VERSION "HNNBNNNYNNNNNNNNNNNNNNNNNNNNNNNNNNNNNNNNNN/4/%%%/4/'%**4NNN///"

NS_ :

BS_:

BU_: AEM BAP_Tester E_Sound FLA Gateway Gateway_PAG ISE MRR_HL MRR_HR NightVision RDK SAK SAK2 SCR STH_MLBevo TopView

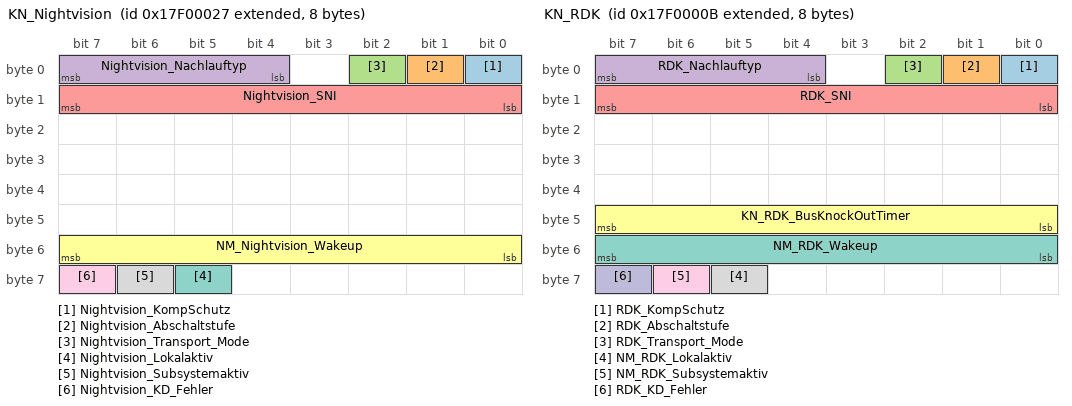
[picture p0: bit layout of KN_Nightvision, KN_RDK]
BO_ 2549088295 KN_Nightvision: 8 NightVision
 SG_ Nightvision_KompSchutz : 0|1@1+ (1.0,0.0) [0.0|1] ""  Vector__XXX
 SG_ Nightvision_Abschaltstufe : 1|1@1+ (1.0,0.0) [0.0|1] ""  Vector__XXX
 SG_ Nightvision_Transport_Mode : 2|1@1+ (1.0,0.0) [0.0|1] ""  Vector__XXX
 SG_ Nightvision_Nachlauftyp : 4|4@1+ (1.0,0.0) [0.0|15] ""  Gateway,Gateway_PAG
 SG_ Nightvision_SNI : 8|8@1+ (1.0,0.0) [0.0|255] ""  Gateway,Gateway_PAG
 SG_ NM_Nightvision_Wakeup : 48|8@1+ (1.0,0.0) [0.0|255] ""  Vector__XXX
 SG_ Nightvision_Lokalaktiv : 61|1@1+ (1.0,0.0) [0.0|1] ""  Vector__XXX
 SG_ Nightvision_Subsystemaktiv : 62|1@1+ (1.0,0.0) [0.0|1] ""  Vector__XXX
 SG_ Nightvision_KD_Fehler : 63|1@1+ (1.0,0.0) [0.0|1] ""  Gateway,Gateway_PAG

BO_ 2549088267 KN_RDK: 8 RDK
 SG_ RDK_KompSchutz : 0|1@1+ (1.0,0.0) [0.0|1] ""  Vector__XXX
 SG_ RDK_Abschaltstufe : 1|1@1+ (1.0,0.0) [0.0|1] ""  Vector__XXX
 SG_ RDK_Transport_Mode : 2|1@1+ (1.0,0.0) [0.0|1] ""  Vector__XXX
 SG_ RDK_Nachlauftyp : 4|4@1+ (1.0,0.0) [0.0|15] ""  Gateway,Gateway_PAG
 SG_ RDK_SNI : 8|8@1+ (1.0,0.0) [0.0|255] ""  Gateway,Gateway_PAG
 SG_ KN_RDK_BusKnockOutTimer : 40|8@1+ (1,0) [0|254] ""  Gateway,Gateway_PAG
 SG_ NM_RDK_Wakeup : 48|8@1+ (1.0,0.0) [0.0|255] ""  Vector__XXX
 SG_ NM_RDK_Lokalaktiv : 61|1@1+ (1.0,0.0) [0.0|1] ""  Gateway,Gateway_PAG
 SG_ NM_RDK_Subsystemaktiv : 62|1@1+ (1.0,0.0) [0.0|1] ""  Vector__XXX
 SG_ RDK_KD_Fehler : 63|1@1+ (1.0,0.0) [0.0|1] ""  Gateway,Gateway_PAG

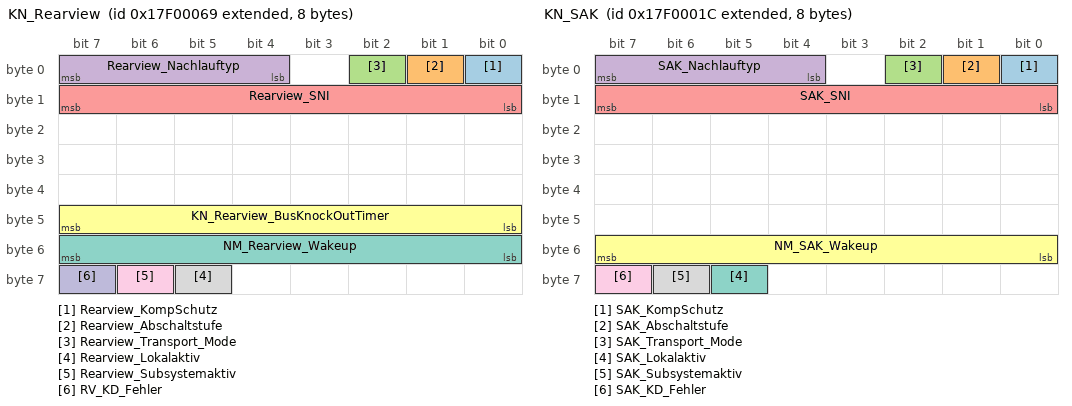
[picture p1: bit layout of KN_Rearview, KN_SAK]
BO_ 2549088361 KN_Rearview: 8 TopView
 SG_ Rearview_KompSchutz : 0|1@1+ (1.0,0.0) [0.0|1] ""  Vector__XXX
 SG_ Rearview_Abschaltstufe : 1|1@1+ (1.0,0.0) [0.0|1] ""  Vector__XXX
 SG_ Rearview_Transport_Mode : 2|1@1+ (1.0,0.0) [0.0|1] ""  Vector__XXX
 SG_ Rearview_Nachlauftyp : 4|4@1+ (1.0,0.0) [0.0|15] ""  Gateway,Gateway_PAG
 SG_ Rearview_SNI : 8|8@1+ (1.0,0.0) [0.0|255] ""  Gateway,Gateway_PAG
 SG_ KN_Rearview_BusKnockOutTimer : 40|8@1+ (1,0) [0|254] ""  Gateway,Gateway_PAG
 SG_ NM_Rearview_Wakeup : 48|8@1+ (1.0,0.0) [0.0|255] ""  Vector__XXX
 SG_ Rearview_Lokalaktiv : 61|1@1+ (1.0,0.0) [0.0|1] ""  Gateway,Gateway_PAG
 SG_ Rearview_Subsystemaktiv : 62|1@1+ (1.0,0.0) [0.0|1] ""  Vector__XXX
 SG_ RV_KD_Fehler : 63|1@1+ (1.0,0.0) [0.0|1] ""  Gateway,Gateway_PAG

BO_ 2549088284 KN_SAK: 8 ISE
 SG_ SAK_KompSchutz : 0|1@1+ (1.0,0.0) [0.0|1] ""  Vector__XXX
 SG_ SAK_Abschaltstufe : 1|1@1+ (1.0,0.0) [0.0|1] ""  Vector__XXX
 SG_ SAK_Transport_Mode : 2|1@1+ (1.0,0.0) [0.0|1] ""  Vector__XXX
 SG_ SAK_Nachlauftyp : 4|4@1+ (1.0,0.0) [0.0|15] ""  Gateway,Gateway_PAG
 SG_ SAK_SNI : 8|8@1+ (1.0,0.0) [0.0|255] ""  Gateway,Gateway_PAG
 SG_ NM_SAK_Wakeup : 48|8@1+ (1.0,0.0) [0.0|255] ""  Vector__XXX
 SG_ SAK_Lokalaktiv : 61|1@1+ (1.0,0.0) [0.0|1] ""  Vector__XXX
 SG_ SAK_Subsystemaktiv : 62|1@1+ (1.0,0.0) [0.0|1] ""  Vector__XXX
 SG_ SAK_KD_Fehler : 63|1@1+ (1.0,0.0) [0.0|1] ""  Gateway,Gateway_PAG

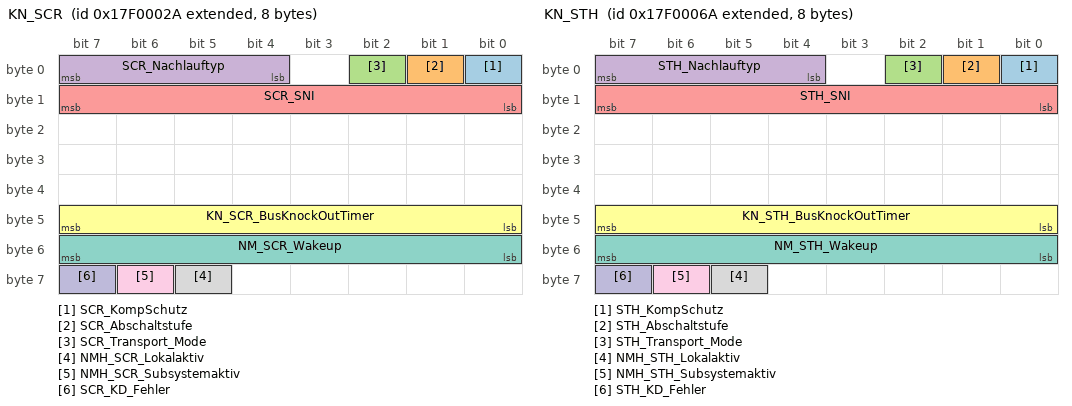
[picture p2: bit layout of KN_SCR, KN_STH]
BO_ 2549088298 KN_SCR: 8 SCR
 SG_ SCR_KompSchutz : 0|1@1+ (1.0,0.0) [0.0|1] ""  Vector__XXX
 SG_ SCR_Abschaltstufe : 1|1@1+ (1.0,0.0) [0.0|1] ""  Vector__XXX
 SG_ SCR_Transport_Mode : 2|1@1+ (1.0,0.0) [0.0|1] ""  Vector__XXX
 SG_ SCR_Nachlauftyp : 4|4@1+ (1.0,0.0) [0.0|15] ""  Gateway,Gateway_PAG
 SG_ SCR_SNI : 8|8@1+ (1.0,0.0) [0.0|255] ""  Gateway,Gateway_PAG
 SG_ KN_SCR_BusKnockOutTimer : 40|8@1+ (1,0) [0|254] ""  Gateway,Gateway_PAG
 SG_ NM_SCR_Wakeup : 48|8@1+ (1.0,0.0) [0.0|255] ""  Vector__XXX
 SG_ NMH_SCR_Lokalaktiv : 61|1@1+ (1.0,0.0) [0.0|1] ""  Gateway,Gateway_PAG
 SG_ NMH_SCR_Subsystemaktiv : 62|1@1+ (1.0,0.0) [0.0|1] ""  Vector__XXX
 SG_ SCR_KD_Fehler : 63|1@1+ (1.0,0.0) [0.0|1] ""  Gateway,Gateway_PAG

BO_ 2549088362 KN_STH: 8 STH_MLBevo
 SG_ STH_KompSchutz : 0|1@1+ (1.0,0.0) [0.0|1] ""  Vector__XXX
 SG_ STH_Abschaltstufe : 1|1@1+ (1.0,0.0) [0.0|1] ""  Vector__XXX
 SG_ STH_Transport_Mode : 2|1@1+ (1.0,0.0) [0.0|1] ""  Vector__XXX
 SG_ STH_Nachlauftyp : 4|4@1+ (1.0,0.0) [0.0|15] ""  Gateway,Gateway_PAG
 SG_ STH_SNI : 8|8@1+ (1.0,0.0) [0.0|255] ""  Gateway,Gateway_PAG
 SG_ KN_STH_BusKnockOutTimer : 40|8@1+ (1,0) [0|254] ""  Gateway,Gateway_PAG
 SG_ NM_STH_Wakeup : 48|8@1+ (1.0,0.0) [0.0|255] ""  Vector__XXX
 SG_ NMH_STH_Lokalaktiv : 61|1@1+ (1.0,0.0) [0.0|1] ""  Gateway,Gateway_PAG
 SG_ NMH_STH_Subsystemaktiv : 62|1@1+ (1.0,0.0) [0.0|1] ""  Gateway,Gateway_PAG
 SG_ STH_KD_Fehler : 63|1@1+ (1.0,0.0) [0.0|1] ""  Gateway,Gateway_PAG

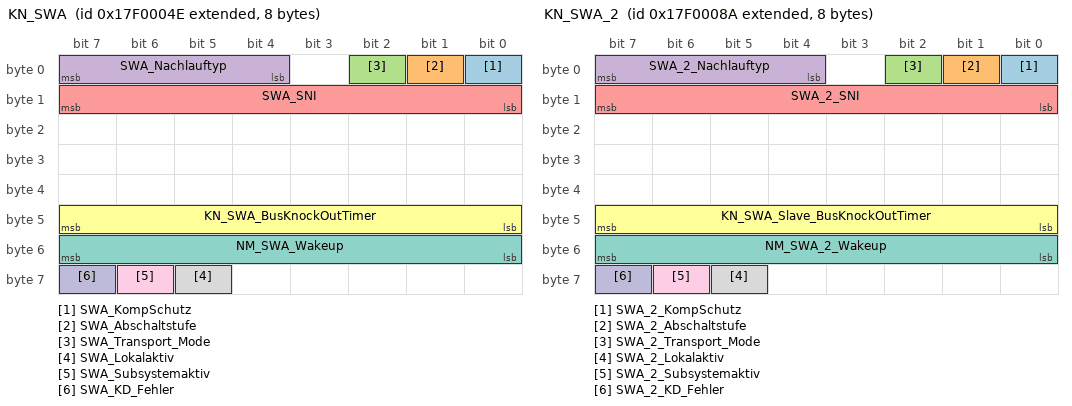
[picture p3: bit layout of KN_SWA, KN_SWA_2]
BO_ 2549088334 KN_SWA: 8 MRR_HR
 SG_ SWA_KompSchutz : 0|1@1+ (1.0,0.0) [0.0|1] ""  Vector__XXX
 SG_ SWA_Abschaltstufe : 1|1@1+ (1.0,0.0) [0.0|1] ""  Vector__XXX
 SG_ SWA_Transport_Mode : 2|1@1+ (1.0,0.0) [0.0|1] ""  Vector__XXX
 SG_ SWA_Nachlauftyp : 4|4@1+ (1.0,0.0) [0.0|15] ""  Gateway,Gateway_PAG
 SG_ SWA_SNI : 8|8@1+ (1.0,0.0) [0.0|255] ""  Gateway,Gateway_PAG
 SG_ KN_SWA_BusKnockOutTimer : 40|8@1+ (1,0) [0|254] ""  Gateway,Gateway_PAG
 SG_ NM_SWA_Wakeup : 48|8@1+ (1.0,0.0) [0.0|255] ""  Vector__XXX
 SG_ SWA_Lokalaktiv : 61|1@1+ (1.0,0.0) [0.0|1] ""  Gateway,Gateway_PAG
 SG_ SWA_Subsystemaktiv : 62|1@1+ (1.0,0.0) [0.0|1] ""  Vector__XXX
 SG_ SWA_KD_Fehler : 63|1@1+ (1.0,0.0) [0.0|1] ""  Gateway,Gateway_PAG

BO_ 2549088394 KN_SWA_2: 8 MRR_HL
 SG_ SWA_2_KompSchutz : 0|1@1+ (1.0,0.0) [0.0|1] ""  Vector__XXX
 SG_ SWA_2_Abschaltstufe : 1|1@1+ (1.0,0.0) [0.0|1] ""  Vector__XXX
 SG_ SWA_2_Transport_Mode : 2|1@1+ (1.0,0.0) [0.0|1] ""  Vector__XXX
 SG_ SWA_2_Nachlauftyp : 4|4@1+ (1.0,0.0) [0.0|15] ""  Gateway,Gateway_PAG
 SG_ SWA_2_SNI : 8|8@1+ (1.0,0.0) [0.0|255] ""  Gateway,Gateway_PAG
 SG_ KN_SWA_Slave_BusKnockOutTimer : 40|8@1+ (1,0) [0|254] ""  Gateway,Gateway_PAG
 SG_ NM_SWA_2_Wakeup : 48|8@1+ (1.0,0.0) [0.0|255] ""  Vector__XXX
 SG_ SWA_2_Lokalaktiv : 61|1@1+ (1.0,0.0) [0.0|1] ""  Gateway,Gateway_PAG
 SG_ SWA_2_Subsystemaktiv : 62|1@1+ (1.0,0.0) [0.0|1] ""  Vector__XXX
 SG_ SWA_2_KD_Fehler : 63|1@1+ (1.0,0.0) [0.0|1] ""  Gateway,Gateway_PAG

BO_ 779 Kombi_01: 8 Gateway
 SG_ KBI_ABS_Lampe : 0|1@1+ (1.0,0.0) [0.0|1] ""  Vector__XXX
 SG_ KBI_ESP_Lampe : 1|1@1+ (1.0,0.0) [0.0|1] ""  TopView
 SG_ KBI_BKL_Lampe : 2|1@1+ (1.0,0.0) [0.0|1] ""  Vector__XXX
 SG_ KBI_Airbag_Lampe : 3|1@1+ (1.0,0.0) [0.0|1] ""  Vector__XXX
 SG_ KBI_SILA_gueltig : 4|1@1+ (1.0,0.0) [0.0|1] ""  Vector__XXX
 SG_ KBI_Lenkung_Lampe : 5|1@1+ (1,0) [0|1] ""  Vector__XXX
 SG_ KBI_Vorglueh_System_Lampe : 6|1@1+ (1.0,0.0) [0.0|1] ""  Vector__XXX
 SG_ KBI_NV_in_Anzeige : 7|1@1+ (1.0,0.0) [0.0|1] ""  NightVision
 SG_ Kombi_01_BZ : 8|4@1+ (1,0) [0|15] ""  Vector__XXX
 SG_ KBI_Anzeigestatus_ACC : 12|1@1+ (1.0,0.0) [0.0|1] ""  Vector__XXX
 SG_ KBI_Anzeigestatus_GRA : 13|2@1+ (1.0,0.0) [0.0|3] ""  Vector__XXX
 SG_ KBI_Tankwarnung : 16|1@1+ (1.0,0.0) [0.0|1] ""  STH_MLBevo
 SG_ KBI_MFA_v_Einheit_01 : 17|1@1+ (1.0,0.0) [0.0|1] ""  RDK
 SG_ KBI_im_Stellgliedtest : 18|1@1+ (1.0,0.0) [0.0|1] ""  Vector__XXX
 SG_ KBI_Anzeigefehler_LDW : 19|2@1+ (1.0,0.0) [0.0|3] ""  Vector__XXX
 SG_ KBI_Tankwarnung_ungueltig : 21|1@1+ (1.0,0.0) [0.0|1] ""  Vector__XXX
 SG_ KBI_Handbremse : 23|1@1+ (1.0,0.0) [0.0|1] ""  Vector__XXX
 SG_ KBI_V_Digital : 24|9@1+ (1,0) [0|511] ""  MRR_HL,MRR_HR,RDK
 SG_ KBI_PLA_in_Anzeige : 33|1@1+ (1.0,0.0) [0.0|1] ""  Vector__XXX
 SG_ KBI_Anzeigefehler_NV : 34|1@1+ (1.0,0.0) [0.0|1] ""  NightVision
 SG_ KBI_Anzeigestatus_LIM : 35|2@1+ (1.0,0.0) [0.0|3] ""  Vector__XXX
 SG_ KBI_ARA_in_Anzeige : 37|1@1+ (1.0,0.0) [0.0|1] ""  Vector__XXX
 SG_ KBI_Taster_Lift : 38|1@1+ (1.0,0.0) [0.0|1] ""  Vector__XXX
 SG_ KBI_Taster_Fahrwerk : 39|1@1+ (1.0,0.0) [0.0|1] ""  Vector__XXX
 SG_ KBI_angez_Geschw : 48|10@1+ (0.32,0) [0.00|325.12] "Unit_KiloMeterPerHour"  MRR_HL,MRR_HR
 SG_ KBI_Einheit_Tacho : 58|1@1+ (1.0,0.0) [0.0|1] ""  Vector__XXX
 SG_ KBI_Konsistenz_ACC : 59|1@1+ (1.0,0.0) [0.0|1] ""  Vector__XXX
 SG_ KBI_Fehler_Anzeige_ACC : 60|1@1+ (1.0,0.0) [0.0|1] ""  Vector__XXX
 SG_ KBI_Anzeigefehler_SWA : 61|2@1+ (1.0,0.0) [0.0|3] ""  MRR_HR
 SG_ KBI_Systemstatus : 63|1@1+ (1.0,0.0) [0.0|1] ""  Vector__XXX

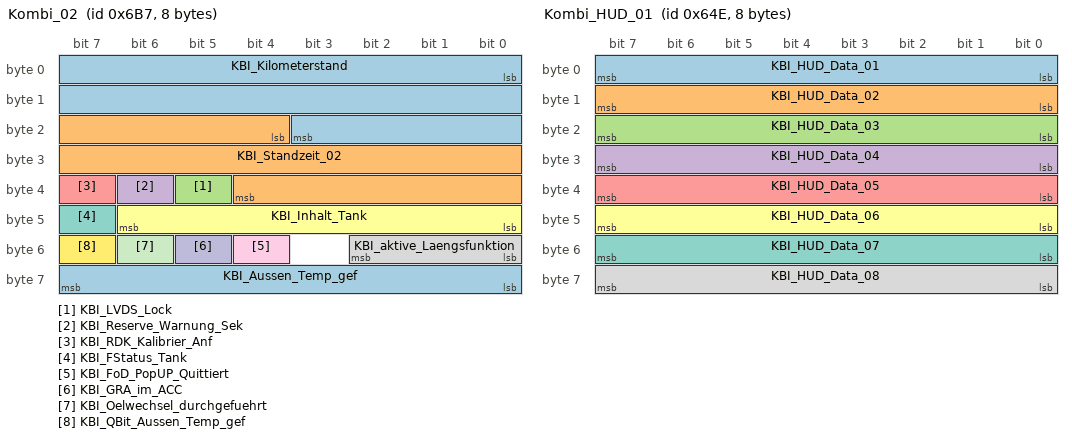
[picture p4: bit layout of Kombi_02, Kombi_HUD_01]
BO_ 1719 Kombi_02: 8 Gateway
 SG_ KBI_Kilometerstand : 0|20@1+ (1,0) [0|1048573] "Unit_KiloMeter"  Vector__XXX
 SG_ KBI_Standzeit_02 : 20|17@1+ (1,0) [0|131068] "Unit_Secon"  STH_MLBevo
 SG_ KBI_LVDS_Lock : 37|1@1+ (1.0,0.0) [0.0|1] ""  Vector__XXX
 SG_ KBI_Reserve_Warnung_Sek : 38|1@1+ (1.0,0.0) [0.0|1] ""  Vector__XXX
 SG_ KBI_RDK_Kalibrier_Anf : 39|1@1+ (1.0,0.0) [0.0|1] ""  RDK
 SG_ KBI_Inhalt_Tank : 40|7@1+ (1,0) [0|125] "Unit_Liter"  STH_MLBevo
 SG_ KBI_FStatus_Tank : 47|1@1+ (1.0,0.0) [0.0|1] ""  STH_MLBevo
 SG_ KBI_aktive_Laengsfunktion : 48|3@1+ (1.0,0.0) [0.0|7] ""  Vector__XXX
 SG_ KBI_FoD_PopUP_Quittiert : 52|1@1+ (1.0,0.0) [0.0|1] ""  Vector__XXX
 SG_ KBI_GRA_im_ACC : 53|1@1+ (1.0,0.0) [0.0|1] ""  Vector__XXX
 SG_ KBI_Oelwechsel_durchgefuehrt : 54|1@1+ (1.0,0.0) [0.0|1] ""  Vector__XXX
 SG_ KBI_QBit_Aussen_Temp_gef : 55|1@1+ (1.0,0.0) [0.0|1] ""  NightVision,RDK,STH_MLBevo
 SG_ KBI_Aussen_Temp_gef : 56|8@1+ (0.5,-50) [-50.0|75.0] "Unit_DegreCelsi"  AEM,NightVision,RDK,SAK2,SCR,STH_MLBevo

BO_ 1614 Kombi_HUD_01: 8 Gateway
 SG_ KBI_HUD_Data_01 : 0|8@1+ (1.0,0.0) [0.0|255] ""  NightVision
 SG_ KBI_HUD_Data_02 : 8|8@1+ (1.0,0.0) [0.0|255] ""  NightVision
 SG_ KBI_HUD_Data_03 : 16|8@1+ (1.0,0.0) [0.0|255] ""  NightVision
 SG_ KBI_HUD_Data_04 : 24|8@1+ (1.0,0.0) [0.0|255] ""  NightVision
 SG_ KBI_HUD_Data_05 : 32|8@1+ (1.0,0.0) [0.0|255] ""  NightVision
 SG_ KBI_HUD_Data_06 : 40|8@1+ (1.0,0.0) [0.0|255] ""  NightVision
 SG_ KBI_HUD_Data_07 : 48|8@1+ (1.0,0.0) [0.0|255] ""  NightVision
 SG_ KBI_HUD_Data_08 : 56|8@1+ (1.0,0.0) [0.0|255] ""  NightVision

BO_ 2549874983 KS_Nightvision_Req: 8 Gateway
 SG_ KS_Nightvision_Req_Data : 0|64@1+ (1.0,0.0) [0.0|18446744073709551615] ""  NightVision

BO_ 2550006055 KS_Nightvision_Resp: 8 NightVision
 SG_ KS_Nightvision_Resp_Data : 0|64@1+ (1.0,0.0) [0.0|18446744073709551615] ""  Gateway,Gateway_PAG

BO_ 2549875082 KS_SWA_2_Req: 8 Gateway
 SG_ KS_SWA_2_Req_Data : 0|64@1+ (1.0,0.0) [0.0|18446744073709551615] ""  MRR_HL

BO_ 2550006154 KS_SWA_2_Resp: 8 MRR_HL
 SG_ KS_SWA_2_Resp_Data : 0|64@1+ (1.0,0.0) [0.0|18446744073709551615] ""  Gateway,Gateway_PAG

BO_ 2549875022 KS_SWA_Req: 8 Gateway
 SG_ KS_SWA_Req_Data : 0|64@1+ (1.0,0.0) [0.0|18446744073709551615] ""  MRR_HR

BO_ 2550006094 KS_SWA_Resp: 8 MRR_HR
 SG_ KS_SWA_Resp_Data : 0|64@1+ (1.0,0.0) [0.0|18446744073709551615] ""  Gateway,Gateway_PAG

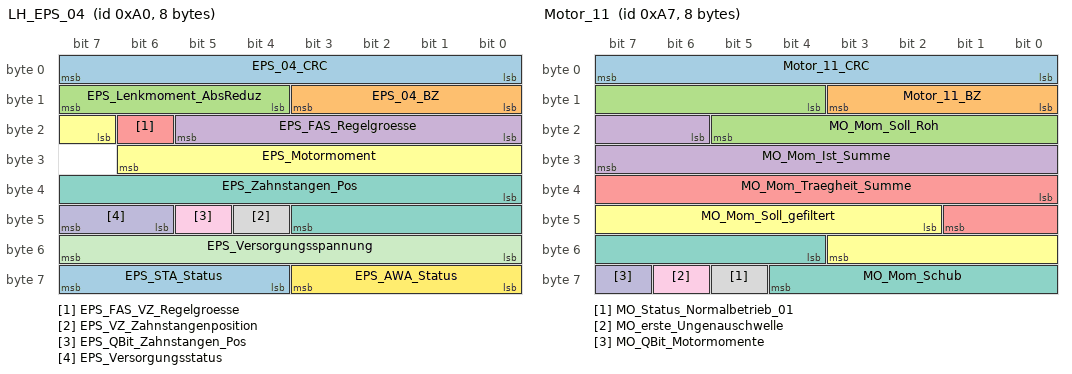
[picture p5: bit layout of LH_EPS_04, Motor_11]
BO_ 160 LH_EPS_04: 8 Gateway
 SG_ EPS_04_CRC : 0|8@1+ (1,0) [0|255] ""  Vector__XXX
 SG_ EPS_04_BZ : 8|4@1+ (1,0) [0|15] ""  Vector__XXX
 SG_ EPS_Lenkmoment_AbsReduz : 12|4@1+ (0.62,0.61) [0.61|8.05] "Unit_NewtoMeter"  TopView
 SG_ EPS_FAS_Regelgroesse : 16|6@1+ (2,0) [0|100] "Unit_PerCent"  Vector__XXX
 SG_ EPS_FAS_VZ_Regelgroesse : 22|1@1+ (1.0,0.0) [0.0|1] ""  Vector__XXX
 SG_ EPS_Motormoment : 23|8@1+ (0.2,-16.2) [-16.0|16.0] "Unit_NewtoMeter"  Vector__XXX
 SG_ EPS_Zahnstangen_Pos : 32|12@1+ (0.02,0) [0.00|81.86] "Unit_MilliMeter"  TopView
 SG_ EPS_VZ_Zahnstangenposition : 44|1@1+ (1.0,0.0) [0.0|1] ""  TopView
 SG_ EPS_QBit_Zahnstangen_Pos : 45|1@1+ (1.0,0.0) [0.0|1] ""  TopView
 SG_ EPS_Versorgungsstatus : 46|2@1+ (1.0,0.0) [0.0|3] ""  Vector__XXX
 SG_ EPS_Versorgungsspannung : 48|8@1+ (0.05,5.05) [5.05|17.70] "Unit_Volt"  Vector__XXX
 SG_ EPS_AWA_Status : 56|4@1+ (1.0,0.0) [0.0|15] ""  Vector__XXX
 SG_ EPS_STA_Status : 60|4@1+ (1.0,0.0) [0.0|15] ""  Vector__XXX

BO_ 981 Licht_Anf_01: 8 Gateway
 SG_ Licht_Anf_01_CRC : 0|8@1+ (1,0) [0|255] ""  Vector__XXX
 SG_ Licht_Anf_01_BZ : 8|4@1+ (1,0) [0|15] ""  Vector__XXX
 SG_ BCM1_Kurvenlicht_links_Anf : 12|1@1+ (1.0,0.0) [0.0|1] ""  Vector__XXX
 SG_ BCM1_Kurvenlicht_rechts_Anf : 13|1@1+ (1.0,0.0) [0.0|1] ""  Vector__XXX
 SG_ BCM1_Standlicht_Anf : 14|1@1+ (1.0,0.0) [0.0|1] ""  Vector__XXX
 SG_ BCM1_Abblendlicht_Anf : 15|1@1+ (1.0,0.0) [0.0|1] ""  Vector__XXX
 SG_ BCM1_Fernlicht_Anf : 16|1@1+ (1.0,0.0) [0.0|1] ""  Vector__XXX
 SG_ BCM1_Nebellicht_Anf : 17|1@1+ (1.0,0.0) [0.0|1] ""  Vector__XXX
 SG_ BCM1_Parklicht_li_Anf : 18|1@1+ (1.0,0.0) [0.0|1] ""  Vector__XXX
 SG_ BCM1_Parklicht_re_Anf : 19|1@1+ (1.0,0.0) [0.0|1] ""  Vector__XXX
 SG_ BCM1_Nebelschluss_Ahg_Anf : 20|1@1+ (1.0,0.0) [0.0|1] ""  Vector__XXX
 SG_ BCM1_Nebelschluss_Fzg_Anf : 21|1@1+ (1.0,0.0) [0.0|1] ""  Vector__XXX
 SG_ BCM1_Schlusslicht_Anf : 22|1@1+ (1.0,0.0) [0.0|1] ""  Vector__XXX
 SG_ BCM_Rueckfahrlicht_Anf : 23|1@1+ (1.0,0.0) [0.0|1] ""  TopView
 SG_ BCM1_Signaturlicht_Anf : 24|1@1+ (1.0,0.0) [0.0|1] ""  Vector__XXX
 SG_ BCM1_Umfeldleuchten_Anf : 25|1@1+ (1.0,0.0) [0.0|1] ""  Vector__XXX
 SG_ BCM1_Tagfahrlicht_Anf : 26|1@1+ (1.0,0.0) [0.0|1] ""  Vector__XXX
 SG_ BCM1_Regenlicht_Anf : 27|1@1+ (1.0,0.0) [0.0|1] ""  Vector__XXX
 SG_ BCM1_Autobahnlicht_Anf : 28|1@1+ (1.0,0.0) [0.0|1] ""  Vector__XXX
 SG_ BCM1_Touristen_Licht_Anf : 29|1@1+ (1.0,0.0) [0.0|1] ""  Vector__XXX
 SG_ BCM1_CH_aktiv : 30|1@1+ (1.0,0.0) [0.0|1] ""  Vector__XXX
 SG_ BCM1_LH_aktiv : 31|1@1+ (1.0,0.0) [0.0|1] ""  Vector__XXX
 SG_ BCM1_Gleitende_Leuchtw_Anf : 32|1@1+ (1.0,0.0) [0.0|1] ""  Vector__XXX
 SG_ BCM1_GLW_Fernlicht_Anf : 33|1@1+ (1.0,0.0) [0.0|1] ""  Vector__XXX
 SG_ BCM1_Adaptive_Lichtvert_Anf : 34|1@1+ (1.0,0.0) [0.0|1] ""  Vector__XXX
 SG_ BCM1_FoD_Sperrung_WiBli : 35|2@1+ (1.0,0.0) [0.0|3] ""  Vector__XXX
 SG_ BCM1_FOD_Sperrung_Animationen_HL : 37|2@1+ (1.0,0.0) [0.0|3] ""  Vector__XXX
 SG_ BCM1_Animationssperrung : 39|1@1+ (1.0,0.0) [0.0|1] ""  Vector__XXX
 SG_ BCM1_CH_LH_aktiv : 40|1@1+ (1.0,0.0) [0.0|1] ""  Vector__XXX
 SG_ BCM1_Allwetterlicht_Anf : 41|1@1+ (1.0,0.0) [0.0|1] ""  Vector__XXX

BO_ 1624 Licht_vorne_01: 8 Gateway
 SG_ Licht_Vorne_01_CRC : 0|8@1+ (1,0) [0|255] ""  Vector__XXX
 SG_ Licht_Vorne_01_BZ : 8|4@1+ (1,0) [0|15] ""  Vector__XXX
 SG_ LV_Standlicht_Anzeige : 12|1@1+ (1.0,0.0) [0.0|1] ""  Vector__XXX
 SG_ LV_Abblendlicht_Anzeige : 13|1@1+ (1.0,0.0) [0.0|1] ""  FLA,NightVision
 SG_ LV_Fernlicht_Anzeige : 14|1@1+ (1.0,0.0) [0.0|1] ""  FLA
 SG_ LV_Nebellicht_Anzeige : 15|1@1+ (1.0,0.0) [0.0|1] ""  FLA
 SG_ LV_Nebelschlusslicht_Anzeige : 16|1@1+ (1.0,0.0) [0.0|1] ""  Vector__XXX
 SG_ LV_Tagfahrlicht_Anzeige : 17|1@1+ (1.0,0.0) [0.0|1] ""  Vector__XXX
 SG_ LV_AFL_aktiv_Anzeige : 18|1@1+ (1.0,0.0) [0.0|1] ""  Vector__XXX
 SG_ LV_AFL_defekt : 19|1@1+ (1.0,0.0) [0.0|1] ""  Vector__XXX
 SG_ LV_Blinker_li_def : 20|1@1+ (1.0,0.0) [0.0|1] ""  Vector__XXX
 SG_ LV_Standlicht_li_def : 21|1@1+ (1.0,0.0) [0.0|1] ""  Vector__XXX
 SG_ LV_Abblendlicht_li_def : 22|1@1+ (1.0,0.0) [0.0|1] ""  NightVision
 SG_ LV_Fernlicht_li_def : 23|1@1+ (1.0,0.0) [0.0|1] ""  Vector__XXX
 SG_ LV_Nebellicht_li_def : 24|1@1+ (1.0,0.0) [0.0|1] ""  Vector__XXX
 SG_ LV_Blk_li_Seite_def : 25|1@1+ (1.0,0.0) [0.0|1] ""  Vector__XXX
 SG_ LV_Tagfahrlicht_li_def : 26|1@1+ (1.0,0.0) [0.0|1] ""  Vector__XXX
 SG_ LV_FLA_aktiv_Anzeige : 27|1@1+ (1.0,0.0) [0.0|1] ""  Vector__XXX
 SG_ LV_FLA_defekt : 28|1@1+ (1.0,0.0) [0.0|1] ""  Vector__XXX
 SG_ LV_FLA_Sensor_blockiert : 29|1@1+ (1.0,0.0) [0.0|1] ""  Vector__XXX
 SG_ LV_Blinker_re_def : 30|1@1+ (1.0,0.0) [0.0|1] ""  Vector__XXX
 SG_ LV_Standlicht_re_def : 31|1@1+ (1.0,0.0) [0.0|1] ""  Vector__XXX
 SG_ LV_Abblendlicht_re_def : 32|1@1+ (1.0,0.0) [0.0|1] ""  NightVision
 SG_ LV_Fernlicht_re_def : 33|1@1+ (1.0,0.0) [0.0|1] ""  Vector__XXX
 SG_ LV_Nebellicht_re_def : 34|1@1+ (1.0,0.0) [0.0|1] ""  Vector__XXX
 SG_ LV_Blk_re_Seite_def : 35|1@1+ (1.0,0.0) [0.0|1] ""  Vector__XXX
 SG_ LV_Tagfahrlicht_re_def : 36|1@1+ (1.0,0.0) [0.0|1] ""  Vector__XXX
 SG_ LV_Aussenlicht_def : 37|1@1+ (1.0,0.0) [0.0|1] ""  Vector__XXX
 SG_ LV_Abblendlicht_TFL_li_def : 38|1@1+ (1.0,0.0) [0.0|1] ""  Vector__XXX
 SG_ LV_Nebellicht_TFL_li_def : 39|1@1+ (1.0,0.0) [0.0|1] ""  Vector__XXX
 SG_ LV_Standlicht_TFL_li_def : 40|1@1+ (1.0,0.0) [0.0|1] ""  Vector__XXX
 SG_ LV_Abblend_Fernlicht_li_def : 41|1@1+ (1.0,0.0) [0.0|1] ""  Vector__XXX
 SG_ LV_Abblendlicht_TFL_re_def : 42|1@1+ (1.0,0.0) [0.0|1] ""  Vector__XXX
 SG_ LV_Nebellicht_TFL_re_def : 43|1@1+ (1.0,0.0) [0.0|1] ""  Vector__XXX
 SG_ LV_Standlicht_TFL_re_def : 44|1@1+ (1.0,0.0) [0.0|1] ""  Vector__XXX
 SG_ LV_Abblend_Fernlicht_re_def : 45|1@1+ (1.0,0.0) [0.0|1] ""  Vector__XXX
 SG_ LV_Abbiegelicht_li_def : 46|1@1+ (1.0,0.0) [0.0|1] ""  Vector__XXX
 SG_ LV_Abbiegelicht_re_def : 47|1@1+ (1.0,0.0) [0.0|1] ""  Vector__XXX
 SG_ BCM1_Linksverkehr : 48|1@1+ (1.0,0.0) [0.0|1] ""  Vector__XXX
 SG_ BCM1_Licht_Dunkelheit_aktiv : 49|1@1+ (1.0,0.0) [0.0|1] ""  NightVision
 SG_ LV_LED_Scheinwerfer_li_def : 50|1@1+ (1.0,0.0) [0.0|1] ""  Vector__XXX
 SG_ LV_LED_Scheinwerfer_re_def : 51|1@1+ (1.0,0.0) [0.0|1] ""  Vector__XXX
 SG_ LV_Blinker_VL_aktiv : 52|1@1+ (1.0,0.0) [0.0|1] ""  Vector__XXX
 SG_ LV_Blinker_VR_aktiv : 53|1@1+ (1.0,0.0) [0.0|1] ""  Vector__XXX
 SG_ LV_MXB_Status_Anzeige : 54|2@1+ (1.0,0.0) [0.0|3] ""  Vector__XXX

BO_ 917 LWR_AFS_01: 8 Gateway
 SG_ AFS_Abbiegelicht_li_Anf : 0|1@1+ (1.0,0.0) [0.0|1] ""  Vector__XXX
 SG_ AFS_Abbiegelicht_re_Anf : 1|1@1+ (1.0,0.0) [0.0|1] ""  Vector__XXX
 SG_ AFS_Abbiegelicht_Dimm_Anf : 2|1@1+ (1.0,0.0) [0.0|1] ""  Vector__XXX
 SG_ AFS_Verfuegbarkeit_GLW : 3|1@1+ (1.0,0.0) [0.0|1] ""  Vector__XXX
 SG_ AFS_Status_adaptive_LV : 4|1@1+ (1.0,0.0) [0.0|1] ""  Vector__XXX
 SG_ AFS_Fernlicht_li_defekt : 5|1@1+ (1.0,0.0) [0.0|1] ""  Vector__XXX
 SG_ AFS_Fernlicht_re_defekt : 6|1@1+ (1.0,0.0) [0.0|1] ""  Vector__XXX
 SG_ AFS_Fernlicht_Status : 7|1@1+ (1.0,0.0) [0.0|1] ""  Vector__XXX
 SG_ LWR_AFS_01_BZ : 8|4@1+ (1,0) [0|15] ""  Vector__XXX
 SG_ AFS_Lampe : 12|1@1+ (1.0,0.0) [0.0|1] ""  Vector__XXX
 SG_ LWR_Lampe : 13|1@1+ (1.0,0.0) [0.0|1] ""  Vector__XXX
 SG_ AFS_Fehlertext : 14|1@1+ (1.0,0.0) [0.0|1] ""  Vector__XXX
 SG_ AFS_LED_Blinkmode : 15|1@1+ (1.0,0.0) [0.0|1] ""  Vector__XXX
 SG_ LWR_Touristenmodus_aktiv : 16|1@1+ (1.0,0.0) [0.0|1] ""  Vector__XXX
 SG_ AFS_Charisma_FahrPr : 17|4@1+ (1.0,0.0) [0.0|15] ""  Vector__XXX
 SG_ AFS_Charisma_Status : 21|2@1+ (1.0,0.0) [0.0|3] ""  Vector__XXX
 SG_ LWR_Sicherheitsposition_re : 23|1@1+ (1.0,0.0) [0.0|1] ""  Vector__XXX
 SG_ AFS_Allwetterlicht : 24|1@1+ (1.0,0.0) [0.0|1] ""  Vector__XXX
 SG_ LWR_Touristenmodus_verbaut : 25|1@1+ (1.0,0.0) [0.0|1] ""  Vector__XXX
 SG_ AFS_adaptive_LV_verbaut : 26|1@1+ (1.0,0.0) [0.0|1] ""  Vector__XXX
 SG_ LWR_Reisemodus_Texte : 27|2@1+ (1.0,0.0) [0.0|3] ""  Vector__XXX
 SG_ GLW_Sensor_blockiert : 29|1@1+ (1.0,0.0) [0.0|1] ""  Vector__XXX
 SG_ AFS_Charisma_Umschaltung : 30|2@1+ (1.0,0.0) [0.0|3] ""  Vector__XXX
 SG_ LWR_Pos_Schrittmotor : 32|8@1+ (0.4,0) [0.0|100.0] "Unit_PerCent"  Vector__XXX
 SG_ LWR_Hoehenwert_VL : 40|8@1+ (1,-127) [-127|126] ""  NightVision,TopView
 SG_ LWR_Hoehenwert_HL : 48|8@1+ (1,-127) [-127|126] ""  NightVision,TopView
 SG_ AFS_Ersatzlicht_Links : 56|1@1+ (1.0,0.0) [0.0|1] ""  Vector__XXX
 SG_ AFS_Ersatzlicht_Rechts : 57|1@1+ (1.0,0.0) [0.0|1] ""  Vector__XXX
 SG_ LWR_AFS_Grundeinstellung : 58|1@1+ (1.0,0.0) [0.0|1] ""  NightVision
 SG_ LWR_AFS_Parametrisierung : 59|1@1+ (1.0,0.0) [0.0|1] ""  Vector__XXX
 SG_ LWR_Initialisierungslauf : 60|1@1+ (1.0,0.0) [0.0|1] ""  Vector__XXX
 SG_ LWR_Sicherheitsposition_li : 61|1@1+ (1.0,0.0) [0.0|1] ""  Vector__XXX
 SG_ LWR_Modus : 62|1@1+ (1.0,0.0) [0.0|1] ""  Vector__XXX

BO_ 1153 MainUnit_01: 8 Gateway
 SG_ ZR_LoGeWa_Event_Kombiwarnung : 0|4@1+ (1.0,0.0) [0.0|15] ""  Vector__XXX
 SG_ Nav_FoD_Status : 4|3@1+ (1.0,0.0) [0.0|7] ""  NightVision
 SG_ MIB_Tongenerator_PH_verfuegbar : 9|3@1+ (1.0,0.0) [0.0|7] ""  Vector__XXX
 SG_ MMI_Counter_Bedienevent : 12|4@1+ (1.0,0.0) [0.0|15] ""  Vector__XXX
 SG_ DSSS_Warning : 16|5@1+ (1.0,0.0) [0.0|31] ""  Vector__XXX
 SG_ ZR_Kindersicherung_RSE : 21|1@1+ (1.0,0.0) [0.0|1] ""  Vector__XXX
 SG_ ZR_RSE_aktivieren : 22|1@1+ (1.0,0.0) [0.0|1] ""  Vector__XXX
 SG_ MMI_SDS_aktiv : 23|1@1+ (1.0,0.0) [0.0|1] ""  Vector__XXX
 SG_ MU_SecondDisplay : 24|3@1+ (1.0,0.0) [0.0|7] ""  Vector__XXX
 SG_ MMI_Telefon_aktiv : 27|1@1+ (1.0,0.0) [0.0|1] ""  Vector__XXX
 SG_ ZR_Sta_Inszenierung : 29|2@1+ (1.0,0.0) [0.0|3] ""  Vector__XXX
 SG_ MMI_Gauges_active : 31|1@1+ (1.0,0.0) [0.0|1] ""  Vector__XXX
 SG_ MU_Update_Time : 32|8@1+ (0.1,0) [0.0|25.5] "Unit_Hours"  Vector__XXX
 SG_ ZR_MXB_Manoever_Ansage : 42|2@1+ (1.0,0.0) [0.0|3] ""  Vector__XXX
 SG_ ZR_LAPP_Sondermodus_Status : 44|2@1+ (1.0,0.0) [0.0|3] ""  Vector__XXX
 SG_ MMI_StartStopp_Info : 46|2@1+ (1.0,0.0) [0.0|3] ""  Vector__XXX
 SG_ ZR_Parken_Sondermodus : 48|4@1+ (1.0,0.0) [0.0|15] ""  Vector__XXX
 SG_ ZR_Rundenbewertung : 52|4@1+ (1.0,0.0) [0.0|15] ""  Vector__XXX
 SG_ ZR_Rundenfortschritt : 56|8@1+ (0.5,0) [0.0|100.0] "Unit_PerCent"  Vector__XXX

BO_ 1600 Motor_07: 8 Gateway
 SG_ MO_QBit_Ansaugluft_Temp : 0|1@1+ (1.0,0.0) [0.0|1] ""  Vector__XXX
 SG_ MO_QBit_Oel_Temp : 1|1@1+ (1.0,0.0) [0.0|1] ""  Vector__XXX
 SG_ MO_QBit_Kuehlmittel_Temp : 2|1@1+ (1.0,0.0) [0.0|1] ""  STH_MLBevo
 SG_ MO_KL15_Abschaltempfehlung : 3|1@1+ (1.0,0.0) [0.0|1] ""  Vector__XXX
 SG_ MO_HYB_Fehler_HV_Netz : 4|1@1+ (1.0,0.0) [0.0|1] ""  Vector__XXX
 SG_ MO_aktives_Getriebeheizen : 5|1@1+ (1.0,0.0) [0.0|1] ""  Vector__XXX
 SG_ MO_Absperrventil_oeffnen : 6|2@1+ (1.0,0.0) [0.0|3] ""  STH_MLBevo
 SG_ MO_Ansaugluft_Temp : 8|8@1+ (0.75,-48) [-48.00|141.75] "Unit_DegreCelsi"  Vector__XXX
 SG_ MO_Oel_Temp : 16|8@1+ (1,-60) [-60|192] "Unit_DegreCelsi"  AEM
 SG_ MO_Kuehlmittel_Temp : 24|8@1+ (0.75,-48) [-48.00|141.75] "Unit_DegreCelsi"  AEM,STH_MLBevo
 SG_ MO_Hoeheninfo : 32|8@1+ (0.00781,0) [0.00000|1.98374] ""  STH_MLBevo
 SG_ MO_Kennfeldk : 40|1@1+ (1.0,0.0) [0.0|1] ""  Vector__XXX
 SG_ MO_Versionsinfo_02 : 41|5@1+ (1.0,0.0) [0.0|31] ""  Vector__XXX
 SG_ MO_QBit_Hoeheninfo : 46|1@1+ (1.0,0.0) [0.0|1] ""  Vector__XXX
 SG_ MO_Getriebe_kuehlen : 47|1@1+ (1.0,0.0) [0.0|1] ""  Vector__XXX
 SG_ MO_Mom_Traegheit_02 : 48|5@1+ (0.01,0) [0.00|0.31] "Unit_KiloGramMeterSquar"  Vector__XXX
 SG_ MO_Heizungspumpenansteuerung : 53|4@1+ (10,0) [0|100] "Unit_PerCent"  STH_MLBevo
 SG_ MO_SpannungsAnf : 57|1@1+ (1.0,0.0) [0.0|1] ""  Vector__XXX
 SG_ MO_Nachlaufzeit_Heizungspumpe : 58|6@1+ (15,0) [0|945] "Unit_Secon"  STH_MLBevo

BO_ 167 Motor_11: 8 Gateway
 SG_ Motor_11_CRC : 0|8@1+ (1,0) [0|255] ""  Vector__XXX
 SG_ Motor_11_BZ : 8|4@1+ (1,0) [0|15] ""  Vector__XXX
 SG_ MO_Mom_Soll_Roh : 12|10@1+ (1,-509) [-509|509] ""  Vector__XXX
 SG_ MO_Mom_Ist_Summe : 22|10@1+ (1,-509) [-509|509] ""  AEM,E_Sound,ISE,SAK,SAK2
 SG_ MO_Mom_Traegheit_Summe : 32|10@1+ (1,-509) [-509|509] ""  Vector__XXX
 SG_ MO_Mom_Soll_gefiltert : 42|10@1+ (1,-509) [-509|509] ""  Vector__XXX
 SG_ MO_Mom_Schub : 52|9@1+ (1,-509) [-509|0] ""  Vector__XXX
 SG_ MO_Status_Normalbetrieb_01 : 61|1@1+ (1.0,0.0) [0.0|1] ""  Vector__XXX
 SG_ MO_erste_Ungenauschwelle : 62|1@1+ (1.0,0.0) [0.0|1] ""  Vector__XXX
 SG_ MO_QBit_Motormomente : 63|1@1+ (1.0,0.0) [0.0|1] ""  AEM

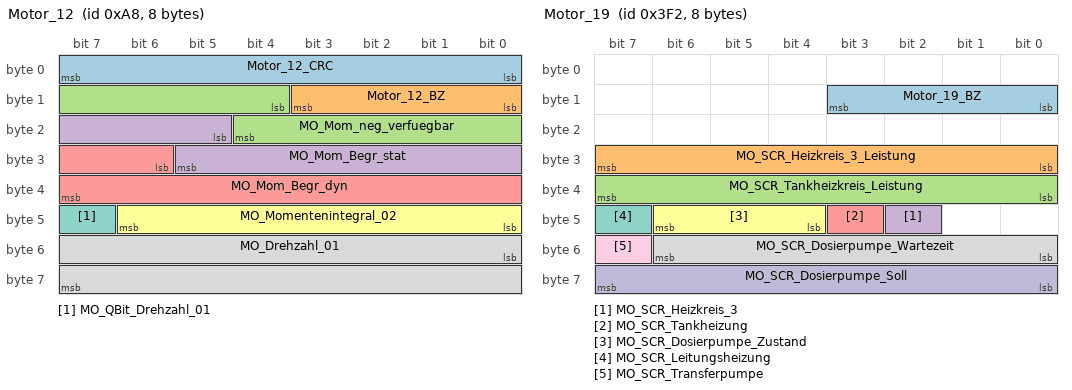
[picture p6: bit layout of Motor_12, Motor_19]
BO_ 168 Motor_12: 8 Gateway
 SG_ Motor_12_CRC : 0|8@1+ (1,0) [0|255] ""  Vector__XXX
 SG_ Motor_12_BZ : 8|4@1+ (1,0) [0|15] ""  Vector__XXX
 SG_ MO_Mom_neg_verfuegbar : 12|9@1+ (1,-509) [-509|0] ""  Vector__XXX
 SG_ MO_Mom_Begr_stat : 21|9@1+ (1,0) [0|509] ""  Vector__XXX
 SG_ MO_Mom_Begr_dyn : 30|10@1+ (1,-509) [-509|509] ""  Vector__XXX
 SG_ MO_Momentenintegral_02 : 40|7@1+ (1,0) [0|100] "Unit_PerCent"  Vector__XXX
 SG_ MO_QBit_Drehzahl_01 : 47|1@1+ (1.0,0.0) [0.0|1] ""  AEM,SCR,STH_MLBevo
 SG_ MO_Drehzahl_01 : 48|16@1+ (0.25,0) [0.00|16383.00] "Unit_MinutInver"  AEM,E_Sound,ISE,SAK,SAK2,SCR,STH_MLBevo

BO_ 958 Motor_14: 8 Gateway
 SG_ Motor_14_CRC : 0|8@1+ (1,0) [0|255] ""  Vector__XXX
 SG_ Motor_14_BZ : 8|4@1+ (1,0) [0|15] ""  Vector__XXX
 SG_ MO_StartStopp_Status : 12|2@1+ (1.0,0.0) [0.0|3] ""  AEM,SCR
 SG_ MO_StartStopp_Wiederstart : 14|1@1+ (1.0,0.0) [0.0|1] ""  AEM,FLA,SCR,STH_MLBevo
 SG_ MO_StartStopp_Motorstopp : 15|1@1+ (1.0,0.0) [0.0|1] ""  AEM,NightVision,SCR,STH_MLBevo
 SG_ MO_Freig_Reku : 16|2@1+ (1.0,0.0) [0.0|3] ""  Vector__XXX
 SG_ MO_Kl_75 : 18|1@1+ (1.0,0.0) [0.0|1] ""  AEM,FLA,SCR
 SG_ MO_Kl_50 : 19|1@1+ (1.0,0.0) [0.0|1] ""  AEM
 SG_ MO_Gangposition : 20|4@1+ (1.0,0.0) [0.0|15] ""  E_Sound,FLA,ISE,NightVision,SAK,SAK2
 SG_ MO_StartStopp_Fahrerwunsch : 24|2@1+ (1.0,0.0) [0.0|3] ""  AEM,SCR
 SG_ MO_HYB_Fahrbereitschaft : 26|1@1+ (1.0,0.0) [0.0|1] ""  E_Sound,ISE
 SG_ MO_Ext_E_Fahrt_aktiv : 27|1@1+ (1.0,0.0) [0.0|1] ""  Vector__XXX
 SG_ MO_Fahrer_bremst : 28|1@1+ (1.0,0.0) [0.0|1] ""  Vector__XXX
 SG_ MO_QBit_Fahrer_bremst : 29|1@1+ (1.0,0.0) [0.0|1] ""  Vector__XXX
 SG_ MO_BLS : 30|1@1+ (1.0,0.0) [0.0|1] ""  Vector__XXX
 SG_ MO_Konsistenz_Bremsped : 31|1@1+ (1.0,0.0) [0.0|1] ""  Vector__XXX
 SG_ MO_KomFehler_ESP : 32|1@1+ (1.0,0.0) [0.0|1] ""  Vector__XXX
 SG_ MO_Klima_Eingr : 33|2@1+ (1.0,0.0) [0.0|3] ""  Vector__XXX
 SG_ MO_Aussp_Anlass : 35|1@1+ (1.0,0.0) [0.0|1] ""  Vector__XXX
 SG_ MO_Freig_Anlass : 36|1@1+ (1.0,0.0) [0.0|1] ""  Vector__XXX
 SG_ MO_Kuppl_schalter : 37|1@1+ (1.0,0.0) [0.0|1] ""  SAK,SAK2
 SG_ MO_Interlock : 38|1@1+ (1.0,0.0) [0.0|1] ""  Vector__XXX
 SG_ MO_Motor_laeuft : 39|1@1+ (1.0,0.0) [0.0|1] ""  AEM,STH_MLBevo
 SG_ MO_Kickdown : 40|1@1+ (1.0,0.0) [0.0|1] ""  Vector__XXX
 SG_ MO_QBit_KL_75 : 41|1@1+ (1.0,0.0) [0.0|1] ""  SCR
 SG_ MO_EKlKomLeiRed : 42|2@1+ (1.0,0.0) [0.0|3] ""  Vector__XXX
 SG_ MO_Handshake_STH : 44|1@1+ (1.0,0.0) [0.0|1] ""  STH_MLBevo
 SG_ MO_BKV_Unterdruckwarnung : 45|1@1+ (1.0,0.0) [0.0|1] ""  Vector__XXX
 SG_ MO_Freigabe_Segeln : 46|1@1+ (1.0,0.0) [0.0|1] ""  Vector__XXX
 SG_ MO_PTC_Status : 47|3@1+ (1.0,0.0) [0.0|7] ""  Vector__XXX
 SG_ MO_QBit_Gangposition : 50|1@1+ (1.0,0.0) [0.0|1] ""  Vector__XXX
 SG_ MO_Signalquelle_Gangposition : 51|1@1+ (1.0,0.0) [0.0|1] ""  Vector__XXX
 SG_ MO_Remotestart_Betrieb : 52|1@1+ (1.0,0.0) [0.0|1] ""  Vector__XXX
 SG_ MO_Remotestart_moeglich : 53|1@1+ (1.0,0.0) [0.0|1] ""  Vector__XXX
 SG_ MO_FMAus_aktiv : 55|1@1+ (1.0,0.0) [0.0|1] ""  Vector__XXX
 SG_ MO_FMAus_Startvariante : 56|2@1+ (1.0,0.0) [0.0|3] ""  Vector__XXX
 SG_ MO_BMS_NV_Anf_stuetzen : 58|1@1+ (1.0,0.0) [0.0|1] ""  Vector__XXX
 SG_ MO_Zylinderabschaltung : 59|2@1+ (1.0,0.0) [0.0|3] ""  AEM,SAK,SAK2
 SG_ MO_HYB_VM_aktiv : 61|1@1+ (1.0,0.0) [0.0|1] ""  E_Sound,ISE,SAK,SAK2
 SG_ MO_StartVorauss_erfuellt : 62|2@1+ (1.0,0.0) [0.0|3] ""  Vector__XXX

BO_ 1648 Motor_18: 8 Gateway
 SG_ MO_max_Ladedruck : 0|6@1+ (0.1,0) [0.0|6.3] "Unit_Bar"  Vector__XXX
 SG_ MO_ANC_Kennfeld_Anf : 6|2@1+ (1.0,0.0) [0.0|3] ""  Vector__XXX
 SG_ MO_Bremslicht_Reku : 8|1@1+ (1.0,0.0) [0.0|1] ""  Vector__XXX
 SG_ MO_StartStopp_PopUp : 9|2@1+ (1.0,0.0) [0.0|3] ""  Vector__XXX
 SG_ MO1_Sperr_Info_WFS : 11|1@1+ (1.0,0.0) [0.0|1] ""  Vector__XXX
 SG_ MO1_Freigabe_Info_WFS : 12|1@1+ (1.0,0.0) [0.0|1] ""  Vector__XXX
 SG_ MO_EPCL : 13|3@1+ (1.0,0.0) [0.0|7] ""  Vector__XXX
 SG_ MO_Zylabsch_Texte_02 : 16|4@1+ (1.0,0.0) [0.0|15] ""  Vector__XXX
 SG_ MO_Fahrzeugtyp : 20|3@1+ (1.0,0.0) [0.0|7] ""  Vector__XXX
 SG_ MO_NMAX_Schaltanzeige : 23|9@1+ (25,0) [0|12775] "Unit_MinutInver"  Vector__XXX
 SG_ MO_Abstellzeit : 32|8@1+ (8,0) [0|2024] "Unit_Minut"  SCR
 SG_ MO_Abstellzeit_Status : 40|2@1+ (1.0,0.0) [0.0|3] ""  SCR
 SG_ MO1_Freigabe_Verfallsinfo_WFS : 42|1@1+ (1.0,0.0) [0.0|1] ""  Vector__XXX
 SG_ MO_Hybrid_StartStopp_LED : 43|2@1+ (1.0,0.0) [0.0|3] ""  Vector__XXX
 SG_ MO_Fehler_Zylabsch : 45|2@1+ (1.0,0.0) [0.0|3] ""  Vector__XXX
 SG_ MO_Anzahl_Abgesch_Zyl : 47|3@1+ (1.0,0.0) [0.0|7] ""  Vector__XXX
 SG_ MO_Zylabsch_Texte : 50|2@1+ (1.0,0.0) [0.0|3] ""  Vector__XXX
 SG_ MO_Ethanol_BS_Texte : 52|3@1+ (1.0,0.0) [0.0|7] ""  Vector__XXX
 SG_ MO_Drehzahl_Warnung : 55|1@1+ (1.0,0.0) [0.0|1] ""  Vector__XXX
 SG_ MO_obere_Drehzahlgrenze : 56|8@1+ (50,0) [50|12750] "Unit_MinutInver"  Vector__XXX

BO_ 1010 Motor_19: 8 Gateway
 SG_ Motor_19_BZ : 8|4@1+ (1,0) [0|15] ""  SCR
 SG_ MO_SCR_Heizkreis_3_Leistung : 24|8@1+ (1,0) [0|150] "Unit_Watt"  SCR
 SG_ MO_SCR_Tankheizkreis_Leistung : 32|8@1+ (1,0) [0|150] "Unit_Watt"  SCR
 SG_ MO_SCR_Heizkreis_3 : 42|1@1+ (1.0,0.0) [0.0|1] ""  SCR
 SG_ MO_SCR_Tankheizung : 43|1@1+ (1.0,0.0) [0.0|1] ""  SCR
 SG_ MO_SCR_Dosierpumpe_Zustand : 44|3@1+ (1.0,0.0) [0.0|7] ""  SCR
 SG_ MO_SCR_Leitungsheizung : 47|1@1+ (1.0,0.0) [0.0|1] ""  SCR
 SG_ MO_SCR_Dosierpumpe_Wartezeit : 48|7@1+ (1,0) [0|120] "Unit_Secon"  SCR
 SG_ MO_SCR_Transferpumpe : 55|1@1+ (1.0,0.0) [0.0|1] ""  Vector__XXX
 SG_ MO_SCR_Dosierpumpe_Soll : 56|8@1+ (0.4,0) [0.0|100.0] "Unit_PerCent"  SCR

BO_TX_BU_ 2549088284 :ISE,SAK;
BO_TX_BU_ 779 :Gateway,Gateway_PAG;
BO_TX_BU_ 1719 :Gateway,Gateway_PAG;
BO_TX_BU_ 1614 :Gateway,Gateway_PAG;
BO_TX_BU_ 2549874983 :Gateway,Gateway_PAG;
BO_TX_BU_ 2549875082 :Gateway,Gateway_PAG;
BO_TX_BU_ 2549875022 :Gateway,Gateway_PAG;
BO_TX_BU_ 160 :Gateway,Gateway_PAG;
BO_TX_BU_ 981 :Gateway,Gateway_PAG;
BO_TX_BU_ 1624 :Gateway,Gateway_PAG;
BO_TX_BU_ 917 :Gateway,Gateway_PAG;
BO_TX_BU_ 1153 :Gateway,Gateway_PAG;
BO_TX_BU_ 1600 :Gateway,Gateway_PAG;
BO_TX_BU_ 167 :Gateway,Gateway_PAG;
BO_TX_BU_ 168 :Gateway,Gateway_PAG;
BO_TX_BU_ 958 :Gateway,Gateway_PAG;
BO_TX_BU_ 1648 :Gateway,Gateway_PAG;
BO_TX_BU_ 1010 :Gateway,Gateway_PAG;
CM_ BO_ 779 "MQB";
CM_ BO_ 917 "MLB";
CM_ BO_ 1600 "ab MQB mit QBit Höheneinfo und MO_Versionsinfo_02";
CM_ BO_ 168 "Teil 2 neue Momentenschnittstelle MLB";
CM_ BO_ 1648 "Kombischnittstelle";
CM_ BO_ 1010 "SCR-Schnittstelle";

CM_ SG_ 2549088295 Nightvision_Abschaltstufe "Funktionseinschränkung aufgrund aktiver Abschaltstufe";
CM_ SG_ 2549088295 Nightvision_KD_Fehler "Bei gesetztem Bit ist mindestens ein Kundendienstfehler eingetragen";
CM_ SG_ 2549088295 Nightvision_KompSchutz "Funktionseinschränkung aufgrund Komponentenschutz aktiv";
CM_ SG_ 2549088295 Nightvision_Lokalaktiv "Zeigt an ob das SG nach Klemme15 AUS und nach entsprechender MAX Aktivzeit noch aktiv war";
CM_ SG_ 2549088295 Nightvision_Nachlauftyp "Abgebildet wird die von der Hardware vorgegebene Möglichkeit, die Kommunikation nach Klemme 15 = AUS aufrecht zu erhalten. Es wird ein Init-Wert gesendet.
0 = Kommunikation nur bei KL15=EIN (kein Nachlauf, nicht weckfähig)
1 = Kommunikation nach KL15=AU";
CM_ SG_ 2549088295 Nightvision_SNI "Das Signal beinhaltet den Source Node Identifier (Knotenadresse, die auch in der Abbildungsvorschrift zur CAN-ID für die NM-High Botschaft verwendet wird).";
CM_ SG_ 2549088295 Nightvision_Subsystemaktiv "Zeigt an ob ein Subsystem des SGs nach Klemme15 AUS und nach entsprechender MAX Aktivzeit noch aktiv war";
CM_ SG_ 2549088295 Nightvision_Transport_Mode "Funktionseinschränkung aufgrund aktivem Transport Mode und/oder Transport Schutz";
CM_ SG_ 2549088295 NM_Nightvision_Wakeup "enthält die Weckursache; stehen mehrere Weckursachen parallel an, dann muss der kleinste Wert übertragen werden";

CM_ SG_ 2549088267 KN_RDK_BusKnockOutTimer "Ausgabe des BusKnockOut-Timer in der Knotenbotschaft";
CM_ SG_ 2549088267 NM_RDK_Lokalaktiv "Zeigt an ob das SG nach Klemme15 AUS und nach entsprechender MAX Aktivzeit noch aktiv war";
CM_ SG_ 2549088267 NM_RDK_Subsystemaktiv "Zeigt an ob ein Subsystem des SGs nach Klemme15 AUS und nach entsprechender MAX Aktivzeit noch aktiv war";
CM_ SG_ 2549088267 NM_RDK_Wakeup "enthält die Weckursache; stehen mehrere Weckursachen parallel an, dann muss der kleinste Wert übertragen werden";
CM_ SG_ 2549088267 RDK_Abschaltstufe "Funktionseinschränkung aufgrund aktiver Abschaltstufe";
CM_ SG_ 2549088267 RDK_KD_Fehler "Bit wird nur bedient, wenn RDK am Komfort-CAN verbaut ist! Wenn RKA am Dashboard-CAN (im ESP) vorhanden ist, dann darf das KD-Bit vom ESP-Steuergerät nie mit 0x1 bedient, es muss immer mit Null gesendet werden. Gateway darf Signal zur Verbaukontrolle nur ";
CM_ SG_ 2549088267 RDK_KompSchutz "Funktionseinschränkung aufgrund Komponentenschutz aktiv";
CM_ SG_ 2549088267 RDK_Nachlauftyp "Abgebildet wird die von der Hardware vorgegebene Möglichkeit, die Kommunikation nach Klemme 15 = AUS aufrecht zu erhalten. Es wird ein Init-Wert gesendet.
0 = Kommunikation nur bei KL15=EIN (kein Nachlauf, nicht weckfähig)
1 = Kommunikation nach KL15=AU";
CM_ SG_ 2549088267 RDK_SNI "Das Signal beinhaltet den Source Node Identifier (Knotenadresse, die auch in der Abbildungsvorschrift zur CAN-ID für die NM-High Botschaft verwendet wird).";
CM_ SG_ 2549088267 RDK_Transport_Mode "Funktionseinschränkung aufgrund aktivem Transport Mode und/oder Transport Schutz";

CM_ SG_ 2549088361 KN_Rearview_BusKnockOutTimer "Ausgabe des BusKnockOut-Timer in der Knotenbotschaft";
CM_ SG_ 2549088361 NM_Rearview_Wakeup "enthält die Weckursache; stehen mehrere Weckursachen parallel an, dann muss der kleinste Wert übertragen werden";
CM_ SG_ 2549088361 Rearview_Abschaltstufe "Funktionseinschränkung aufgrund aktiver Abschaltstufe";
CM_ SG_ 2549088361 Rearview_KompSchutz "Funktionseinschränkung aufgrund Komponentenschutz aktiv";
CM_ SG_ 2549088361 Rearview_Lokalaktiv "Zeigt an ob das SG nach Klemme15 AUS und nach entsprechender MAX Aktivzeit noch aktiv war";
CM_ SG_ 2549088361 Rearview_Nachlauftyp "Abgebildet wird die von der Hardware vorgegebene Möglichkeit, die Kommunikation nach Klemme 15 = AUS aufrecht zu erhalten. Es wird ein Init-Wert gesendet.
0 = Kommunikation nur bei KL15=EIN (kein Nachlauf, nicht weckfähig)
1 = Kommunikation nach KL15=AU";
CM_ SG_ 2549088361 Rearview_SNI "Das Signal beinhaltet den Source Node Identifier (Knotenadresse, die auch in der Abbildungsvorschrift zur CAN-ID für die NM-High Botschaft verwendet wird).";
CM_ SG_ 2549088361 Rearview_Subsystemaktiv "Zeigt an ob ein Subsystem des SGs nach Klemme15 AUS und nach entsprechender MAX Aktivzeit noch aktiv war";
CM_ SG_ 2549088361 Rearview_Transport_Mode "Funktionseinschränkung aufgrund aktivem Transport Mode und/oder Transport Schutz";
CM_ SG_ 2549088361 RV_KD_Fehler "Status Kundendienstfehlerspeichereinträge";

CM_ SG_ 2549088284 NM_SAK_Wakeup "enthält die Weckursache; stehen mehrere Weckursachen parallel an, dann muss der kleinste Wert übertragen werden";
CM_ SG_ 2549088284 SAK_Abschaltstufe "Funktionseinschränkung aufgrund aktiver Abschaltstufe";
CM_ SG_ 2549088284 SAK_KD_Fehler "Bei gesetztem Bit ist mindestens ein Kundendienstfehler eingetragen";
CM_ SG_ 2549088284 SAK_KompSchutz "Funktionseinschränkung aufgrund Komponentenschutz aktiv";
CM_ SG_ 2549088284 SAK_Lokalaktiv "Zeigt an ob das SG nach Klemme15 AUS und nach entsprechender MAX Aktivzeit noch aktiv war";
CM_ SG_ 2549088284 SAK_Nachlauftyp "Abgebildet wird die von der Hardware vorgegebene Möglichkeit, die Kommunikation nach Klemme 15 = AUS aufrecht zu erhalten. Es wird ein Init-Wert gesendet.
0 = Kommunikation nur bei KL15=EIN (kein Nachlauf, nicht weckfähig)
1 = Kommunikation nach KL15=AU";
CM_ SG_ 2549088284 SAK_SNI "Das Signal beinhaltet den Source Node Identifier (Knotenadresse, die auch in der Abbildungsvorschrift zur CAN-ID für die NM-High Botschaft verwendet wird).";
CM_ SG_ 2549088284 SAK_Subsystemaktiv "Zeigt an ob ein Subsystem des SGs nach Klemme15 AUS und nach entsprechender MAX Aktivzeit noch aktiv war";
CM_ SG_ 2549088284 SAK_Transport_Mode "Funktionseinschränkung aufgrund aktivem Transport Mode und/oder Transport Schutz";

CM_ SG_ 2549088298 KN_SCR_BusKnockOutTimer "Ausgabe des BusKnockOut-Timer in der Knotenbotschaft";
CM_ SG_ 2549088298 NM_SCR_Wakeup "enthält die Weckursache; stehen mehrere Weckursachen parallel an, dann muss der kleinste Wert übertragen werden";
CM_ SG_ 2549088298 NMH_SCR_Lokalaktiv "Zeigt an ob Steuergerät lokal aktiv war";
CM_ SG_ 2549088298 NMH_SCR_Subsystemaktiv "Zeigt an ob ein Subsystem des SGs nach Klemme15 AUS und nach entsprechender MAX Aktivzeit noch aktiv war";
CM_ SG_ 2549088298 SCR_Abschaltstufe "Funktionseinschränkung aufgrund aktiver Abschaltstufe";
CM_ SG_ 2549088298 SCR_KompSchutz "Funktionseinschränkung aufgrund Komponentenschutz aktiv";
CM_ SG_ 2549088298 SCR_Nachlauftyp "Abgebildet wird die von der Hardware vorgegebene Möglichkeit, die Kommunikation nach Klemme 15 = AUS aufrecht zu erhalten. Es wird ein Init-Wert gesendet.
0 = Kommunikation nur bei KL15=EIN (kein Nachlauf, nicht weckfähig)
1 = Kommunikation nach KL15=AU";
CM_ SG_ 2549088298 SCR_SNI "Das Signal beinhaltet den Source Node Identifier (Knotenadresse, die auch in der Abbildungsvorschrift zur CAN-ID für die NM-High Botschaft verwendet wird).";
CM_ SG_ 2549088298 SCR_Transport_Mode "Funktionseinschränkung aufgrund aktivem Transport Mode und/oder Transport Schutz";

CM_ SG_ 2549088362 KN_STH_BusKnockOutTimer "Ausgabe des BusKnockOut-Timer in der Knotenbotschaft";
CM_ SG_ 2549088362 NM_STH_Wakeup "enthält die Weckursache; stehen mehrere Weckursachen parallel an, dann muss der kleinste Wert übertragen werden";
CM_ SG_ 2549088362 NMH_STH_Lokalaktiv "Zeigt an ob das SG nach Klemme15 AUS und nach entsprechender MAX Aktivzeit noch aktiv war";
CM_ SG_ 2549088362 NMH_STH_Subsystemaktiv "Zeigt an ob ein Subsystem des SGs nach Klemme15 AUS und nach entsprechender MAX Aktivzeit noch aktiv war";
CM_ SG_ 2549088362 STH_Abschaltstufe "Funktionseinschränkung aufgrund aktiver Abschaltstufe";
CM_ SG_ 2549088362 STH_KompSchutz "Funktionseinschränkung aufgrund Komponentenschutz aktiv";
CM_ SG_ 2549088362 STH_Nachlauftyp "Abgebildet wird die von der Hardware vorgegebene Möglichkeit, die Kommunikation nach Klemme 15 = AUS aufrecht zu erhalten. Es wird ein Init-Wert gesendet.
0 = Kommunikation nur bei KL15=EIN (kein Nachlauf, nicht weckfähig)
1 = Kommunikation nach KL15=AU";
CM_ SG_ 2549088362 STH_SNI "Das Signal beinhaltet den Source Node Identifier (Knotenadresse, die auch in der Abbildungsvorschrift zur CAN-ID für die NM-High Botschaft verwendet wird).";
CM_ SG_ 2549088362 STH_Transport_Mode "Funktionseinschränkung aufgrund aktivem Transport Mode und/oder Transport Schutz";

CM_ SG_ 2549088334 KN_SWA_BusKnockOutTimer "Ausgabe des BusKnockOut-Timer in der Knotenbotschaft";
CM_ SG_ 2549088334 NM_SWA_Wakeup "enthält die Weckursache; stehen mehrere Weckursachen parallel an, dann muss der kleinste Wert übertragen werden";
CM_ SG_ 2549088334 SWA_Abschaltstufe "Funktionseinschränkung aufgrund aktiver Abschaltstufe";
CM_ SG_ 2549088334 SWA_KD_Fehler "Bei gesetztem Bit ist mindestens ein Kundendienstfehler eingetragen";
CM_ SG_ 2549088334 SWA_KompSchutz "Funktionseinschränkung aufgrund Komponentenschutz aktiv";
CM_ SG_ 2549088334 SWA_Lokalaktiv "Zeigt an ob das SG nach Klemme15 AUS und nach entsprechender MAX Aktivzeit noch aktiv war";
CM_ SG_ 2549088334 SWA_Nachlauftyp "Abgebildet wird die von der Hardware vorgegebene Möglichkeit, die Kommunikation nach Klemme 15 = AUS aufrecht zu erhalten. Es wird ein Init-Wert gesendet.
0 = Kommunikation nur bei KL15=EIN (kein Nachlauf, nicht weckfähig)
1 = Kommunikation nach KL15=AU";
CM_ SG_ 2549088334 SWA_SNI "Das Signal beinhaltet den Source Node Identifier (Knotenadresse, die auch in der Abbildungsvorschrift zur CAN-ID für die NM-High Botschaft verwendet wird).";
CM_ SG_ 2549088334 SWA_Subsystemaktiv "Zeigt an ob ein Subsystem des SGs nach Klemme15 AUS und nach entsprechender MAX Aktivzeit noch aktiv war";
CM_ SG_ 2549088334 SWA_Transport_Mode "Funktionseinschränkung aufgrund aktivem Transport Mode und/oder Transport Schutz";

CM_ SG_ 2549088394 KN_SWA_Slave_BusKnockOutTimer "Ausgabe des BusKnockOut-Timer in der Knotenbotschaft";
CM_ SG_ 2549088394 NM_SWA_2_Wakeup "enthält die Weckursache; stehen mehrere Weckursachen parallel an, dann muss der kleinste Wert übertragen werden";
CM_ SG_ 2549088394 SWA_2_Abschaltstufe "Funktionseinschränkung aufgrund aktiver Abschaltstufe";
CM_ SG_ 2549088394 SWA_2_KD_Fehler "Bei gesetztem Bit ist mindestens ein Kundendienstfehler eingetragen";
CM_ SG_ 2549088394 SWA_2_KompSchutz "Funktionseinschränkung aufgrund Komponentenschutz aktiv";
CM_ SG_ 2549088394 SWA_2_Lokalaktiv "Zeigt an ob das SG nach Klemme15 AUS und nach entsprechender MAX Aktivzeit noch aktiv war";
CM_ SG_ 2549088394 SWA_2_Nachlauftyp "Abgebildet wird die von der Hardware vorgegebene Möglichkeit, die Kommunikation nach Klemme 15 = AUS aufrecht zu erhalten. Es wird ein Init-Wert gesendet.
0 = Kommunikation nur bei KL15=EIN (kein Nachlauf, nicht weckfähig)
1 = Kommunikation nach KL15=AU";
CM_ SG_ 2549088394 SWA_2_SNI "Das Signal beinhaltet den Source Node Identifier (Knotenadresse, die auch in der Abbildungsvorschrift zur CAN-ID für die NM-High Botschaft verwendet wird).";
CM_ SG_ 2549088394 SWA_2_Subsystemaktiv "Zeigt an ob ein Subsystem des SGs nach Klemme15 AUS und nach entsprechender MAX Aktivzeit noch aktiv war";
CM_ SG_ 2549088394 SWA_2_Transport_Mode "Funktionseinschränkung aufgrund aktivem Transport Mode und/oder Transport Schutz";

CM_ SG_ 779 KBI_ABS_Lampe "ABS-Sicherheits-Lampe wurde eingeschaltet.";
CM_ SG_ 779 KBI_Airbag_Lampe "Airbag Sicherheits-Lampe wurde eingeschaltet ";
CM_ SG_ 779 KBI_angez_Geschw "Im Tacho angezeigte Geschwindigkeit inklusive der Voreilung

";
CM_ SG_ 779 KBI_Anzeigefehler_NV "Über dieses Signal teilt das Kombiinstrument dem Nightvision-Steuergerät mit, dass ein Fehler vom Kombiinstrument diagnostiziert wurde, der zur Abschaltung der Nightvision-Funktion führen muss.";
CM_ SG_ 779 KBI_Anzeigefehler_SWA "Signal bezieht sich nur auf die SWA-Lampe, Vorhalt für Kombis mit SWA-Lampe. ";
CM_ SG_ 779 KBI_Anzeigestatus_ACC "Status der ACC-Anzeige im nicht permanenten Displaybereich";
CM_ SG_ 779 KBI_Anzeigestatus_GRA "Anzeigestatus der GRA High Wunschgeschwindigkeitsanzeige im Kombiinstrument.
Bei VW bedeutet 'nicht vorhanden' GRA-low fähig (LED immer verbaut).
0 = nicht vorhanden
1 = Wunschgeschwindigkeits-Anzeigemöglichkeit vorhanden
2 = reserviert
3 = Fehler (B";
CM_ SG_ 779 KBI_Anzeigestatus_LIM "Anzeigestatus der Speedlimiter Wunschgeschwindigkeitsanzeige im Kombiinstrument (permanenter Anzeigebereich)
0 = nicht vorhanden
1 = Wunschgeschwindigkeits-Anzeigemöglichkeit vorhanden
2 = reserviert
3 = Fehler (Botschaftsüberwachung, Timeout, Akustik";
CM_ SG_ 779 KBI_ARA_in_Anzeige "Anzeige von ARA im Kombi aktiv";
CM_ SG_ 779 KBI_BKL_Lampe "Sicherheits-Lampe Bremskontrolle wurde eingeschaltet;
";
CM_ SG_ 779 KBI_Einheit_Tacho "Information, ob es sich um Meilen- oder Kmh-Kombi handelt, Einheit des Tachos entspricht dem Zifferblatt, Grösse ist nicht veränderlich";
CM_ SG_ 779 KBI_ESP_Lampe "ESP-Sicherheits-Lampe wurde eingeschaltet ";
CM_ SG_ 779 KBI_Fehler_Anzeige_ACC "Rückmeldung an ACC, dass mindestens eine der ACC-relevanten Anzeigen -rote Fahrerübernahme, Mitteldisplay, Gong - fehlerhaft sind.";
CM_ SG_ 779 KBI_Handbremse "Handbremsen-Information vom Kombi.
Das Signal bezieht sich ausschließlich auf den Zustand der konventionellen Handbremse.";
CM_ SG_ 779 KBI_im_Stellgliedtest "Kombi im Stellgliedtest, Signal muss eingelesen werden, um Fehlfunktion aufgrund der Bewegung der Stellglieder (Drehzahlmesser, Tacho) des Kombis zu verhindern";
CM_ SG_ 779 KBI_Konsistenz_ACC "Rückmeldung an ACC, dass die Botschaften zur Ansteuerung von Anzeigen nicht bzw. nicht konsistent empfangen wurden (Timeout-, BZ-, CHK- und DLC-Fehler)                                                                                                        ";
CM_ SG_ 779 KBI_Lenkung_Lampe "Sicherheits-Lampe der Lenkung (Lenkhilfe EPS, Audi-Dynamic-Steering ...) wurde eingeschaltet.

0x0 = Lenkungs-Lampe aus
0x1 = Lenkungs-Lampe ein";
CM_ SG_ 779 KBI_MFA_v_Einheit_01 "Einheit der Geschwindigkeit, die vom Fahrer im Car-Menü gewählt wurde. Veränderliche Grösse, im Gegensatz zur Einheit des Tachokranzes.";
CM_ SG_ 779 KBI_NV_in_Anzeige "Das Bit gibt dem NV die Information, ob NV-Bild im Kombi in der Anzeige ist. (Information ist notwendig um Kontrasverstellungen nur dann zuzulassen, wenn der Fahrer das Feedback über das  Kombidisplay bekommt.)";
CM_ SG_ 779 KBI_PLA_in_Anzeige "Das Signal wird als aktive Rückmeldung genutzt, ob die Info des PLA im Kombi angezeigt wird. Wenn nach Anforderung des Displays das Signal zweimal auf 0 ist, wird der Parkvorgang abgebrochen.
Ein Kombi, dass PLA Anzeige nicht unterstützt, schickt dauerha";
CM_ SG_ 779 KBI_SILA_gueltig "Rückmeldeinformation (Bit 1-6) ist gültig";
CM_ SG_ 779 KBI_Systemstatus "Signalisiert erkannte FuSi-relevante Fehler im Kombi
(keinen Ausfall der Akustik oder des Displays)";
CM_ SG_ 779 KBI_Tankwarnung "Fahrer wird gewarnt, dass er den Reservebereich erreicht hat. Fzg.spezifische Warnschwelle";
CM_ SG_ 779 KBI_Tankwarnung_ungueltig "Validiert den Inhalt des Signales KBI_Tankwarnung";
CM_ SG_ 779 KBI_Taster_Fahrwerk "Betätigung Taster 'Fahrwerk' im Kombi";
CM_ SG_ 779 KBI_Taster_Lift "Betätigung Taster 'Lift' im Kombi J1 zur Verarbeitung im Porsche EFP Steuergerät";
CM_ SG_ 779 KBI_V_Digital "Ausgabe der im Kombi angezeigten digitalen Geschwindigkeit.

Einheit ist im KBI_MFA_v_Einheit_01 definiert";
CM_ SG_ 779 KBI_Vorglueh_System_Lampe "Rückmeldung der Vorglühlampe bzw. Motor Systemlampe (MO_Systemlampe) an den Motor (bei Diesel und Otto!). Hardwaremässig gleiche LED im Kombi (EPC- oder Glühwendel), Unterscheidung nur über Ziffernblatt.";

CM_ SG_ 1719 KBI_aktive_Laengsfunktion "Auswahl, der vom Fahrer gewünschten Laengsregelfunktion";
CM_ SG_ 1719 KBI_FoD_PopUP_Quittiert "Angezeigte FoD-Warnung im Kombi wurde vom Fahrer quittiert; 
Signal wird für die Dauer von 2 Sekunden gesendet";
CM_ SG_ 1719 KBI_FStatus_Tank "Signal wird gesetzt:

a) Während der Fehlerentprellzeit (20 s Entprellung)

b) Bei erkanntem Fehler wird der Tankinhalt während der laufenden KL15-Phase über den 
    Verbrauch zurückgerechnet. In dieser Zeit ist das Bit ebenfalls gesetzt. Nach einem";
CM_ SG_ 1719 KBI_GRA_im_ACC "Gibt den vom Fahrer ausgewählten Modus (ACC oder GRA_im_ACC) an.";
CM_ SG_ 1719 KBI_Inhalt_Tank "Restmenge 2 bzw. 2,5l nicht auflösbar

";
CM_ SG_ 1719 KBI_Kilometerstand "Fehler wird ausgegeben, falls Kilometerstand nicht restaurierbar
";
CM_ SG_ 1719 KBI_LVDS_Lock "Dient zur Synchronisation der Anzeige zwischen Kombi und ZR";
CM_ SG_ 1719 KBI_Oelwechsel_durchgefuehrt "Nach einen Ölwechsel (Service) ist die Ethanol Warmfahrwarnung zu unterdrücken.";
CM_ SG_ 1719 KBI_QBit_Aussen_Temp_gef "0x0 = gültiger Wert
0x1 = Ersatz-, Init- oder Fehlerwert";
CM_ SG_ 1719 KBI_RDK_Kalibrier_Anf "Bei gesetztem Bit soll die RDK die aktuellen Istdrücke zu Solldrücken übernehmen (nur bei Nichtverbau einer Headunit erforderlich).";
CM_ SG_ 1719 KBI_Reserve_Warnung_Sek "Signalisiert die Reservewarnung für die Energiespeicher CNG, LPG, HV-Batterie.
Fahrer wird gewarnt, dass er den Reservebereich erreicht hat. Fzg.spezifische Warnschwelle.";
CM_ SG_ 1719 KBI_Standzeit_02 "Zähler welcher die Standzeit des Motors wiedergibt.
Das Signal beschreibt den Anteil der Motor-Standzeit zwischen Zündung aus und nächstem Motorstart.";

CM_ SG_ 1614 KBI_HUD_Data_01 "Kommunikation Kombi zu HUD. Prio.texte zur gleichzeitigen Anzeige im Kombi und HUD.";
CM_ SG_ 1614 KBI_HUD_Data_02 "Kommunikation Kombi zu HUD. Prio.texte zur gleichzeitigen Anzeige im Kombi und HUD.";
CM_ SG_ 1614 KBI_HUD_Data_03 "Kommunikation Kombi zu HUD. Prio.texte zur gleichzeitigen Anzeige im Kombi und HUD.";
CM_ SG_ 1614 KBI_HUD_Data_04 "Kommunikation Kombi zu HUD. Prio.texte zur gleichzeitigen Anzeige im Kombi und HUD.";
CM_ SG_ 1614 KBI_HUD_Data_05 "Kommunikation Kombi zu HUD. Prio.texte zur gleichzeitigen Anzeige im Kombi und HUD.";
CM_ SG_ 1614 KBI_HUD_Data_06 "Kommunikation Kombi zu HUD. Prio.texte zur gleichzeitigen Anzeige im Kombi und HUD.";
CM_ SG_ 1614 KBI_HUD_Data_07 "Kommunikation Kombi zu HUD. Prio.texte zur gleichzeitigen Anzeige im Kombi und HUD.";
CM_ SG_ 1614 KBI_HUD_Data_08 "Kommunikation Kombi zu HUD. Prio.texte zur gleichzeitigen Anzeige im Kombi und HUD.";

CM_ SG_ 2549874983 KS_Nightvision_Req_Data "Komponentenschutz (Funktion 01h). Request mit NA des Slaves.";

CM_ SG_ 2550006055 KS_Nightvision_Resp_Data "Komponentenschutz (Funktion 01h). Response mit eigener NA.";

CM_ SG_ 2549875082 KS_SWA_2_Req_Data "Komponentenschutz (Funktion 01h). Request mit NA des Slaves.";

CM_ SG_ 2550006154 KS_SWA_2_Resp_Data "Komponentenschutz (Funktion 01h). Response mit eigener NA.";

CM_ SG_ 2549875022 KS_SWA_Req_Data "Komponentenschutz (Funktion 01h). Request mit NA des Slaves.";

CM_ SG_ 2550006094 KS_SWA_Resp_Data "Komponentenschutz (Funktion 01h). Response mit eigener NA.";

CM_ SG_ 160 EPS_04_BZ "Botschaftszähler";
CM_ SG_ 160 EPS_04_CRC "Für MLB:
'Berechnung siehe Lastenheft 'Kommunikationsabsicherung für FlexRay und CAN''

Ab MQB und MLBevo:
'Berechnung siehe Lastenheft 'End-to-End Kommunikationsabsicherung''

Endwerte siehe Begleitdokument 'S-PDU Kennungsfolgen'";
CM_ SG_ 160 EPS_AWA_Status "beschreibt den Status der AWA-Funktion im EPS-Steuergerät. (Ausweich-Assistent)";
CM_ SG_ 160 EPS_FAS_Regelgroesse "Aktuelle Regelauslastung der STA/STP-Funktionsschnittstelle";
CM_ SG_ 160 EPS_FAS_VZ_Regelgroesse "Richtung der FAS Regelgröße";
CM_ SG_ 160 EPS_Lenkmoment_AbsReduz "Gibt den Absolutwert des aktuelle Handlenkmoment mit einer Auflösung von 0 ,62 Nm aus";
CM_ SG_ 160 EPS_Motormoment "Motornahes Motor-Sollmoment";
CM_ SG_ 160 EPS_QBit_Zahnstangen_Pos "beschreibt die Qualität/Vertrauenswürdigkeit der Zahnstangenposition";
CM_ SG_ 160 EPS_STA_Status "beschreibt den Status der STA-Funktion im EPS-Steuergerät. (Stauassistent)";
CM_ SG_ 160 EPS_Versorgungsspannung "Gibt die am Steuergerät anliegende Spannung aus.
";
CM_ SG_ 160 EPS_Versorgungsstatus "Erkennung Störung im Versorgungspfad
";
CM_ SG_ 160 EPS_VZ_Zahnstangenposition "Vorzeichen der Position/Verschiebung der Zahnstange bzgl. Lenkungsmitte
Vorzeichen:
(Fahreransicht: positiv = links von der Nullstellung des Lenkrades)
Nullstellung = +0mm";
CM_ SG_ 160 EPS_Zahnstangen_Pos "Position/Verschiebung der Zahnstange bzgl. Lenkungsmitte";

CM_ SG_ 981 BCM1_Abblendlicht_Anf "Anforderung Abblendlicht
";
CM_ SG_ 981 BCM1_Adaptive_Lichtvert_Anf "Funktion 'Adaptive Lichtverteilung' im AFS-SG  Ein- und Ausschalten";
CM_ SG_ 981 BCM1_Allwetterlicht_Anf "Anforderung eines Allwetterlichts (über AFS-SG realisiert): Licht für schlechte Sichtverhältnisse";
CM_ SG_ 981 BCM1_Animationssperrung "Sperrung der Scheinwerfer- und Heckleuchten-Animationen. Grund für Sperrung sind allgemeine Rahmenbedingungen, wie beispielseweise eine LDS-Stellung ungleich 'Auto'";
CM_ SG_ 981 BCM1_Autobahnlicht_Anf "Anforderung Autobahnlicht
";
CM_ SG_ 981 BCM1_CH_aktiv "Coming Home (zusätzlich zum Signal 'BCM1_CH_LH_aktiv' in der Botschaft BCM1_01)";
CM_ SG_ 981 BCM1_CH_LH_aktiv "Status Comming / Leaving Home
";
CM_ SG_ 981 BCM1_Fernlicht_Anf "Anforderung Fernlicht
";
CM_ SG_ 981 BCM1_FOD_Sperrung_Animationen_HL "Sperrung Heckleuchten-Animationen durch FoD.";
CM_ SG_ 981 BCM1_FoD_Sperrung_WiBli "Sperrung Wischeffekt des dynamischen Blinkers (Front & Heck) durch FoD";
CM_ SG_ 981 BCM1_Gleitende_Leuchtw_Anf "Funktion 'Gleitende Leuchtweite' im AFS-SG  freischalten";
CM_ SG_ 981 BCM1_GLW_Fernlicht_Anf "Harte Fernlichtanforderung von BCM1 an die Funktion 'gleitende Leuchtweite' im AFS-SG";
CM_ SG_ 981 BCM1_Kurvenlicht_links_Anf "Ansteuerung linkes Kurvenlicht/Abbiegelicht duch BCM1";
CM_ SG_ 981 BCM1_Kurvenlicht_rechts_Anf "Ansteuerung rechtes Kurvenlicht/Abbiegelicht duch BCM1";
CM_ SG_ 981 BCM1_LH_aktiv "Leaving Home (zusätzlich zum Signal 'BCM1_CH_LH_aktiv' in der Botschaft BCM1_01)";
CM_ SG_ 981 BCM1_Nebellicht_Anf "Anforderung Nebellicht
";
CM_ SG_ 981 BCM1_Nebelschluss_Ahg_Anf "Anforderung: Nebelschlusslicht Anhänger (Sollzustand)
";
CM_ SG_ 981 BCM1_Nebelschluss_Fzg_Anf "Anforderung: Nebelschlusslicht Fahrzeug (Sollzustand)
";
CM_ SG_ 981 BCM1_Parklicht_li_Anf "Anforderung: Parklicht links (Sollzustand)
";
CM_ SG_ 981 BCM1_Parklicht_re_Anf "Anforderung: Parklicht rechts (Sollzustand)
";
CM_ SG_ 981 BCM1_Regenlicht_Anf "Anforderung: Regenlicht (Sollzustand)
";
CM_ SG_ 981 BCM1_Schlusslicht_Anf "Anforderung: Schlusslicht Fahrzeug (Sollzustand)
";
CM_ SG_ 981 BCM1_Signaturlicht_Anf "Signal zur Anforderung des Signaturlichts";
CM_ SG_ 981 BCM1_Standlicht_Anf "Anforderung: Schlusslicht (Sollzustand)";
CM_ SG_ 981 BCM1_Tagfahrlicht_Anf "Anforderung: Tagfahrlicht (Sollzustand)";
CM_ SG_ 981 BCM1_Touristen_Licht_Anf "Anforderung: Touristenlicht (Sollzustand)";
CM_ SG_ 981 BCM1_Umfeldleuchten_Anf "Anforderung für Umfeldleuchten";
CM_ SG_ 981 BCM_Rueckfahrlicht_Anf "Anforderung Rückfahrlicht (Sollzustand). 
Das Signal wird entprellt (typisch 400ms) und bei KL15EIN gesendet. Das Signal ist unabhängig von der Position des Heckdeckels (kein Überhitzungsschutz).";
CM_ SG_ 981 Licht_Anf_01_BZ "4bit Botschaftszaehler, wird mit jeder Sendebotschaft inkrementiert";
CM_ SG_ 981 Licht_Anf_01_CRC "Für MLB:
'Berechnung siehe Lastenheft 'Kommunikationsabsicherung für FlexRay und CAN''

Ab MQB und MLBevo:
'Berechnung siehe Lastenheft 'End-to-End Kommunikationsabsicherung''

Endwerte siehe Begleitdokument 'S-PDU Kennungsfolgen'";

CM_ SG_ 1624 BCM1_Licht_Dunkelheit_aktiv "Licht aktiv aufgrund von Dunkelheit (nicht bei Autobahn-, Tagfahr- oder Regenlicht)";
CM_ SG_ 1624 BCM1_Linksverkehr "Information über Aufbauzustand des Fzg:
0 = Scheinwerfer für Rechtsverkehr
1 = Scheinwerfer für Linksverkehr";
CM_ SG_ 1624 Licht_Vorne_01_CRC "Für MLB:
'Berechnung siehe Lastenheft 'Kommunikationsabsicherung für FlexRay und CAN''

Ab MQB und MLBevo:
'Berechnung siehe Lastenheft 'End-to-End Kommunikationsabsicherung''

Endwerte siehe Begleitdokument 'S-PDU Kennungsfolgen'";
CM_ SG_ 1624 LV_Abbiegelicht_li_def "Fehlerstatus Abbiegelicht vorne links
";
CM_ SG_ 1624 LV_Abbiegelicht_re_def "Fehlerstatus Abbiegelicht vorne rechts
";
CM_ SG_ 1624 LV_Abblend_Fernlicht_li_def "Fehlerstatus Abblendlicht und Fernlicht links ";
CM_ SG_ 1624 LV_Abblend_Fernlicht_re_def "Fehlerstatus Abblendlicht und Fernlicht rechts";
CM_ SG_ 1624 LV_Abblendlicht_Anzeige "Abblendlicht aktiv";
CM_ SG_ 1624 LV_Abblendlicht_li_def "Fehlerstatus Abblendlicht vorne links 
";
CM_ SG_ 1624 LV_Abblendlicht_re_def "Fehlerstatus Abblendlicht vorne rechts
";
CM_ SG_ 1624 LV_Abblendlicht_TFL_li_def "Fehlerstatus Abblendlicht und Tagfahrlicht links
";
CM_ SG_ 1624 LV_Abblendlicht_TFL_re_def "Fehlerstatus Abblendlicht und Tagfahrlicht rechts ";
CM_ SG_ 1624 LV_AFL_aktiv_Anzeige "Anzeige AFL-Funktion";
CM_ SG_ 1624 LV_AFL_defekt "Fehlerstatus AFL
";
CM_ SG_ 1624 LV_Aussenlicht_def "Aussenlicht kann nicht mehr korrekt angesteuert werden (EEPROM Codierung kann nicht mehr ausgelesen werden)
";
CM_ SG_ 1624 LV_Blinker_li_def "Fehlerstatus Blinker vorne links
";
CM_ SG_ 1624 LV_Blinker_re_def "Fehlerstatus Blinker vorne rechts
";
CM_ SG_ 1624 LV_Blinker_VL_aktiv "Blinker vorne links
";
CM_ SG_ 1624 LV_Blinker_VR_aktiv "Blinker vorne links
";
CM_ SG_ 1624 LV_Blk_li_Seite_def "Fehlerstatus Seitenblinker links
";
CM_ SG_ 1624 LV_Blk_re_Seite_def "Fehlerstatus Blinker Seite rechts
";
CM_ SG_ 1624 LV_Fernlicht_Anzeige "Fernlicht_aktiv";
CM_ SG_ 1624 LV_Fernlicht_li_def "Fehlerstatus Fernlicht vorne links
";
CM_ SG_ 1624 LV_Fernlicht_re_def "Fehlerstatus Fernlicht vorne rechts
";
CM_ SG_ 1624 LV_FLA_aktiv_Anzeige "Ansteuerung FLA-Lampe im Kombi (BCM1 Bedienmaster)";
CM_ SG_ 1624 LV_FLA_defekt "Fehlerstatus FLA (Anzeige des entsprechenden Fehlertext im Kombi)";
CM_ SG_ 1624 LV_FLA_Sensor_blockiert "Status FLA-Sensor (Anzeige des entsprechenden Fehlertext im Kombi)";
CM_ SG_ 1624 LV_LED_Scheinwerfer_li_def "Fehlerstatus LED-Scheinwerfer links
";
CM_ SG_ 1624 LV_LED_Scheinwerfer_re_def "Fehlerstatus LED-Scheinwerfer rechts";
CM_ SG_ 1624 LV_MXB_Status_Anzeige "Aktueller Status des Fernlichts / MxB zur Signalisierung im Kombi.";
CM_ SG_ 1624 LV_Nebellicht_Anzeige "Nebellicht_aktiv
";
CM_ SG_ 1624 LV_Nebellicht_li_def "Fehlerstatus Nebelscheinwerfer vorne links
";
CM_ SG_ 1624 LV_Nebellicht_re_def "Fehlerstatus Nebelscheinwerfer vorne rechts
";
CM_ SG_ 1624 LV_Nebellicht_TFL_li_def "Fehlerstatus Nebellicht und Tagfahrlicht links ";
CM_ SG_ 1624 LV_Nebellicht_TFL_re_def "Fehlerstatus Nebellicht und Tagfahrlicht rechts";
CM_ SG_ 1624 LV_Nebelschlusslicht_Anzeige "Nebelschlusslicht_aktiv
";
CM_ SG_ 1624 LV_Standlicht_Anzeige "Anzeige Standlicht
";
CM_ SG_ 1624 LV_Standlicht_li_def "Fehlerstatus Standlicht vorne links
";
CM_ SG_ 1624 LV_Standlicht_re_def "Fehlerstatus Standlicht vorne rechts
";
CM_ SG_ 1624 LV_Standlicht_TFL_li_def "Fehlerstatus Standlicht und Tagfahrlicht links ";
CM_ SG_ 1624 LV_Standlicht_TFL_re_def "Fehlerstatus Standlicht und Tagfahrlicht rechts ";
CM_ SG_ 1624 LV_Tagfahrlicht_Anzeige "Anzeige Tagfahrlicht
";
CM_ SG_ 1624 LV_Tagfahrlicht_li_def "Fehlerstatus Tagfahrlicht links
";
CM_ SG_ 1624 LV_Tagfahrlicht_re_def "Fehlerstatus Tagfahrlicht rechts";

CM_ SG_ 917 AFS_Abbiegelicht_Dimm_Anf "Beschreibt ob das Abbiegelicht gedimmt oder hart einschalten werden soll. Dimmkurve ist Empfänger hinterlegt.";
CM_ SG_ 917 AFS_Abbiegelicht_li_Anf "Anforderung das Abbiegelicht links einzuschalten";
CM_ SG_ 917 AFS_Abbiegelicht_re_Anf "Anforderung das Abbiegelicht rechts einzuschalten";
CM_ SG_ 917 AFS_adaptive_LV_verbaut "Verfügbarkeit der adaptiven Lichtverteilung im AFS-SG.
(Das BCM steuert mit diesem Signal die Einblendung des entsprechenden Menüs)";
CM_ SG_ 917 AFS_Allwetterlicht "Status ¿Allwetterlicht¿ - Licht für schlechte Sichtverhältnisse
(bei Defekt -> nicht aktiv)";
CM_ SG_ 917 AFS_Charisma_FahrPr "MLBevo: Aktuelles Fahrprogramm des Charisma-Teilnehmers (siehe Systemlastenheft Drive Select)
MQB: Istwert der Kennlinie (siehe Systemlastenheft MQB FPA)";
CM_ SG_ 917 AFS_Charisma_Status "Charisma Systemstatus des Charisma-Teilnehmers

Wert 0x3 ist nur für Fahrzeuge ab MQB relevant";
CM_ SG_ 917 AFS_Charisma_Umschaltung "Erkennung  Umschaltaufforderung des Charisma-Teilnehmers";
CM_ SG_ 917 AFS_Ersatzlicht_Links "Bei aktivierter Ersatzlichtfunktion wird das Abblendlicht ausgeschaltet und eine Ersatzlichtquelle eingeschaltet (z.Zt. B7)";
CM_ SG_ 917 AFS_Ersatzlicht_Rechts "Bei aktivierter Ersatzlichtfunktion wird das Abblendlicht ausgeschaltet und eine Ersatzlichtquelle eingeschaltet (z.Zt. B7)";
CM_ SG_ 917 AFS_Fehlertext "Fehlertext wird im Kombi angezeigt (z.Zt nur bei VW)";
CM_ SG_ 917 AFS_Fernlicht_li_defekt "Beschreibt ob das Fernlicht des linken Scheinwerfers defekt ist";
CM_ SG_ 917 AFS_Fernlicht_re_defekt "Beschreibt ob das Fernlicht des rechten Scheinwerfers defekt ist";
CM_ SG_ 917 AFS_Fernlicht_Status "Beschreibt ob das Fernlicht aktiv oder inaktiv ist";
CM_ SG_ 917 AFS_Lampe "Status der Fehlerlampe: aktuell anliegender Fehlerzustand des dynamischen oder statischen Kurvenlichtes";
CM_ SG_ 917 AFS_LED_Blinkmode "Lampe soll im Warnfall mit 1Hz blinken, wenn das Bit gesetzt ist (z.Zt nur bei VW)";
CM_ SG_ 917 AFS_Status_adaptive_LV "Gibt den Status der adaptiven Lichtverteilung an";
CM_ SG_ 917 AFS_Verfuegbarkeit_GLW "Beschreibt die Verfügbarkeit der Gleitenden Leuchtweite / Fernlichtassistenz - Verfügbarkeit bedeutet, dass die Funktion Gleitende Leuchtweite möglich ist";
CM_ SG_ 917 GLW_Sensor_blockiert "Das Signal zeigt an, dass die Kamera zur Zeit keine Sicht hat. 
Verhalten wie Fernlichassisten. 
Weiterleitung des Signals vom BCM an das KOMBI";
CM_ SG_ 917 LWR_AFS_Grundeinstellung "Grundeinstellung des Abblendlichtes am Lichteinstellkasten im Service oder Bandende mit Tester erfolgt! (auch für das dynamische Kurvernlicht)";
CM_ SG_ 917 LWR_AFS_Parametrisierung "Parametrisierung wählt die Fahrzeugvariante und die AFS-Variante aus";
CM_ SG_ 917 LWR_Hoehenwert_HL "Aktueller Höhensensorwert Hinten Links
MSS LB überträgt den Aktueller Höhensensorwert Vorne Rechts.

0x7F = 0 mm";
CM_ SG_ 917 LWR_Hoehenwert_VL "Aktueller Höhensensorwert Vorne Links

0x7F = 0 mm";
CM_ SG_ 917 LWR_Initialisierungslauf "Initialisierungslauf der Schrittmotoren, erfolgt defaultmäßig beim Motorstart";
CM_ SG_ 917 LWR_Lampe "Status der Fehlerlampe: aktuell anliegender Fehlerzustand";
CM_ SG_ 917 LWR_Modus "Schnelle oder langsame Regelart der LWR";
CM_ SG_ 917 LWR_Pos_Schrittmotor "Position des Aktuators in Prozent des maximalen Stellweges; vor dem Initialisierungslauf (Motorstart) wird der Initwert ausgegeben: 
0% : tiefste Stellung (auf Block) des Schrittmotors;
100% : maximaler Verstellweg des Schrittmotors (nicht die Grenze de";
CM_ SG_ 917 LWR_Reisemodus_Texte "Anzeige der eingestellten Verkehrsart bei aktivem Touristenlicht";
CM_ SG_ 917 LWR_Sicherheitsposition_li "Rechter Scheinwerfer in Sicherheitsposition.";
CM_ SG_ 917 LWR_Sicherheitsposition_re "Rechter Scheinwerfer in Sicherheitsposition.";
CM_ SG_ 917 LWR_Touristenmodus_aktiv "Über MMI sendet BCM1 eine Anforderung Touristenmodus an die LWR. Diese sendet als Rückmeldung an BCM1, dass der Touristenmodus aktiv geschaltet wurde";
CM_ SG_ 917 LWR_Touristenmodus_verbaut "Verfügbarkeit der Touristenfunktion im AFS/LWR-SG.
(Das BCM steuert mit diesem Signal die Einblendung des entsprechenden Menüs)";

CM_ SG_ 1153 DSSS_Warning "DSSS - Driving Safety Support System Meldungen";
CM_ SG_ 1153 MIB_Tongenerator_PH_verfuegbar "Verfügbarkeit des Tongenerators im MIB für die Nutzung durch die Parkhilfe";
CM_ SG_ 1153 MMI_Counter_Bedienevent "Signal wird inkrementiert, wenn Bedienevent stattgefunden hat.";
CM_ SG_ 1153 MMI_Gauges_active "Signal sent from Main Unit to Kombi instrument to give the display status of the additional gauges in the rotating display";
CM_ SG_ 1153 MMI_SDS_aktiv "Signal wird gesetzt, solange die Sprachbedienung aktiv ist.";
CM_ SG_ 1153 MMI_StartStopp_Info "Stopp-Freigabe und Start-Anforderung an den Start-Stopp-Koordinator
Signal gilt nur für MHEV12V im MLBevo, Stoppverbot darf nur bei Ausstattungsvariante mit 3D-Sound verwendet werden.";
CM_ SG_ 1153 MU_SecondDisplay "Dient zur Überwachung der zweiten LVDS Leitung.";
CM_ SG_ 1153 MU_Update_Time "Ermöglicht auslesen der Historiendaten, wann ein Update lief";
CM_ SG_ 1153 Nav_FoD_Status "FoD Status der Navigation";
CM_ SG_ 1153 ZR_Kindersicherung_RSE "Sperren der Rearseat Unit (Komplette Weckfähigkeit)";
CM_ SG_ 1153 ZR_LAPP_Sondermodus_Status "Statusrückmeldung zum ZR Sondermodus (BT Abschaltung)";
CM_ SG_ 1153 ZR_LoGeWa_Event_Kombiwarnung "Event für Kombiwarnung";
CM_ SG_ 1153 ZR_MXB_Manoever_Ansage "Übertragung der aktuellen Manöver-Ansage für MatrixBeam. Dient zur Veränderung des Lichtbilds abhängig von Navigationsmanövern.";
CM_ SG_ 1153 ZR_Parken_Sondermodus "Rückkanal zum pilotierten Parken zur Signalisierung Status Sondermodus";
CM_ SG_ 1153 ZR_RSE_aktivieren "Weckfähigkeit der RSE";
CM_ SG_ 1153 ZR_Rundenbewertung "Bewertung einer aktuellen Runde (langsamer, gleich schnell, schneller)";
CM_ SG_ 1153 ZR_Rundenfortschritt "Verhältnis von gefahrener Strecke in einer aktuellen Runde zur Länge einer Referenzrunde in Prozent";
CM_ SG_ 1153 ZR_Sta_Inszenierung "MIB sendet Status über Inszenierungssound (welcome sound) an BCM1
Zweck: Synchronisierung mit weiteren Teilnehmern der Startupinszenierung";

CM_ SG_ 1600 MO_Absperrventil_oeffnen "Signal an Klima-SG das Absperrrventil anzusteuern. Ab D4 auch 0x3 Ventil_schließen.

Im MQB wird hier der Soll-Status des Absperrventils ausgegeben.
Achtung: bei z. B. klemmendem Ventil entspricht das Signal nicht dem tatsächlichen Status!";
CM_ SG_ 1600 MO_aktives_Getriebeheizen "Information für Getriebe, ob ein Ventil für Getriebheizen angesteuert werden muss";
CM_ SG_ 1600 MO_Ansaugluft_Temp "In Fahrzeugen ohne Außentemperatur vom Kombi kann aus der Ansauglufttemperatur auf die Außentemperatur geschlossen werden. Beim SDI ist das mit einer gewissen Genauigkeit gegeben. Genutzt wird es vom ASG.";
CM_ SG_ 1600 MO_Getriebe_kuehlen "Anforderung Getriebekühlventilansteuerung";
CM_ SG_ 1600 MO_Heizungspumpenansteuerung "Anforderung Heizungspumpenansteuerung
MQB und Hybrid: Status der Heizungsunterstützungspumpe am MSG
";
CM_ SG_ 1600 MO_Hoeheninfo "Korrekturfaktor Höhe (1 entspricht 1013 mbar)";
CM_ SG_ 1600 MO_HYB_Fehler_HV_Netz "Im HV-Bordnetz ist fehlerbedingt kein generatorischer Betrieb möglich. Das 12V-Bordnetz wird über den DC/DC-Wandler allein aus der Traktionsbatterie gespeist. Um diesen Zustand möglichst lange aufrechterhalten zu können, sollten Komfort-Verbraucher abgesc";
CM_ SG_ 1600 MO_Kennfeldk "Die Kennfeldkühlung ist in diesem Fahrzeug verbaut und hat keinen Systemfehler";
CM_ SG_ 1600 MO_KL15_Abschaltempfehlung "Kessy Abschaltempfehlung nach Verlassen des Fahrzeugs";
CM_ SG_ 1600 MO_Kuehlmittel_Temp "Kuehlmitteltemperatur";
CM_ SG_ 1600 MO_Mom_Traegheit_02 "Massenträgheit (J) der Motors bzw. der Antriebsmaschinen in kgm².

Zur Berücksichtigung des E-Motor in Hybrid-Projekten:
in MLB-Projekten wird nur der J-Wert des Verbrennungsmotors und nicht der J-Wert des E-Motors berücksichtigt.
In MQB/MLBevo-Projek";
CM_ SG_ 1600 MO_Nachlaufzeit_Heizungspumpe "Nachlaufzeit für Heizungspumpe für Turboladerschutz";
CM_ SG_ 1600 MO_Oel_Temp "Realer Meßbereich ca. -40..150 Grad";
CM_ SG_ 1600 MO_QBit_Ansaugluft_Temp "
";
CM_ SG_ 1600 MO_QBit_Hoeheninfo "Qualifizierungsbit der Höheninfo. Gesetzt bei Ersatzwert, Init oder Fehler.";
CM_ SG_ 1600 MO_QBit_Kuehlmittel_Temp "
";
CM_ SG_ 1600 MO_SpannungsAnf "Forderung des Motor-SGs zur Spannungsanhebung";
CM_ SG_ 1600 MO_Versionsinfo_02 "Versioninformation vom Motor zur Steuerung bei inkompatiblen KMatrix-Änderung bzw. Einführung von neuen Funktionen, die in den Empfängern verriegelt werden müssen. Zu jedem Ereignis wird ein fixer Zählerstand zugeordnet, um dem Empfänger die funktionale Ä";

CM_ SG_ 167 MO_erste_Ungenauschwelle "Zusätzliche Ungenauigkeit (zur Grundungenauigkeit). Motormomente ungenau >8% (kleinste Ungenauschwelle)
";
CM_ SG_ 167 MO_Mom_Ist_Summe "Einheitenloser Wert! Faktor in MO_Faktor_Momente_02 in Motor_Code_01 beachten!

Ist-Moment als Summe aus Verbrennungsmotor und E-Motor (bei Hybrid-Konzepten) incl. allen Eingriffen und Korrekturen; definiert als Kupplungsmoment an Kurbelwelle nach Abgri";
CM_ SG_ 167 MO_Mom_Schub "Einheitenloser Wert! Faktor in MO_Faktor_Momente_02 in Motor_Code_01 beachten!

Moment das sich einstellt, wenn der Fahrer 0% Fahrpedal gibt; bei konventionellen Projekten = alle Verluste (mechanische Reibung und sonstige Verluste) des Verbrennungsmotor";
CM_ SG_ 167 MO_Mom_Soll_gefiltert "Einheitenloser Wert! Faktor in MO_Faktor_Momente_02 in Motor_Code_01 beachten!

MO_Mom_Soll_Roh nach Fahrverhaltensfilter, begrenzt nach oben mit MO_Mom_Begr_dyn, Einrechnung der plausibilisierten Bremsen-Eingriffe; ohne Getriebe-Schalt-Eingriffe, ohne ";
CM_ SG_ 167 MO_Mom_Soll_Roh "Einheitenloser Wert! Faktor in MO_Faktor_Momente_02 in Motor_Code_01 beachten!

Momentenanforderung aus Fahrpedal bzw. von ACC/GRA bzw. aus dem Leerlaufregler (quasistatischer Anteil) bzw. aus Rekuperationsanforderung; keine Begrenzungen, keine Filterun";
CM_ SG_ 167 MO_Mom_Traegheit_Summe "Einheitenloser Wert! Faktor in MO_Faktor_Momente (CAN V6.x) bzw. MO_Faktor_Momente_02 (CAN V7.x) in Motor_Code_01 beachten!

Moment, das zur Beschleunigung der trägen Massen aufgewendet wird bzw. frei wird; Summen aus Anteilen für Verbrennungsmotor und ";
CM_ SG_ 167 MO_QBit_Motormomente "AUDI D4: Zykluszeit: 10ms (siehe Zykluszeit schnell/Cycletime Fast)

Ungenaue Momentenangaben, weil die Momente aus Ersatzwerten berechnet wurden (z.B. HFM ausgefallen). Qualifizierungsbit für die Motormomente.

Achtung:
Reduktion der Zykluszeit Moto";
CM_ SG_ 167 MO_Status_Normalbetrieb_01 "Das Motorsteuergerät sendet das Informationsbit, wenn die Initialisierungsphase des Steuergerätes abgeschlossen ist. Zusätzlich muss die Klemme 15 eingeschalten sein und eine applizierbare Mindestdrehzahlschwelle (Kennlinie in Abh. von der Kühlwassertempe";
CM_ SG_ 167 Motor_11_BZ "Botschaft asynchron geroutet. Zählerwert kann springen.";
CM_ SG_ 167 Motor_11_CRC "Für MLB:
'Berechnung siehe Lastenheft 'Kommunikationsabsicherung für FlexRay und CAN''

Ab MQB und MLBevo:
'Berechnung siehe Lastenheft 'End-to-End Kommunikationsabsicherung''

Endwerte siehe Begleitdokument 'S-PDU Kennungsfolgen'";

CM_ SG_ 168 MO_Drehzahl_01 "Im Fehlerfall wird die Motordrehzahl über die Nockenwellendrehzahl als Ersatzgrösse ausgegeben

Bei Parallelhybrid: Getriebeeingangsdrehzahl (=E-Maschinen Drehzahl)

Hinweis: 
Ehemaliger Fehlerwert 0xFFFF wird senderseitig nicht unterstützt. 
Diesen";
CM_ SG_ 168 MO_Mom_Begr_dyn "Einheitenloser Wert! Faktor in MO_Faktor_Momente (CAN V6.x) bzw. MO_Faktor_Momente_02 (CAN V7.x/V8.x) in Motor_Code_01 beachten!

Bei aktueller Drehzahl kurzfristig (ca. 100..200 ms) max. mögliches Moment (Summe aus Verbrennungsmotor und E-Motor), wird ";
CM_ SG_ 168 MO_Mom_Begr_stat "Einheitenloser Wert! Faktor in MO_Faktor_Momente (CAN V6.x) bzw. MO_Faktor_Momente_02 (CAN V7.x) in Motor_Code_01 beachten!

Bei aktueller Drehzahl quasistationär (nach ca. 3..5 s) max. mögliches Moment (Summe aus max. Moment des Verbrennungsmotors aus ";
CM_ SG_ 168 MO_Mom_neg_verfuegbar "Einheitenloser Wert! Faktor in MO_Faktor_Momente (CAN V6.x) bzw. MO_Faktor_Momente_02 (CAN V7.x) in Motor_Code_01 beachten!

Bei aktueller Drehzahl im nächsten Task (bei CAN-Übertragung z.B. 10ms) tatsächlich verfügbares negatives Moment (Summe aus Verl";
CM_ SG_ 168 MO_Momentenintegral_02 "100  %  entspricht volle Verfügbarkeit aktuell vorhanden. 0 % entspricht Integral bis Limit gefüllt, erhöhender Eingriff kann aktuell nicht berücksichtigt werden oder aufgrund eines Fehlers nicht verfügbar
";
CM_ SG_ 168 MO_QBit_Drehzahl_01 "AUDI D4: Zykluszeit: 10ms (siehe Zykluszeit schnell/Cycletime Fast)

Achtung:
Reduktion der Zykluszeit Motor_03 auf 10ms geplant.
Projektabhängig soll künftig mit 10ms gesendet werden.
Empfänger die in weiteren Konzern-Projekten eingesetzt werden müs";
CM_ SG_ 168 Motor_12_CRC "Für MLB:
'Berechnung siehe Lastenheft 'Kommunikationsabsicherung für FlexRay und CAN''

Ab MQB und MLBevo:
'Berechnung siehe Lastenheft 'End-to-End Kommunikationsabsicherung'

Endwerte siehe Begleitdokument 'S-PDU Kennungsfolgen'";

CM_ SG_ 958 MO_Aussp_Anlass "Das Signal zeigt an, ob die Wiederholstartsperre aktiv ist. D. h. eine Ansteuerung des Anlassers wird auch bei erfüllten Startvoraussetzungen (HS: Interlock betätigt bzw. AT: P/N eingelegt und Bremse betätigt) nicht erfolgen.";
CM_ SG_ 958 MO_BKV_Unterdruckwarnung "Über die Unterdruckwarnung signalisiert das MSG dem ESP, dass kein ausreichender Unterdruck für den BKV zur Verfügung gestellt werden kann.";
CM_ SG_ 958 MO_BLS "Ungefiltertes Rohsignal des Bremslichtschalters, nur wenn HW-Eingang bestückt und ausgewertet wird. Bei Motoren ohne genutzten HW-Eingang wird kein Ersatzwert (bspw. SW-Signal über CAN) ausgegeben!
Bei AUDI muss das Signal wg. Bremslichtfunktion immer be";
CM_ SG_ 958 MO_BMS_NV_Anf_stuetzen "Garantierte Unterstützung des Zusatzspeichers ist erforderlich. Zusatzspeicher muss an das Versorgungsnezt angebunden werden. ";
CM_ SG_ 958 MO_EKlKomLeiRed "Anforderung an die Klimasteuerung, die Leistungsaufnahme des E-Kompressors bei schlechtem SOC und in bestimmten Fahrsituationen zu begrenzen. (Das bereits bestehende Signal 'Klimakompressor aus' als stets umzusetzende Anforderung bleibt unverändert besteh";
CM_ SG_ 958 MO_Ext_E_Fahrt_aktiv "Funktionsrückmeldung zum erw. E-Fahr-Betrieb über Lampe/LED im E-Mode-Taster";
CM_ SG_ 958 MO_Fahrer_bremst "Redundante Bremsinformation vom Motor.

MLB:
AUDI D4: Zykluszeit: 10ms (siehe Zykluszeit schnell/Cycletime Fast)
Im AUDI B8 wird in diesem Bit der Wert der ESP-CAN-Information 'ESP_Fahrer_bremst' ausgegeben.

Achtung:
Reduktion der Zykluszeit Motor";
CM_ SG_ 958 MO_FMAus_aktiv "Das Signal gibt Rückmeldung ob Freilauf Motor aus aktiv ist. Beleibt auch 0km/h (unterhalb der StartStopp Schwelle) weiterhin aktiv.";
CM_ SG_ 958 MO_FMAus_Startvariante "Startvariante beim Motorstart aus der Freilauf-Motor-AUS Phase";
CM_ SG_ 958 MO_Freig_Anlass "Bit wird gesetzt, wenn der Motor beim Automatikstart gestartet werden darf (Motorstillstand, Emissionsmaßnahmen sind erfüllt).";
CM_ SG_ 958 MO_Freig_Reku "Empfehlung des Motor-SG's zur Spannungsabsenkung/-anhebung für den Rekuperationsbetrieb";
CM_ SG_ 958 MO_Freigabe_Segeln "Freigabebit des Segelbetriebs im Getriebe. Bedingt durch bestimmte Diagnosen und Adaptionen des MSGs, die nur im Schub möglich sind, darf nicht jede Schubphase für einen Segelbetrieb genutzt werden. Eine Freigabe bleibt auch außerhalb einer Schubphase bes";
CM_ SG_ 958 MO_Gangposition "MLB:
Stellung des Wählhebels in der Schaltgasse des Handschaltgetriebes.
MLBevo: 
Ausweitung der Bedienung auch auf Automatikgetriebe;
Routing des Signals GE_Fahrstufe: 
1. Position_R (dez. 6) auf MO_Gangposition: Gang_R (dez. 13) wegen Entfall Signa";
CM_ SG_ 958 MO_Handshake_STH "Es gilt: Signalspec MO_Handshake v1.0

Handshake zwischen MSG und STH. Wenn das MSG die EKP aufgrund einer STH-Anforderung ansteuert und kein Fehlereintrag bzgl. EKP/KPE/NDR vorliegt, wird das Bit gesetzt.";
CM_ SG_ 958 MO_HYB_Fahrbereitschaft "Signal steuert u.a. in der Lenkhilfe zusammen mit weiteren Informationen den Modewechsel in den 'Drivemode'
Grüne Anzeige im Kombiinstrument zur Signalisierung der Bereitschaft des Hybridsystems.";
CM_ SG_ 958 MO_HYB_VM_aktiv "0 = VMotor wird nicht aktiv gehalten (nVM < n_min und keine LL-Regelung aktiv)
1 = VMotor aktiv (ab der ersten Einspritzung; gilt auch für Schubbetrieb, wenn VMotor spätestens durch LLRegelung befeuert würde)
Verwendet zur Bestimmung des Ist-Zustandes";
CM_ SG_ 958 MO_Interlock "Das Motorsteuergerät gibt die Information aus, ab wann der Kupplungsschalter durch das Motorsteuergerät als getreten gesehen wird.
Bei Systemen für Start Stopp muss das Interlocksignal für einen Start durch das MSG generiert werden, sobald der Schalthebe";
CM_ SG_ 958 MO_Kickdown "Es gilt: Signalspec MO_Kickdown v1.0";
CM_ SG_ 958 MO_Kl_50 "Klemme 50: Startausführung durch Ritzelstarter

MLB: nicht von allen Motoren gesendet
MQB/MLBevo: gesendet von allen Motoren";
CM_ SG_ 958 MO_Kl_75 "Klemme X
";
CM_ SG_ 958 MO_Klima_Eingr "Eingriffe des Motor bei der Klima";
CM_ SG_ 958 MO_KomFehler_ESP "Anzeige Kommunikationsfehler bei Empfang vom ESP";
CM_ SG_ 958 MO_Konsistenz_Bremsped "MLB:

AUDI D4: Zykluszeit: 10ms (siehe Zykluszeit schnell/Cycletime Fast)
Siehe 'Funktionsspezifikation Bremslichtinfo B8'

Achtung:
Reduktion der Zykluszeit Motor_03 auf 10ms geplant.
Projektabhängig soll künftig mit 10ms gesendet werden.
Empfäng";
CM_ SG_ 958 MO_Kuppl_schalter "MLB:
Das Motorsteuergerät gibt die Information aus, ab wann der Kupplungsschalter durch das Motorsteuergerät als getreten gesehen wird
0x0: Schalter sagt betätigt (Ausgekuppelt)
0x1: Schalter sagt nicht betätigt (Eingekuppelt)

MQB:
Nur Handschalter";
CM_ SG_ 958 MO_Motor_laeuft "Das Motorsteuergerät gibt die Information aus, ab wann der Motor verbrennungsbedingt autark läuft und durch zuschaltbare Nebenaggregate mechanisch belastbar ist (z.B. durch Generator, Klimakompressor, etc.).

Die 'Motor läuft' Information wird ausgegebe";
CM_ SG_ 958 MO_PTC_Status "Status-Rückmeldung vom MSG zum aktuellen PTC-Status (stufiges PTC, Relais am MSG). Bei Ansteuerung eines stufigen PTC durch ein anderes SG beschreibt das Signal die vom MSG freigegebene PTC-Stufe.";
CM_ SG_ 958 MO_QBit_Fahrer_bremst "MLB:
AUDI D4: Zykluszeit: 10ms (siehe Zykluszeit schnell/Cycletime Fast)

Achtung:
Reduktion der Zykluszeit Motor_03 auf 10ms geplant.
Projektabhängig soll künftig mit 10ms gesendet werden.
Empfänger die in weiteren Konzern-Projekten eingesetzt werd";
CM_ SG_ 958 MO_QBit_Gangposition "Qualitätsbit zum Signal MO_Gangposition";
CM_ SG_ 958 MO_QBit_KL_75 "Q - Bit für das KL 75 Signal zur Vermeidung der fehlerhaften Erkennung von Motorstarts. 
Wird auf 1 gesetzt, solange das Motorsteuergerät KL15 = AUS erkannt hat.";
CM_ SG_ 958 MO_Remotestart_Betrieb "Das MSG ist für den Remotestart-Betrieb bereit. Nach Empfang der Motorstartanforderung für RSt-Betrieb durch BCM wird der Fahrzeugmotor gestartet und solange der Motor läuft, bleibt dieses Bit aktiv. Dieses Signal ist nur zur Verwendung durch das BCM zur ";
CM_ SG_ 958 MO_Remotestart_moeglich "Wenn Bit gesetzt, würde das MSG bei entsprechender Anforderung durch das BCM den Remotestartbetrieb einleiten, d.h. das MSG ist remotestartfähig und es liegen aktuell keine relevanten Fehler oder andere Abbruchgründe vor.";
CM_ SG_ 958 MO_Signalquelle_Gangposition "Signalquelle des Signals MO_Gangposition
0: Signalquelle Gangpositionssensor
1: Signalquelle Modellwert (v/n)";
CM_ SG_ 958 MO_StartStopp_Fahrerwunsch "Fahreraktivität Start/Stop";
CM_ SG_ 958 MO_StartStopp_Motorstopp "Motor-Stopp durch Start/Stopp-Koordinator
HYBRID:
Wenn MO_Hybridfahrzeug = 1 gilt:
Verbrennungsmotor durch Hybrid-Koordinator im MSG ausgeschaltet. 
Die definierten Start/Stopp-Signale beziehen sich nur auf den Verbrennungsmotor!";
CM_ SG_ 958 MO_StartStopp_Status "Aktivitätsstatus Start/Stopp-Koordinator
HYBRID:
Wenn MO_Hybridfahrzeug = 1 gilt:
Signal bezieht sich nur auf den Verbrennungsmotor, nicht auf den Hybridantrieb
";
CM_ SG_ 958 MO_StartStopp_Wiederstart "Motorwiederstart durch Start/Stopp-Koordinator
HYBRID:
Wenn MO_Hybridfahrzeug =1 gilt:
Warnung vor Spannungseinbruch beim Zustart des Verbrennungsmotors. 
-nicht relevant, da derzeit kein Start über 12V-Starter geplant-
Dieses Signal wird nur vom Hyb";
CM_ SG_ 958 MO_StartVorauss_erfuellt "Dient der Fallunterscheidung bei ZAT-Betätigung im Zustand 'KL15 ein' (bei nicht gesetztem Signal folgt KL15 aus, bei gesetztem Signal folgt setzen KL50-Anf.)

0: Signal nicht bedient 
1: Voraussetzungen zur Antriebsstrangaktivierung / Startvoraussetzu";
CM_ SG_ 958 MO_Zylinderabschaltung "Status Zylinderabschaltung Motor";
CM_ SG_ 958 Motor_14_CRC "Ab MQB und MLBevo:
'Berechnung siehe Lastenheft 'End-to-End Kommunikationsabsicherung'

Endwerte siehe Begleitdokument 'S-PDU Kennungsfolgen'";

CM_ SG_ 1648 MO1_Freigabe_Info_WFS "WFS-Freigabeinformation";
CM_ SG_ 1648 MO1_Freigabe_Verfallsinfo_WFS "WFS-Freigabeverfallsinformation";
CM_ SG_ 1648 MO1_Sperr_Info_WFS "WFS-Sperrinformation";
CM_ SG_ 1648 MO_Abstellzeit "Abstelldauer nach letztem KL15 aus

Hinweis: 
Ehemaliger Fehlerwert 0xFF wird senderseitig nicht unterstützt. 
Diesen Wert aus Kompatibilitätsgründen nicht neu belegen!";
CM_ SG_ 1648 MO_Abstellzeit_Status "Statusinformation zur Abstellzeit
0: Die dem Status zugeordnete Variable konnte noch nicht berechnet werden. 
1: Die dem Status zugehörige Variable wurde korrekt berechnet. 
2: Der Wert der zugehörigen Variablen ist nur ein Minimalwert. 
3: Der Wert d";
CM_ SG_ 1648 MO_ANC_Kennfeld_Anf "Anforderung ANC Kennfeldumschaltung";
CM_ SG_ 1648 MO_Anzahl_Abgesch_Zyl "Gibt die Anzahl der abgeschalteten Zylinder an. In Übergangszuständen wird der Zielbetriebszustand angezeigt.";
CM_ SG_ 1648 MO_Bremslicht_Reku "Bremslicht (ggf. bei Rekuperation durch E-Motor) wird angesteuert";
CM_ SG_ 1648 MO_Drehzahl_Warnung "Warnhinweis zum Kombi im Fall einer fehlerbehafteten Drehzahlbegrenzung";
CM_ SG_ 1648 MO_EPCL "Die Anforderung der EPC-Lampe vom MSG ans Kombi soll durch das Bus-Signal MO_EPCL gemäß folgender Logik erfolgen:
MO_EPCL = 0 dez -> EPC Lampe aus, kein Text
MO_EPCL = 1 dez -> gelbe EPC-Symbolik, Text „Antrieb: Störung! Bitte Service aufsuchen“
MO_EPC";
CM_ SG_ 1648 MO_Ethanol_BS_Texte "Ethanol Brennstoff-Texte im Kombi

0 = kein Text
1 = E85 Warm_Up
2 = FlexFuel Warnung 3.Stufe (Too cold for ethanol)
3 = Warmfahrempfehlung MQB / FlexFuel Warnung 1.Stufe (Refuel with gasoline)
4 = FlexFuel Warnung 2. Stufe (Refuel with gasoline)
5";
CM_ SG_ 1648 MO_Fahrzeugtyp "Unterscheidet die Fahrzeugtypen bzgl. der Antriebsart";
CM_ SG_ 1648 MO_Fehler_Zylabsch "Fehlerstatus der Funktion Zylinderabschaltung ";
CM_ SG_ 1648 MO_Hybrid_StartStopp_LED "Ansteuerung der Funktions-LED der Hybrid Taste bzw. Start/Stop Deaktivierungstaste.
Der Start/Stopp-Master (derzeit im MSG) (oder ein künftiger Hybrid-Master) soll die Ansteuerung senden.";
CM_ SG_ 1648 MO_max_Ladedruck "maximal möglicher Ladedruck (zur Anpassung des Anzeigebereichs bei absoluter Ladedruckanzeige)";
CM_ SG_ 1648 MO_NMAX_Schaltanzeige "Maximaldrehzahl für Schaltanzeige";
CM_ SG_ 1648 MO_obere_Drehzahlgrenze "obere Drehzahlgrenze des Motors";
CM_ SG_ 1648 MO_StartStopp_PopUp "Das Signal zeigt an, ob der StSt-Status mittels Deaktivierungstaster geändert wurde. Ein Wechsel auf die Werte 01 oder 10 löst im Kombi ein entsprechendes PopUp aus. Bei einem Statuswechsel durch andere Signalquellen (z.B. Charisma, fehlerbedingte Abschal";
CM_ SG_ 1648 MO_Zylabsch_Texte "Zylinderabschaltung mode in Kombi, fuer Zylinderabschaltung";
CM_ SG_ 1648 MO_Zylabsch_Texte_02 "ZAS-Anzeige für den Fahrer im Kombi
0: kein ZAS (generell keinerlei ZAS-Anzeigen)  (Init für nicht ZAS-Motor)
1: ZAS im Vollmotorbetrieb  (Init für ZAS-Motor)
2: ZAS im Abschaltbetrieb: 1 Zyl aktiv
3: ZAS im Abschaltbetrieb: 2 Zyl aktiv
4: ZAS im Abs";

CM_ SG_ 1010 MO_SCR_Dosierpumpe_Soll "Sollwert zur Pumpensteuerung im eingestellten Zustand
Drehzahlregulierung 100% entspricht 4000 1/min
Druckregelung 100% entspricht 10 bar";
CM_ SG_ 1010 MO_SCR_Dosierpumpe_Wartezeit "Zeit nach der bei KL15_AUS das Rücksaugen der Leitung en beginnen soll. Abhängig von der AGA-Temperatur";
CM_ SG_ 1010 MO_SCR_Dosierpumpe_Zustand "In welchen Zustand die  Dosierpumpe geschaltet wird";
CM_ SG_ 1010 MO_SCR_Heizkreis_3 "Heizkreis 3 einschalten";
CM_ SG_ 1010 MO_SCR_Heizkreis_3_Leistung "Sollwert der Heizleistung Tankheizkreis 2";
CM_ SG_ 1010 MO_SCR_Leitungsheizung "Anforderung Leitungsheizung";
CM_ SG_ 1010 MO_SCR_Tankheizkreis_Leistung "der Tankheizer soll Leistungsgeregelt werden";
CM_ SG_ 1010 MO_SCR_Tankheizung "Anforderung Tankheizung";
CM_ SG_ 1010 MO_SCR_Transferpumpe "Ansteuern der Tansferpumpe zum Umpumpen vom Passivtank zum Aktivtank";
CM_ SG_ 1010 Motor_19_BZ "Zähler der von der Applikation inkrementiert wird";
BA_DEF_REL_ BU_SG_REL_  "GenSigTimeoutTime" INT 0 65535;
BA_DEF_ BO_  "DiagRequest" ENUM "No", "Yes";
BA_DEF_ BO_  "DiagResponse" ENUM "No", "Yes";
BA_DEF_ BO_  "DiagState" ENUM "No", "Yes";
BA_DEF_ BO_  "GenMsgChkConstant" HEX 0 4095;
BA_DEF_ BO_  "GenMsgCycleTime" INT 0 65535;
BA_DEF_ BO_  "GenMsgCycleTimeFast" INT 0 65535;
BA_DEF_ BO_  "GenMsgDelayTime" INT 0 100000;
BA_DEF_ BO_  "GenMsgILSupport" ENUM "No", "Yes";
BA_DEF_ BO_  "GenMsgNrOfRepetition" INT 0 100;
BA_DEF_ BO_  "GenMsgPDUConstants" STRING;
BA_DEF_ BO_  "GenMsgSendType" ENUM "Cyclic", "not_used", "not_used", "not_used", "not_used", "not_used", "not_used", "IfActive", "NoMsgSendType";
BA_DEF_ BO_  "GenMsgStartDelayTime" INT 0 100000;
BA_DEF_ BO_  "NmMessage" ENUM "No", "Yes";
BA_DEF_ BO_  "NmhMessage" ENUM "No", "Yes";
BA_DEF_ BO_  "MsgType" ENUM "Application", "NM ", "NMH", "TP2.0", "ISO-TP ", "BAP", "EID", "KS";
BA_DEF_ BO_  "VAGTP20_API" HEX 0 255;
BA_DEF_ BO_  "VAGTP20_DynConnection" ENUM "No", "Yes";
BA_DEF_ BO_  "VAGTP20_DynSetup" ENUM "No", "Yes";
BA_DEF_ BO_  "VAGTP20_StatConnection" ENUM "No", "Yes";
BA_DEF_ SG_  "GenSigActiveRepetitions" INT -2147483648 2147483647;
BA_DEF_ SG_  "GenSigInactiveValue" INT -2147483648 2147483647;
BA_DEF_ SG_  "GenSigSendType" ENUM "Cyclic", "OnWrite", "OnWriteWithRepetition", "OnChange", "OnChangeWithRepetition", "IfActive", "IfActiveWithRepetition", "NoSigSendType", "OnChangeAndIfActive", "OnChangeAndIfActiveWithRepetition";
BA_DEF_ SG_  "GenSigStartValue" INT -2147483648 2147483647;
BA_DEF_ SG_  "NWM-WakeupAllowed" ENUM "No", "Yes";
BA_DEF_ SG_  "GenSigFuncType" ENUM "NoFunction", "MsgCounter", "CRC-8", "XOR", "XOR-2", "DatedBit", "SW-Kl15", "CHK", "Constant", "Protocol", "CRC-8-SAE_J1850";
BA_DEF_ SG_  "GenSigSwitchedByIgnition" ENUM "No", "Yes";
BA_DEF_ SG_  "Fehlerwert" HEX 0 2147483647;
BA_DEF_ SG_  "GenSigMissingSourceValue" HEX 0 2147483647;
BA_DEF_DEF_REL_  "GenSigTimeoutTime" 0;
BA_DEF_DEF_  "DiagRequest" "No";
BA_DEF_DEF_  "DiagResponse" "No";
BA_DEF_DEF_  "DiagState" "No";
BA_DEF_DEF_  "GenMsgChkConstant" 0;
BA_DEF_DEF_  "GenMsgCycleTime" 0;
BA_DEF_DEF_  "GenMsgCycleTimeFast" 0;
BA_DEF_DEF_  "GenMsgDelayTime" 0;
BA_DEF_DEF_  "GenMsgILSupport" "No";
BA_DEF_DEF_  "GenMsgNrOfRepetition" 0;
BA_DEF_DEF_  "GenMsgPDUConstants" "";
BA_DEF_DEF_  "GenMsgSendType" "NoMsgSendType";
BA_DEF_DEF_  "GenMsgStartDelayTime" 0;
BA_DEF_DEF_  "NmMessage" "No";
BA_DEF_DEF_  "NmhMessage" "No";
BA_DEF_DEF_  "MsgType" "Application";
BA_DEF_DEF_  "VAGTP20_API" 0;
BA_DEF_DEF_  "VAGTP20_DynConnection" "No";
BA_DEF_DEF_  "VAGTP20_DynSetup" "No";
BA_DEF_DEF_  "VAGTP20_StatConnection" "No";
BA_DEF_DEF_  "GenSigActiveRepetitions" 0;
BA_DEF_DEF_  "GenSigInactiveValue" 0;
BA_DEF_DEF_  "GenSigSendType" "NoSigSendType";
BA_DEF_DEF_  "GenSigStartValue" 0;
BA_DEF_DEF_  "NWM-WakeupAllowed" "No";
BA_DEF_DEF_  "GenSigFuncType" "NoFunction";
BA_DEF_DEF_  "GenSigSwitchedByIgnition" "Yes";
BA_DEF_DEF_  "Fehlerwert" 0;
BA_DEF_DEF_  "GenSigMissingSourceValue" 0;
BA_ "GenMsgCycleTime" BO_ 2549088295 500;
BA_ "GenMsgILSupport" BO_ 2549088295 1;
BA_ "GenMsgSendType" BO_ 2549088295 0;
BA_ "GenMsgCycleTime" BO_ 2549088267 500;
BA_ "GenMsgILSupport" BO_ 2549088267 1;
BA_ "GenMsgSendType" BO_ 2549088267 0;
BA_ "GenMsgCycleTime" BO_ 2549088361 500;
BA_ "GenMsgILSupport" BO_ 2549088361 1;
BA_ "GenMsgSendType" BO_ 2549088361 0;
BA_ "GenMsgCycleTime" BO_ 2549088284 500;
BA_ "GenMsgILSupport" BO_ 2549088284 1;
BA_ "GenMsgSendType" BO_ 2549088284 0;
BA_ "GenMsgCycleTime" BO_ 2549088298 500;
BA_ "GenMsgILSupport" BO_ 2549088298 1;
BA_ "GenMsgSendType" BO_ 2549088298 0;
BA_ "GenMsgCycleTime" BO_ 2549088362 500;
BA_ "GenMsgILSupport" BO_ 2549088362 1;
BA_ "GenMsgSendType" BO_ 2549088362 0;
BA_ "GenMsgCycleTime" BO_ 2549088334 500;
BA_ "GenMsgILSupport" BO_ 2549088334 1;
BA_ "GenMsgSendType" BO_ 2549088334 0;
BA_ "GenMsgCycleTime" BO_ 2549088394 500;
BA_ "GenMsgILSupport" BO_ 2549088394 1;
BA_ "GenMsgSendType" BO_ 2549088394 0;
BA_ "GenMsgCycleTime" BO_ 779 50;
BA_ "GenMsgILSupport" BO_ 779 1;
BA_ "GenMsgSendType" BO_ 779 0;
BA_ "GenMsgCycleTime" BO_ 1719 1000;
BA_ "GenMsgDelayTime" BO_ 1719 100;
BA_ "GenMsgILSupport" BO_ 1719 1;
BA_ "GenMsgSendType" BO_ 1719 0;
BA_ "GenMsgCycleTime" BO_ 1614 1000;
BA_ "GenMsgDelayTime" BO_ 1614 20;
BA_ "GenMsgILSupport" BO_ 1614 1;
BA_ "GenMsgSendType" BO_ 1614 0;
BA_ "MsgType" BO_ 2549874983 4;
BA_ "MsgType" BO_ 2550006055 4;
BA_ "MsgType" BO_ 2549875082 4;
BA_ "MsgType" BO_ 2550006154 4;
BA_ "MsgType" BO_ 2549875022 4;
BA_ "MsgType" BO_ 2550006094 4;
BA_ "GenMsgCycleTime" BO_ 160 10;
BA_ "GenMsgILSupport" BO_ 160 1;
BA_ "GenMsgPDUConstants" BO_ 160 "0x4a,0xb4,0xe8,0x24,0x99,0x5a,0x59,0x8b,0x1e,0xaa,0x94,0xb6,0x09,0xd5,0xaf,0x97";
BA_ "GenMsgSendType" BO_ 160 0;
BA_ "GenMsgCycleTime" BO_ 981 100;
BA_ "GenMsgDelayTime" BO_ 981 50;
BA_ "GenMsgILSupport" BO_ 981 1;
BA_ "GenMsgPDUConstants" BO_ 981 "0xc5,0x39,0xc7,0xf9,0x92,0xd8,0x24,0xce,0xf1,0xb5,0x7a,0xc4,0xbc,0x60,0xe3,0xd1";
BA_ "GenMsgSendType" BO_ 981 0;
BA_ "GenMsgCycleTime" BO_ 1624 1000;
BA_ "GenMsgDelayTime" BO_ 1624 50;
BA_ "GenMsgILSupport" BO_ 1624 1;
BA_ "GenMsgPDUConstants" BO_ 1624 "0x46,0x0f,0xe0,0xcc,0xbe,0xb1,0xd7,0xf1,0x1f,0x31,0xc1,0x25,0xb4,0x3e,0xc8,0xa3";
BA_ "GenMsgSendType" BO_ 1624 0;
BA_ "GenMsgCycleTime" BO_ 917 100;
BA_ "GenMsgDelayTime" BO_ 917 10;
BA_ "GenMsgILSupport" BO_ 917 1;
BA_ "GenMsgSendType" BO_ 917 0;
BA_ "GenMsgCycleTime" BO_ 1153 500;
BA_ "GenMsgCycleTimeFast" BO_ 1153 50;
BA_ "GenMsgDelayTime" BO_ 1153 50;
BA_ "GenMsgILSupport" BO_ 1153 1;
BA_ "GenMsgNrOfRepetition" BO_ 1153 5;
BA_ "GenMsgSendType" BO_ 1153 0;
BA_ "GenMsgCycleTime" BO_ 1600 320;
BA_ "GenMsgILSupport" BO_ 1600 1;
BA_ "GenMsgSendType" BO_ 1600 0;
BA_ "GenMsgCycleTime" BO_ 167 20;
BA_ "GenMsgILSupport" BO_ 167 1;
BA_ "GenMsgPDUConstants" BO_ 167 "0xd2,0x3d,0xcd,0x28,0x4c,0x14,0x22,0x4b,0x24,0xac,0xfa,0x55,0x66,0x80,0x0d,0x6c";
BA_ "GenMsgSendType" BO_ 167 0;
BA_ "GenMsgCycleTime" BO_ 168 10;
BA_ "GenMsgILSupport" BO_ 168 1;
BA_ "GenMsgPDUConstants" BO_ 168 "0x52,0x8c,0x50,0xee,0x4f,0xa6,0xcc,0xcf,0x7d,0x2f,0x98,0x6b,0x27,0x41,0x9f,0x93";
BA_ "GenMsgSendType" BO_ 168 0;
BA_ "GenMsgCycleTime" BO_ 958 100;
BA_ "GenMsgDelayTime" BO_ 958 10;
BA_ "GenMsgILSupport" BO_ 958 1;
BA_ "GenMsgPDUConstants" BO_ 958 "0x1f,0x28,0xc6,0x85,0xe6,0xf8,0xb0,0x19,0x5b,0x64,0x35,0x21,0xe4,0xf7,0x9c,0x24";
BA_ "GenMsgSendType" BO_ 958 0;
BA_ "GenMsgCycleTime" BO_ 1648 500;
BA_ "GenMsgDelayTime" BO_ 1648 20;
BA_ "GenMsgILSupport" BO_ 1648 1;
BA_ "GenMsgSendType" BO_ 1648 0;
BA_ "GenMsgCycleTime" BO_ 1010 80;
BA_ "GenMsgILSupport" BO_ 1010 1;
BA_ "GenMsgSendType" BO_ 1010 0;
BA_ "GenSigSendType" SG_ 2549088295 Nightvision_Abschaltstufe 0;
BA_ "GenSigSendType" SG_ 2549088295 Nightvision_KD_Fehler 0;
BA_ "GenSigSendType" SG_ 2549088295 Nightvision_KompSchutz 0;
BA_ "GenSigSendType" SG_ 2549088295 Nightvision_Lokalaktiv 0;
BA_ "GenSigSendType" SG_ 2549088295 Nightvision_Nachlauftyp 0;
BA_ "GenSigSendType" SG_ 2549088295 Nightvision_SNI 0;
BA_ "GenSigStartValue" SG_ 2549088295 Nightvision_SNI 39;
BA_ "GenSigSendType" SG_ 2549088295 Nightvision_Subsystemaktiv 0;
BA_ "GenSigSendType" SG_ 2549088295 Nightvision_Transport_Mode 0;
BA_ "GenSigSendType" SG_ 2549088295 NM_Nightvision_Wakeup 0;
BA_ "NWM-WakeupAllowed" SG_ 2549088295 NM_Nightvision_Wakeup 1;
BA_ "GenSigSendType" SG_ 2549088267 KN_RDK_BusKnockOutTimer 0;
BA_ "GenSigSwitchedByIgnition" SG_ 2549088267 KN_RDK_BusKnockOutTimer 0;
BA_ "GenSigSendType" SG_ 2549088267 NM_RDK_Lokalaktiv 0;
BA_ "GenSigSwitchedByIgnition" SG_ 2549088267 NM_RDK_Lokalaktiv 0;
BA_ "GenSigSendType" SG_ 2549088267 NM_RDK_Subsystemaktiv 0;
BA_ "GenSigSwitchedByIgnition" SG_ 2549088267 NM_RDK_Subsystemaktiv 0;
BA_ "GenSigSendType" SG_ 2549088267 NM_RDK_Wakeup 0;
BA_ "NWM-WakeupAllowed" SG_ 2549088267 NM_RDK_Wakeup 1;
BA_ "GenSigSwitchedByIgnition" SG_ 2549088267 NM_RDK_Wakeup 0;
BA_ "GenSigSendType" SG_ 2549088267 RDK_Abschaltstufe 0;
BA_ "GenSigSwitchedByIgnition" SG_ 2549088267 RDK_Abschaltstufe 0;
BA_ "GenSigSendType" SG_ 2549088267 RDK_KD_Fehler 0;
BA_ "GenSigSwitchedByIgnition" SG_ 2549088267 RDK_KD_Fehler 0;
BA_ "GenSigSendType" SG_ 2549088267 RDK_KompSchutz 0;
BA_ "GenSigSwitchedByIgnition" SG_ 2549088267 RDK_KompSchutz 0;
BA_ "GenSigSendType" SG_ 2549088267 RDK_Nachlauftyp 0;
BA_ "GenSigSwitchedByIgnition" SG_ 2549088267 RDK_Nachlauftyp 0;
BA_ "GenSigSendType" SG_ 2549088267 RDK_SNI 0;
BA_ "GenSigStartValue" SG_ 2549088267 RDK_SNI 11;
BA_ "GenSigSwitchedByIgnition" SG_ 2549088267 RDK_SNI 0;
BA_ "GenSigSendType" SG_ 2549088267 RDK_Transport_Mode 0;
BA_ "GenSigSwitchedByIgnition" SG_ 2549088267 RDK_Transport_Mode 0;
BA_ "GenSigSendType" SG_ 2549088361 KN_Rearview_BusKnockOutTimer 0;
BA_ "GenSigSwitchedByIgnition" SG_ 2549088361 KN_Rearview_BusKnockOutTimer 0;
BA_ "GenSigSendType" SG_ 2549088361 NM_Rearview_Wakeup 0;
BA_ "NWM-WakeupAllowed" SG_ 2549088361 NM_Rearview_Wakeup 1;
BA_ "GenSigSwitchedByIgnition" SG_ 2549088361 NM_Rearview_Wakeup 0;
BA_ "GenSigSendType" SG_ 2549088361 Rearview_Abschaltstufe 0;
BA_ "GenSigSwitchedByIgnition" SG_ 2549088361 Rearview_Abschaltstufe 0;
BA_ "GenSigSendType" SG_ 2549088361 Rearview_KompSchutz 0;
BA_ "GenSigSwitchedByIgnition" SG_ 2549088361 Rearview_KompSchutz 0;
BA_ "GenSigSendType" SG_ 2549088361 Rearview_Lokalaktiv 0;
BA_ "GenSigSwitchedByIgnition" SG_ 2549088361 Rearview_Lokalaktiv 0;
BA_ "GenSigSendType" SG_ 2549088361 Rearview_Nachlauftyp 0;
BA_ "GenSigStartValue" SG_ 2549088361 Rearview_Nachlauftyp 2;
BA_ "GenSigSwitchedByIgnition" SG_ 2549088361 Rearview_Nachlauftyp 0;
BA_ "GenSigSendType" SG_ 2549088361 Rearview_SNI 0;
BA_ "GenSigStartValue" SG_ 2549088361 Rearview_SNI 105;
BA_ "GenSigSwitchedByIgnition" SG_ 2549088361 Rearview_SNI 0;
BA_ "GenSigSendType" SG_ 2549088361 Rearview_Subsystemaktiv 0;
BA_ "GenSigSwitchedByIgnition" SG_ 2549088361 Rearview_Subsystemaktiv 0;
BA_ "GenSigSendType" SG_ 2549088361 Rearview_Transport_Mode 0;
BA_ "GenSigSwitchedByIgnition" SG_ 2549088361 Rearview_Transport_Mode 0;
BA_ "GenSigSendType" SG_ 2549088361 RV_KD_Fehler 0;
BA_ "GenSigSwitchedByIgnition" SG_ 2549088361 RV_KD_Fehler 0;
BA_ "GenSigSendType" SG_ 2549088284 NM_SAK_Wakeup 0;
BA_ "NWM-WakeupAllowed" SG_ 2549088284 NM_SAK_Wakeup 1;
BA_ "GenSigSendType" SG_ 2549088284 SAK_Abschaltstufe 0;
BA_ "GenSigSendType" SG_ 2549088284 SAK_KD_Fehler 0;
BA_ "GenSigSendType" SG_ 2549088284 SAK_KompSchutz 0;
BA_ "GenSigSendType" SG_ 2549088284 SAK_Lokalaktiv 0;
BA_ "GenSigSendType" SG_ 2549088284 SAK_Nachlauftyp 0;
BA_ "GenSigSendType" SG_ 2549088284 SAK_SNI 0;
BA_ "GenSigStartValue" SG_ 2549088284 SAK_SNI 28;
BA_ "GenSigSendType" SG_ 2549088284 SAK_Subsystemaktiv 0;
BA_ "GenSigSendType" SG_ 2549088284 SAK_Transport_Mode 0;
BA_ "GenSigSendType" SG_ 2549088298 KN_SCR_BusKnockOutTimer 0;
BA_ "GenSigSwitchedByIgnition" SG_ 2549088298 KN_SCR_BusKnockOutTimer 0;
BA_ "GenSigSendType" SG_ 2549088298 NM_SCR_Wakeup 0;
BA_ "NWM-WakeupAllowed" SG_ 2549088298 NM_SCR_Wakeup 1;
BA_ "GenSigSwitchedByIgnition" SG_ 2549088298 NM_SCR_Wakeup 0;
BA_ "GenSigSendType" SG_ 2549088298 NMH_SCR_Lokalaktiv 0;
BA_ "GenSigSwitchedByIgnition" SG_ 2549088298 NMH_SCR_Lokalaktiv 0;
BA_ "GenSigSendType" SG_ 2549088298 NMH_SCR_Subsystemaktiv 0;
BA_ "GenSigSwitchedByIgnition" SG_ 2549088298 NMH_SCR_Subsystemaktiv 0;
BA_ "GenSigSendType" SG_ 2549088298 SCR_Abschaltstufe 0;
BA_ "GenSigSwitchedByIgnition" SG_ 2549088298 SCR_Abschaltstufe 0;
BA_ "GenSigSendType" SG_ 2549088298 SCR_KD_Fehler 0;
BA_ "GenSigSwitchedByIgnition" SG_ 2549088298 SCR_KD_Fehler 0;
BA_ "GenSigSendType" SG_ 2549088298 SCR_KompSchutz 0;
BA_ "GenSigSwitchedByIgnition" SG_ 2549088298 SCR_KompSchutz 0;
BA_ "GenSigSendType" SG_ 2549088298 SCR_Nachlauftyp 0;
BA_ "GenSigStartValue" SG_ 2549088298 SCR_Nachlauftyp 2;
BA_ "GenSigSwitchedByIgnition" SG_ 2549088298 SCR_Nachlauftyp 0;
BA_ "GenSigSendType" SG_ 2549088298 SCR_SNI 0;
BA_ "GenSigStartValue" SG_ 2549088298 SCR_SNI 42;
BA_ "GenSigSwitchedByIgnition" SG_ 2549088298 SCR_SNI 0;
BA_ "GenSigSendType" SG_ 2549088298 SCR_Transport_Mode 0;
BA_ "GenSigSwitchedByIgnition" SG_ 2549088298 SCR_Transport_Mode 0;
BA_ "GenSigSendType" SG_ 2549088362 KN_STH_BusKnockOutTimer 0;
BA_ "GenSigSwitchedByIgnition" SG_ 2549088362 KN_STH_BusKnockOutTimer 0;
BA_ "GenSigSendType" SG_ 2549088362 NM_STH_Wakeup 0;
BA_ "NWM-WakeupAllowed" SG_ 2549088362 NM_STH_Wakeup 1;
BA_ "GenSigSwitchedByIgnition" SG_ 2549088362 NM_STH_Wakeup 0;
BA_ "GenSigSendType" SG_ 2549088362 NMH_STH_Lokalaktiv 0;
BA_ "GenSigSwitchedByIgnition" SG_ 2549088362 NMH_STH_Lokalaktiv 0;
BA_ "GenSigSendType" SG_ 2549088362 NMH_STH_Subsystemaktiv 0;
BA_ "GenSigSwitchedByIgnition" SG_ 2549088362 NMH_STH_Subsystemaktiv 0;
BA_ "GenSigSendType" SG_ 2549088362 STH_Abschaltstufe 0;
BA_ "GenSigSwitchedByIgnition" SG_ 2549088362 STH_Abschaltstufe 0;
BA_ "GenSigSendType" SG_ 2549088362 STH_KD_Fehler 0;
BA_ "GenSigSwitchedByIgnition" SG_ 2549088362 STH_KD_Fehler 0;
BA_ "GenSigSendType" SG_ 2549088362 STH_KompSchutz 0;
BA_ "GenSigSwitchedByIgnition" SG_ 2549088362 STH_KompSchutz 0;
BA_ "GenSigSendType" SG_ 2549088362 STH_Nachlauftyp 0;
BA_ "GenSigStartValue" SG_ 2549088362 STH_Nachlauftyp 2;
BA_ "GenSigSwitchedByIgnition" SG_ 2549088362 STH_Nachlauftyp 0;
BA_ "GenSigSendType" SG_ 2549088362 STH_SNI 0;
BA_ "GenSigStartValue" SG_ 2549088362 STH_SNI 106;
BA_ "GenSigSwitchedByIgnition" SG_ 2549088362 STH_SNI 0;
BA_ "GenSigSendType" SG_ 2549088362 STH_Transport_Mode 0;
BA_ "GenSigSwitchedByIgnition" SG_ 2549088362 STH_Transport_Mode 0;
BA_ "GenSigSendType" SG_ 2549088334 KN_SWA_BusKnockOutTimer 0;
BA_ "GenSigSwitchedByIgnition" SG_ 2549088334 KN_SWA_BusKnockOutTimer 0;
BA_ "GenSigSendType" SG_ 2549088334 NM_SWA_Wakeup 0;
BA_ "NWM-WakeupAllowed" SG_ 2549088334 NM_SWA_Wakeup 1;
BA_ "GenSigSwitchedByIgnition" SG_ 2549088334 NM_SWA_Wakeup 0;
BA_ "GenSigSendType" SG_ 2549088334 SWA_Abschaltstufe 0;
BA_ "GenSigSwitchedByIgnition" SG_ 2549088334 SWA_Abschaltstufe 0;
BA_ "GenSigSendType" SG_ 2549088334 SWA_KD_Fehler 0;
BA_ "GenSigSendType" SG_ 2549088334 SWA_KompSchutz 0;
BA_ "GenSigSwitchedByIgnition" SG_ 2549088334 SWA_KompSchutz 0;
BA_ "GenSigSendType" SG_ 2549088334 SWA_Lokalaktiv 0;
BA_ "GenSigSwitchedByIgnition" SG_ 2549088334 SWA_Lokalaktiv 0;
BA_ "GenSigSendType" SG_ 2549088334 SWA_Nachlauftyp 0;
BA_ "GenSigSendType" SG_ 2549088334 SWA_SNI 0;
BA_ "GenSigStartValue" SG_ 2549088334 SWA_SNI 78;
BA_ "GenSigSendType" SG_ 2549088334 SWA_Subsystemaktiv 0;
BA_ "GenSigSwitchedByIgnition" SG_ 2549088334 SWA_Subsystemaktiv 0;
BA_ "GenSigSendType" SG_ 2549088334 SWA_Transport_Mode 0;
BA_ "GenSigSwitchedByIgnition" SG_ 2549088334 SWA_Transport_Mode 0;
BA_ "GenSigSendType" SG_ 2549088394 KN_SWA_Slave_BusKnockOutTimer 0;
BA_ "GenSigSwitchedByIgnition" SG_ 2549088394 KN_SWA_Slave_BusKnockOutTimer 0;
BA_ "GenSigSendType" SG_ 2549088394 NM_SWA_2_Wakeup 0;
BA_ "NWM-WakeupAllowed" SG_ 2549088394 NM_SWA_2_Wakeup 1;
BA_ "GenSigSwitchedByIgnition" SG_ 2549088394 NM_SWA_2_Wakeup 0;
BA_ "GenSigSendType" SG_ 2549088394 SWA_2_Abschaltstufe 0;
BA_ "GenSigSendType" SG_ 2549088394 SWA_2_KD_Fehler 0;
BA_ "GenSigSendType" SG_ 2549088394 SWA_2_KompSchutz 0;
BA_ "GenSigSendType" SG_ 2549088394 SWA_2_Lokalaktiv 0;
BA_ "GenSigSwitchedByIgnition" SG_ 2549088394 SWA_2_Lokalaktiv 0;
BA_ "GenSigSendType" SG_ 2549088394 SWA_2_Nachlauftyp 0;
BA_ "GenSigSendType" SG_ 2549088394 SWA_2_SNI 0;
BA_ "GenSigStartValue" SG_ 2549088394 SWA_2_SNI 138;
BA_ "GenSigSendType" SG_ 2549088394 SWA_2_Subsystemaktiv 0;
BA_ "GenSigSwitchedByIgnition" SG_ 2549088394 SWA_2_Subsystemaktiv 0;
BA_ "GenSigSendType" SG_ 2549088394 SWA_2_Transport_Mode 0;
BA_ "GenSigSendType" SG_ 779 KBI_ABS_Lampe 0;
BA_ "GenSigSwitchedByIgnition" SG_ 779 KBI_ABS_Lampe 0;
BA_ "GenSigSendType" SG_ 779 KBI_Airbag_Lampe 0;
BA_ "GenSigSwitchedByIgnition" SG_ 779 KBI_Airbag_Lampe 0;
BA_ "GenSigSendType" SG_ 779 KBI_angez_Geschw 0;
BA_ "GenSigSwitchedByIgnition" SG_ 779 KBI_angez_Geschw 0;
BA_ "GenSigSendType" SG_ 779 KBI_Anzeigefehler_LDW 0;
BA_ "GenSigSwitchedByIgnition" SG_ 779 KBI_Anzeigefehler_LDW 0;
BA_ "GenSigSendType" SG_ 779 KBI_Anzeigefehler_NV 0;
BA_ "GenSigSwitchedByIgnition" SG_ 779 KBI_Anzeigefehler_NV 0;
BA_ "GenSigSendType" SG_ 779 KBI_Anzeigefehler_SWA 0;
BA_ "GenSigSwitchedByIgnition" SG_ 779 KBI_Anzeigefehler_SWA 0;
BA_ "GenSigSendType" SG_ 779 KBI_Anzeigestatus_ACC 0;
BA_ "GenSigSwitchedByIgnition" SG_ 779 KBI_Anzeigestatus_ACC 0;
BA_ "GenSigSendType" SG_ 779 KBI_Anzeigestatus_GRA 0;
BA_ "GenSigSwitchedByIgnition" SG_ 779 KBI_Anzeigestatus_GRA 0;
BA_ "Fehlerwert" SG_ 779 KBI_Anzeigestatus_GRA 3;
BA_ "GenSigSendType" SG_ 779 KBI_Anzeigestatus_LIM 0;
BA_ "GenSigSwitchedByIgnition" SG_ 779 KBI_Anzeigestatus_LIM 0;
BA_ "Fehlerwert" SG_ 779 KBI_Anzeigestatus_LIM 3;
BA_ "GenSigSendType" SG_ 779 KBI_ARA_in_Anzeige 0;
BA_ "GenSigSwitchedByIgnition" SG_ 779 KBI_ARA_in_Anzeige 0;
BA_ "GenSigSendType" SG_ 779 KBI_BKL_Lampe 0;
BA_ "GenSigSwitchedByIgnition" SG_ 779 KBI_BKL_Lampe 0;
BA_ "GenSigSendType" SG_ 779 KBI_Einheit_Tacho 0;
BA_ "GenSigSwitchedByIgnition" SG_ 779 KBI_Einheit_Tacho 0;
BA_ "GenSigSendType" SG_ 779 KBI_ESP_Lampe 0;
BA_ "GenSigSwitchedByIgnition" SG_ 779 KBI_ESP_Lampe 0;
BA_ "GenSigSendType" SG_ 779 KBI_Fehler_Anzeige_ACC 0;
BA_ "GenSigSwitchedByIgnition" SG_ 779 KBI_Fehler_Anzeige_ACC 0;
BA_ "GenSigSendType" SG_ 779 KBI_Handbremse 0;
BA_ "GenSigSwitchedByIgnition" SG_ 779 KBI_Handbremse 0;
BA_ "GenSigSendType" SG_ 779 KBI_im_Stellgliedtest 0;
BA_ "GenSigSwitchedByIgnition" SG_ 779 KBI_im_Stellgliedtest 0;
BA_ "GenSigSendType" SG_ 779 KBI_Konsistenz_ACC 0;
BA_ "GenSigSwitchedByIgnition" SG_ 779 KBI_Konsistenz_ACC 0;
BA_ "GenSigSendType" SG_ 779 KBI_Lenkung_Lampe 0;
BA_ "GenSigSwitchedByIgnition" SG_ 779 KBI_Lenkung_Lampe 0;
BA_ "GenSigSendType" SG_ 779 KBI_MFA_v_Einheit_01 0;
BA_ "GenSigSwitchedByIgnition" SG_ 779 KBI_MFA_v_Einheit_01 0;
BA_ "GenSigSendType" SG_ 779 KBI_NV_in_Anzeige 0;
BA_ "GenSigSwitchedByIgnition" SG_ 779 KBI_NV_in_Anzeige 0;
BA_ "GenSigSendType" SG_ 779 KBI_PLA_in_Anzeige 0;
BA_ "GenSigSwitchedByIgnition" SG_ 779 KBI_PLA_in_Anzeige 0;
BA_ "GenSigSendType" SG_ 779 KBI_SILA_gueltig 0;
BA_ "GenSigSwitchedByIgnition" SG_ 779 KBI_SILA_gueltig 0;
BA_ "GenSigSendType" SG_ 779 KBI_Systemstatus 0;
BA_ "GenSigSwitchedByIgnition" SG_ 779 KBI_Systemstatus 0;
BA_ "GenSigSendType" SG_ 779 KBI_Tankwarnung 0;
BA_ "GenSigSwitchedByIgnition" SG_ 779 KBI_Tankwarnung 0;
BA_ "GenSigSendType" SG_ 779 KBI_Tankwarnung_ungueltig 0;
BA_ "GenSigStartValue" SG_ 779 KBI_Tankwarnung_ungueltig 1;
BA_ "GenSigSwitchedByIgnition" SG_ 779 KBI_Tankwarnung_ungueltig 0;
BA_ "GenSigSendType" SG_ 779 KBI_Taster_Fahrwerk 0;
BA_ "GenSigSwitchedByIgnition" SG_ 779 KBI_Taster_Fahrwerk 0;
BA_ "GenSigSendType" SG_ 779 KBI_Taster_Lift 0;
BA_ "GenSigSwitchedByIgnition" SG_ 779 KBI_Taster_Lift 0;
BA_ "GenSigSendType" SG_ 779 KBI_V_Digital 0;
BA_ "GenSigSwitchedByIgnition" SG_ 779 KBI_V_Digital 0;
BA_ "GenSigSendType" SG_ 779 KBI_Vorglueh_System_Lampe 0;
BA_ "GenSigSwitchedByIgnition" SG_ 779 KBI_Vorglueh_System_Lampe 0;
BA_ "GenSigSendType" SG_ 779 Kombi_01_BZ 0;
BA_ "GenSigFuncType" SG_ 779 Kombi_01_BZ 1;
BA_ "GenSigSwitchedByIgnition" SG_ 779 Kombi_01_BZ 0;
BA_ "GenSigSendType" SG_ 1719 KBI_aktive_Laengsfunktion 3;
BA_ "GenSigSendType" SG_ 1719 KBI_Aussen_Temp_gef 0;
BA_ "GenSigStartValue" SG_ 1719 KBI_Aussen_Temp_gef 254;
BA_ "GenSigSwitchedByIgnition" SG_ 1719 KBI_Aussen_Temp_gef 0;
BA_ "Fehlerwert" SG_ 1719 KBI_Aussen_Temp_gef 255;
BA_ "GenSigSendType" SG_ 1719 KBI_FoD_PopUP_Quittiert 3;
BA_ "GenSigSendType" SG_ 1719 KBI_FStatus_Tank 0;
BA_ "GenSigSwitchedByIgnition" SG_ 1719 KBI_FStatus_Tank 0;
BA_ "GenSigSendType" SG_ 1719 KBI_GRA_im_ACC 3;
BA_ "GenSigSwitchedByIgnition" SG_ 1719 KBI_GRA_im_ACC 0;
BA_ "GenSigSendType" SG_ 1719 KBI_Inhalt_Tank 0;
BA_ "GenSigStartValue" SG_ 1719 KBI_Inhalt_Tank 126;
BA_ "GenSigSwitchedByIgnition" SG_ 1719 KBI_Inhalt_Tank 0;
BA_ "Fehlerwert" SG_ 1719 KBI_Inhalt_Tank 127;
BA_ "GenSigSendType" SG_ 1719 KBI_Kilometerstand 0;
BA_ "GenSigStartValue" SG_ 1719 KBI_Kilometerstand 1048574;
BA_ "GenSigSwitchedByIgnition" SG_ 1719 KBI_Kilometerstand 0;
BA_ "Fehlerwert" SG_ 1719 KBI_Kilometerstand 1048575;
BA_ "GenSigSendType" SG_ 1719 KBI_LVDS_Lock 3;
BA_ "GenSigSwitchedByIgnition" SG_ 1719 KBI_LVDS_Lock 0;
BA_ "GenSigSendType" SG_ 1719 KBI_Oelwechsel_durchgefuehrt 0;
BA_ "GenSigSwitchedByIgnition" SG_ 1719 KBI_Oelwechsel_durchgefuehrt 0;
BA_ "GenSigSendType" SG_ 1719 KBI_QBit_Aussen_Temp_gef 0;
BA_ "GenSigStartValue" SG_ 1719 KBI_QBit_Aussen_Temp_gef 1;
BA_ "GenSigSwitchedByIgnition" SG_ 1719 KBI_QBit_Aussen_Temp_gef 0;
BA_ "GenSigSendType" SG_ 1719 KBI_RDK_Kalibrier_Anf 3;
BA_ "GenSigSwitchedByIgnition" SG_ 1719 KBI_RDK_Kalibrier_Anf 0;
BA_ "GenSigSendType" SG_ 1719 KBI_Reserve_Warnung_Sek 3;
BA_ "GenSigSwitchedByIgnition" SG_ 1719 KBI_Reserve_Warnung_Sek 0;
BA_ "GenSigSendType" SG_ 1719 KBI_Standzeit_02 0;
BA_ "GenSigStartValue" SG_ 1719 KBI_Standzeit_02 131070;
BA_ "GenSigSwitchedByIgnition" SG_ 1719 KBI_Standzeit_02 0;
BA_ "Fehlerwert" SG_ 1719 KBI_Standzeit_02 131071;
BA_ "GenSigSendType" SG_ 1614 KBI_HUD_Data_01 3;
BA_ "GenSigSwitchedByIgnition" SG_ 1614 KBI_HUD_Data_01 0;
BA_ "GenSigSendType" SG_ 1614 KBI_HUD_Data_02 3;
BA_ "GenSigSwitchedByIgnition" SG_ 1614 KBI_HUD_Data_02 0;
BA_ "GenSigSendType" SG_ 1614 KBI_HUD_Data_03 3;
BA_ "GenSigSwitchedByIgnition" SG_ 1614 KBI_HUD_Data_03 0;
BA_ "GenSigSendType" SG_ 1614 KBI_HUD_Data_04 3;
BA_ "GenSigSwitchedByIgnition" SG_ 1614 KBI_HUD_Data_04 0;
BA_ "GenSigSendType" SG_ 1614 KBI_HUD_Data_05 3;
BA_ "GenSigSwitchedByIgnition" SG_ 1614 KBI_HUD_Data_05 0;
BA_ "GenSigSendType" SG_ 1614 KBI_HUD_Data_06 3;
BA_ "GenSigSwitchedByIgnition" SG_ 1614 KBI_HUD_Data_06 0;
BA_ "GenSigSendType" SG_ 1614 KBI_HUD_Data_07 3;
BA_ "GenSigSwitchedByIgnition" SG_ 1614 KBI_HUD_Data_07 0;
BA_ "GenSigSendType" SG_ 1614 KBI_HUD_Data_08 3;
BA_ "GenSigSwitchedByIgnition" SG_ 1614 KBI_HUD_Data_08 0;
BA_ "GenSigSendType" SG_ 2549874983 KS_Nightvision_Req_Data 3;
BA_ "GenSigFuncType" SG_ 2549874983 KS_Nightvision_Req_Data 9;
BA_ "GenSigSwitchedByIgnition" SG_ 2549874983 KS_Nightvision_Req_Data 0;
BA_ "GenSigSendType" SG_ 2550006055 KS_Nightvision_Resp_Data 3;
BA_ "GenSigFuncType" SG_ 2550006055 KS_Nightvision_Resp_Data 9;
BA_ "GenSigSendType" SG_ 2549875082 KS_SWA_2_Req_Data 3;
BA_ "GenSigFuncType" SG_ 2549875082 KS_SWA_2_Req_Data 9;
BA_ "GenSigSwitchedByIgnition" SG_ 2549875082 KS_SWA_2_Req_Data 0;
BA_ "GenSigSendType" SG_ 2550006154 KS_SWA_2_Resp_Data 3;
BA_ "GenSigFuncType" SG_ 2550006154 KS_SWA_2_Resp_Data 9;
BA_ "GenSigSwitchedByIgnition" SG_ 2550006154 KS_SWA_2_Resp_Data 0;
BA_ "GenSigSendType" SG_ 2549875022 KS_SWA_Req_Data 3;
BA_ "GenSigFuncType" SG_ 2549875022 KS_SWA_Req_Data 9;
BA_ "GenSigSwitchedByIgnition" SG_ 2549875022 KS_SWA_Req_Data 0;
BA_ "GenSigSendType" SG_ 2550006094 KS_SWA_Resp_Data 3;
BA_ "GenSigFuncType" SG_ 2550006094 KS_SWA_Resp_Data 9;
BA_ "GenSigSwitchedByIgnition" SG_ 2550006094 KS_SWA_Resp_Data 0;
BA_ "GenSigSendType" SG_ 160 EPS_04_BZ 0;
BA_ "GenSigFuncType" SG_ 160 EPS_04_BZ 1;
BA_ "GenSigSwitchedByIgnition" SG_ 160 EPS_04_BZ 0;
BA_ "GenSigSendType" SG_ 160 EPS_04_CRC 0;
BA_ "GenSigFuncType" SG_ 160 EPS_04_CRC 2;
BA_ "GenSigSwitchedByIgnition" SG_ 160 EPS_04_CRC 0;
BA_ "GenSigSendType" SG_ 160 EPS_AWA_Status 0;
BA_ "GenSigStartValue" SG_ 160 EPS_AWA_Status 14;
BA_ "GenSigSwitchedByIgnition" SG_ 160 EPS_AWA_Status 0;
BA_ "GenSigSendType" SG_ 160 EPS_FAS_Regelgroesse 0;
BA_ "GenSigStartValue" SG_ 160 EPS_FAS_Regelgroesse 62;
BA_ "GenSigSwitchedByIgnition" SG_ 160 EPS_FAS_Regelgroesse 0;
BA_ "Fehlerwert" SG_ 160 EPS_FAS_Regelgroesse 63;
BA_ "GenSigSendType" SG_ 160 EPS_FAS_VZ_Regelgroesse 0;
BA_ "GenSigSwitchedByIgnition" SG_ 160 EPS_FAS_VZ_Regelgroesse 0;
BA_ "GenSigSendType" SG_ 160 EPS_Lenkmoment_AbsReduz 0;
BA_ "GenSigStartValue" SG_ 160 EPS_Lenkmoment_AbsReduz 14;
BA_ "GenSigSwitchedByIgnition" SG_ 160 EPS_Lenkmoment_AbsReduz 0;
BA_ "Fehlerwert" SG_ 160 EPS_Lenkmoment_AbsReduz 15;
BA_ "GenSigSendType" SG_ 160 EPS_Motormoment 0;
BA_ "GenSigStartValue" SG_ 160 EPS_Motormoment 254;
BA_ "GenSigSwitchedByIgnition" SG_ 160 EPS_Motormoment 0;
BA_ "Fehlerwert" SG_ 160 EPS_Motormoment 255;
BA_ "GenSigSendType" SG_ 160 EPS_QBit_Zahnstangen_Pos 0;
BA_ "GenSigSwitchedByIgnition" SG_ 160 EPS_QBit_Zahnstangen_Pos 0;
BA_ "GenSigSendType" SG_ 160 EPS_STA_Status 0;
BA_ "GenSigStartValue" SG_ 160 EPS_STA_Status 14;
BA_ "GenSigSwitchedByIgnition" SG_ 160 EPS_STA_Status 0;
BA_ "GenSigSendType" SG_ 160 EPS_Versorgungsspannung 0;
BA_ "GenSigStartValue" SG_ 160 EPS_Versorgungsspannung 254;
BA_ "GenSigSwitchedByIgnition" SG_ 160 EPS_Versorgungsspannung 0;
BA_ "Fehlerwert" SG_ 160 EPS_Versorgungsspannung 255;
BA_ "GenSigSendType" SG_ 160 EPS_Versorgungsstatus 0;
BA_ "GenSigSwitchedByIgnition" SG_ 160 EPS_Versorgungsstatus 0;
BA_ "GenSigSendType" SG_ 160 EPS_VZ_Zahnstangenposition 0;
BA_ "GenSigSwitchedByIgnition" SG_ 160 EPS_VZ_Zahnstangenposition 0;
BA_ "GenSigSendType" SG_ 160 EPS_Zahnstangen_Pos 0;
BA_ "GenSigStartValue" SG_ 160 EPS_Zahnstangen_Pos 4094;
BA_ "GenSigSwitchedByIgnition" SG_ 160 EPS_Zahnstangen_Pos 0;
BA_ "Fehlerwert" SG_ 160 EPS_Zahnstangen_Pos 4095;
BA_ "GenSigSendType" SG_ 981 BCM1_Abblendlicht_Anf 0;
BA_ "GenSigSwitchedByIgnition" SG_ 981 BCM1_Abblendlicht_Anf 0;
BA_ "GenSigSendType" SG_ 981 BCM1_Adaptive_Lichtvert_Anf 0;
BA_ "GenSigSwitchedByIgnition" SG_ 981 BCM1_Adaptive_Lichtvert_Anf 0;
BA_ "GenSigSendType" SG_ 981 BCM1_Allwetterlicht_Anf 0;
BA_ "GenSigSwitchedByIgnition" SG_ 981 BCM1_Allwetterlicht_Anf 0;
BA_ "GenSigSendType" SG_ 981 BCM1_Animationssperrung 3;
BA_ "GenSigStartValue" SG_ 981 BCM1_Animationssperrung 1;
BA_ "GenSigSwitchedByIgnition" SG_ 981 BCM1_Animationssperrung 0;
BA_ "GenSigSendType" SG_ 981 BCM1_Autobahnlicht_Anf 0;
BA_ "GenSigSwitchedByIgnition" SG_ 981 BCM1_Autobahnlicht_Anf 0;
BA_ "GenSigSendType" SG_ 981 BCM1_CH_aktiv 0;
BA_ "NWM-WakeupAllowed" SG_ 981 BCM1_CH_aktiv 1;
BA_ "GenSigSwitchedByIgnition" SG_ 981 BCM1_CH_aktiv 0;
BA_ "GenSigSendType" SG_ 981 BCM1_CH_LH_aktiv 0;
BA_ "GenSigSwitchedByIgnition" SG_ 981 BCM1_CH_LH_aktiv 0;
BA_ "GenSigSendType" SG_ 981 BCM1_Fernlicht_Anf 0;
BA_ "GenSigSwitchedByIgnition" SG_ 981 BCM1_Fernlicht_Anf 0;
BA_ "GenSigSendType" SG_ 981 BCM1_FOD_Sperrung_Animationen_HL 3;
BA_ "GenSigStartValue" SG_ 981 BCM1_FOD_Sperrung_Animationen_HL 2;
BA_ "GenSigSendType" SG_ 981 BCM1_FoD_Sperrung_WiBli 3;
BA_ "GenSigStartValue" SG_ 981 BCM1_FoD_Sperrung_WiBli 2;
BA_ "GenSigSendType" SG_ 981 BCM1_Gleitende_Leuchtw_Anf 3;
BA_ "GenSigSwitchedByIgnition" SG_ 981 BCM1_Gleitende_Leuchtw_Anf 0;
BA_ "GenSigSendType" SG_ 981 BCM1_GLW_Fernlicht_Anf 3;
BA_ "GenSigSwitchedByIgnition" SG_ 981 BCM1_GLW_Fernlicht_Anf 0;
BA_ "GenSigSendType" SG_ 981 BCM1_Kurvenlicht_links_Anf 0;
BA_ "GenSigSwitchedByIgnition" SG_ 981 BCM1_Kurvenlicht_links_Anf 0;
BA_ "GenSigSendType" SG_ 981 BCM1_Kurvenlicht_rechts_Anf 0;
BA_ "GenSigSwitchedByIgnition" SG_ 981 BCM1_Kurvenlicht_rechts_Anf 0;
BA_ "GenSigSendType" SG_ 981 BCM1_LH_aktiv 0;
BA_ "NWM-WakeupAllowed" SG_ 981 BCM1_LH_aktiv 1;
BA_ "GenSigSwitchedByIgnition" SG_ 981 BCM1_LH_aktiv 0;
BA_ "GenSigSendType" SG_ 981 BCM1_Nebellicht_Anf 0;
BA_ "GenSigSwitchedByIgnition" SG_ 981 BCM1_Nebellicht_Anf 0;
BA_ "GenSigSendType" SG_ 981 BCM1_Nebelschluss_Ahg_Anf 0;
BA_ "GenSigSwitchedByIgnition" SG_ 981 BCM1_Nebelschluss_Ahg_Anf 0;
BA_ "GenSigSendType" SG_ 981 BCM1_Nebelschluss_Fzg_Anf 0;
BA_ "GenSigSwitchedByIgnition" SG_ 981 BCM1_Nebelschluss_Fzg_Anf 0;
BA_ "GenSigSendType" SG_ 981 BCM1_Parklicht_li_Anf 0;
BA_ "GenSigSwitchedByIgnition" SG_ 981 BCM1_Parklicht_li_Anf 0;
BA_ "GenSigSendType" SG_ 981 BCM1_Parklicht_re_Anf 0;
BA_ "GenSigSwitchedByIgnition" SG_ 981 BCM1_Parklicht_re_Anf 0;
BA_ "GenSigSendType" SG_ 981 BCM1_Regenlicht_Anf 0;
BA_ "GenSigSwitchedByIgnition" SG_ 981 BCM1_Regenlicht_Anf 0;
BA_ "GenSigSendType" SG_ 981 BCM1_Schlusslicht_Anf 0;
BA_ "GenSigSwitchedByIgnition" SG_ 981 BCM1_Schlusslicht_Anf 0;
BA_ "GenSigSendType" SG_ 981 BCM1_Signaturlicht_Anf 0;
BA_ "GenSigSwitchedByIgnition" SG_ 981 BCM1_Signaturlicht_Anf 0;
BA_ "GenSigSendType" SG_ 981 BCM1_Standlicht_Anf 0;
BA_ "GenSigSwitchedByIgnition" SG_ 981 BCM1_Standlicht_Anf 0;
BA_ "GenSigSendType" SG_ 981 BCM1_Tagfahrlicht_Anf 0;
BA_ "GenSigSwitchedByIgnition" SG_ 981 BCM1_Tagfahrlicht_Anf 0;
BA_ "GenSigSendType" SG_ 981 BCM1_Touristen_Licht_Anf 0;
BA_ "GenSigSwitchedByIgnition" SG_ 981 BCM1_Touristen_Licht_Anf 0;
BA_ "GenSigSendType" SG_ 981 BCM1_Umfeldleuchten_Anf 0;
BA_ "GenSigSwitchedByIgnition" SG_ 981 BCM1_Umfeldleuchten_Anf 0;
BA_ "GenSigSendType" SG_ 981 BCM_Rueckfahrlicht_Anf 0;
BA_ "GenSigSwitchedByIgnition" SG_ 981 BCM_Rueckfahrlicht_Anf 0;
BA_ "GenSigSendType" SG_ 981 Licht_Anf_01_BZ 0;
BA_ "GenSigFuncType" SG_ 981 Licht_Anf_01_BZ 1;
BA_ "GenSigSwitchedByIgnition" SG_ 981 Licht_Anf_01_BZ 0;
BA_ "GenSigSendType" SG_ 981 Licht_Anf_01_CRC 0;
BA_ "GenSigFuncType" SG_ 981 Licht_Anf_01_CRC 2;
BA_ "GenSigSwitchedByIgnition" SG_ 981 Licht_Anf_01_CRC 0;
BA_ "GenSigSendType" SG_ 1624 BCM1_Licht_Dunkelheit_aktiv 3;
BA_ "GenSigSwitchedByIgnition" SG_ 1624 BCM1_Licht_Dunkelheit_aktiv 0;
BA_ "GenSigSendType" SG_ 1624 BCM1_Linksverkehr 0;
BA_ "GenSigSwitchedByIgnition" SG_ 1624 BCM1_Linksverkehr 0;
BA_ "GenSigSendType" SG_ 1624 Licht_Vorne_01_BZ 0;
BA_ "GenSigFuncType" SG_ 1624 Licht_Vorne_01_BZ 1;
BA_ "GenSigSendType" SG_ 1624 Licht_Vorne_01_CRC 0;
BA_ "GenSigFuncType" SG_ 1624 Licht_Vorne_01_CRC 2;
BA_ "GenSigSendType" SG_ 1624 LV_Abbiegelicht_li_def 0;
BA_ "GenSigSwitchedByIgnition" SG_ 1624 LV_Abbiegelicht_li_def 0;
BA_ "GenSigSendType" SG_ 1624 LV_Abbiegelicht_re_def 0;
BA_ "GenSigSwitchedByIgnition" SG_ 1624 LV_Abbiegelicht_re_def 0;
BA_ "GenSigSendType" SG_ 1624 LV_Abblend_Fernlicht_li_def 0;
BA_ "GenSigSwitchedByIgnition" SG_ 1624 LV_Abblend_Fernlicht_li_def 0;
BA_ "GenSigSendType" SG_ 1624 LV_Abblend_Fernlicht_re_def 0;
BA_ "GenSigSwitchedByIgnition" SG_ 1624 LV_Abblend_Fernlicht_re_def 0;
BA_ "GenSigSendType" SG_ 1624 LV_Abblendlicht_Anzeige 3;
BA_ "GenSigSwitchedByIgnition" SG_ 1624 LV_Abblendlicht_Anzeige 0;
BA_ "GenSigSendType" SG_ 1624 LV_Abblendlicht_li_def 0;
BA_ "GenSigSwitchedByIgnition" SG_ 1624 LV_Abblendlicht_li_def 0;
BA_ "GenSigSendType" SG_ 1624 LV_Abblendlicht_re_def 0;
BA_ "GenSigSwitchedByIgnition" SG_ 1624 LV_Abblendlicht_re_def 0;
BA_ "GenSigSendType" SG_ 1624 LV_Abblendlicht_TFL_li_def 0;
BA_ "GenSigSwitchedByIgnition" SG_ 1624 LV_Abblendlicht_TFL_li_def 0;
BA_ "GenSigSendType" SG_ 1624 LV_Abblendlicht_TFL_re_def 0;
BA_ "GenSigSwitchedByIgnition" SG_ 1624 LV_Abblendlicht_TFL_re_def 0;
BA_ "GenSigSendType" SG_ 1624 LV_AFL_aktiv_Anzeige 3;
BA_ "GenSigSwitchedByIgnition" SG_ 1624 LV_AFL_aktiv_Anzeige 0;
BA_ "GenSigSendType" SG_ 1624 LV_AFL_defekt 3;
BA_ "GenSigSwitchedByIgnition" SG_ 1624 LV_AFL_defekt 0;
BA_ "GenSigSendType" SG_ 1624 LV_Aussenlicht_def 3;
BA_ "GenSigSwitchedByIgnition" SG_ 1624 LV_Aussenlicht_def 0;
BA_ "GenSigSendType" SG_ 1624 LV_Blinker_li_def 3;
BA_ "GenSigSwitchedByIgnition" SG_ 1624 LV_Blinker_li_def 0;
BA_ "GenSigSendType" SG_ 1624 LV_Blinker_re_def 3;
BA_ "GenSigSwitchedByIgnition" SG_ 1624 LV_Blinker_re_def 0;
BA_ "GenSigSendType" SG_ 1624 LV_Blinker_VL_aktiv 3;
BA_ "GenSigSwitchedByIgnition" SG_ 1624 LV_Blinker_VL_aktiv 0;
BA_ "GenSigSendType" SG_ 1624 LV_Blinker_VR_aktiv 3;
BA_ "GenSigSwitchedByIgnition" SG_ 1624 LV_Blinker_VR_aktiv 0;
BA_ "GenSigSendType" SG_ 1624 LV_Blk_li_Seite_def 0;
BA_ "GenSigSwitchedByIgnition" SG_ 1624 LV_Blk_li_Seite_def 0;
BA_ "GenSigSendType" SG_ 1624 LV_Blk_re_Seite_def 0;
BA_ "GenSigSwitchedByIgnition" SG_ 1624 LV_Blk_re_Seite_def 0;
BA_ "GenSigSendType" SG_ 1624 LV_Fernlicht_Anzeige 3;
BA_ "GenSigSwitchedByIgnition" SG_ 1624 LV_Fernlicht_Anzeige 0;
BA_ "GenSigSendType" SG_ 1624 LV_Fernlicht_li_def 0;
BA_ "GenSigSwitchedByIgnition" SG_ 1624 LV_Fernlicht_li_def 0;
BA_ "GenSigSendType" SG_ 1624 LV_Fernlicht_re_def 0;
BA_ "GenSigSwitchedByIgnition" SG_ 1624 LV_Fernlicht_re_def 0;
BA_ "GenSigSendType" SG_ 1624 LV_FLA_aktiv_Anzeige 3;
BA_ "GenSigSwitchedByIgnition" SG_ 1624 LV_FLA_aktiv_Anzeige 0;
BA_ "GenSigSendType" SG_ 1624 LV_FLA_defekt 0;
BA_ "GenSigSwitchedByIgnition" SG_ 1624 LV_FLA_defekt 0;
BA_ "GenSigSendType" SG_ 1624 LV_FLA_Sensor_blockiert 0;
BA_ "GenSigSwitchedByIgnition" SG_ 1624 LV_FLA_Sensor_blockiert 0;
BA_ "GenSigSendType" SG_ 1624 LV_LED_Scheinwerfer_li_def 0;
BA_ "GenSigSwitchedByIgnition" SG_ 1624 LV_LED_Scheinwerfer_li_def 0;
BA_ "GenSigSendType" SG_ 1624 LV_LED_Scheinwerfer_re_def 0;
BA_ "GenSigSwitchedByIgnition" SG_ 1624 LV_LED_Scheinwerfer_re_def 0;
BA_ "GenSigSendType" SG_ 1624 LV_MXB_Status_Anzeige 3;
BA_ "GenSigSwitchedByIgnition" SG_ 1624 LV_MXB_Status_Anzeige 0;
BA_ "GenSigSendType" SG_ 1624 LV_Nebellicht_Anzeige 3;
BA_ "GenSigSwitchedByIgnition" SG_ 1624 LV_Nebellicht_Anzeige 0;
BA_ "GenSigSendType" SG_ 1624 LV_Nebellicht_li_def 0;
BA_ "GenSigSwitchedByIgnition" SG_ 1624 LV_Nebellicht_li_def 0;
BA_ "GenSigSendType" SG_ 1624 LV_Nebellicht_re_def 0;
BA_ "GenSigSwitchedByIgnition" SG_ 1624 LV_Nebellicht_re_def 0;
BA_ "GenSigSendType" SG_ 1624 LV_Nebellicht_TFL_li_def 0;
BA_ "GenSigSwitchedByIgnition" SG_ 1624 LV_Nebellicht_TFL_li_def 0;
BA_ "GenSigSendType" SG_ 1624 LV_Nebellicht_TFL_re_def 0;
BA_ "GenSigSwitchedByIgnition" SG_ 1624 LV_Nebellicht_TFL_re_def 0;
BA_ "GenSigSendType" SG_ 1624 LV_Nebelschlusslicht_Anzeige 3;
BA_ "GenSigSwitchedByIgnition" SG_ 1624 LV_Nebelschlusslicht_Anzeige 0;
BA_ "GenSigSendType" SG_ 1624 LV_Standlicht_Anzeige 3;
BA_ "GenSigSwitchedByIgnition" SG_ 1624 LV_Standlicht_Anzeige 0;
BA_ "GenSigSendType" SG_ 1624 LV_Standlicht_li_def 0;
BA_ "GenSigSwitchedByIgnition" SG_ 1624 LV_Standlicht_li_def 0;
BA_ "GenSigSendType" SG_ 1624 LV_Standlicht_re_def 0;
BA_ "GenSigSwitchedByIgnition" SG_ 1624 LV_Standlicht_re_def 0;
BA_ "GenSigSendType" SG_ 1624 LV_Standlicht_TFL_li_def 0;
BA_ "GenSigSwitchedByIgnition" SG_ 1624 LV_Standlicht_TFL_li_def 0;
BA_ "GenSigSendType" SG_ 1624 LV_Standlicht_TFL_re_def 0;
BA_ "GenSigSwitchedByIgnition" SG_ 1624 LV_Standlicht_TFL_re_def 0;
BA_ "GenSigSendType" SG_ 1624 LV_Tagfahrlicht_Anzeige 3;
BA_ "GenSigSwitchedByIgnition" SG_ 1624 LV_Tagfahrlicht_Anzeige 0;
BA_ "GenSigSendType" SG_ 1624 LV_Tagfahrlicht_li_def 0;
BA_ "GenSigSwitchedByIgnition" SG_ 1624 LV_Tagfahrlicht_li_def 0;
BA_ "GenSigSendType" SG_ 1624 LV_Tagfahrlicht_re_def 0;
BA_ "GenSigSwitchedByIgnition" SG_ 1624 LV_Tagfahrlicht_re_def 0;
BA_ "GenSigSendType" SG_ 917 AFS_Abbiegelicht_Dimm_Anf 0;
BA_ "GenSigSendType" SG_ 917 AFS_Abbiegelicht_li_Anf 0;
BA_ "GenSigSendType" SG_ 917 AFS_Abbiegelicht_re_Anf 0;
BA_ "GenSigSendType" SG_ 917 AFS_adaptive_LV_verbaut 0;
BA_ "GenSigSendType" SG_ 917 AFS_Allwetterlicht 0;
BA_ "GenSigSendType" SG_ 917 AFS_Charisma_FahrPr 0;
BA_ "GenSigSendType" SG_ 917 AFS_Charisma_Status 0;
BA_ "GenSigSendType" SG_ 917 AFS_Charisma_Umschaltung 3;
BA_ "GenSigSendType" SG_ 917 AFS_Ersatzlicht_Links 0;
BA_ "GenSigSendType" SG_ 917 AFS_Ersatzlicht_Rechts 0;
BA_ "GenSigSendType" SG_ 917 AFS_Fehlertext 0;
BA_ "GenSigSendType" SG_ 917 AFS_Fernlicht_li_defekt 0;
BA_ "GenSigSendType" SG_ 917 AFS_Fernlicht_re_defekt 0;
BA_ "GenSigSendType" SG_ 917 AFS_Fernlicht_Status 3;
BA_ "GenSigSendType" SG_ 917 AFS_Lampe 0;
BA_ "GenSigSendType" SG_ 917 AFS_LED_Blinkmode 0;
BA_ "GenSigSendType" SG_ 917 AFS_Status_adaptive_LV 0;
BA_ "GenSigStartValue" SG_ 917 AFS_Status_adaptive_LV 1;
BA_ "GenSigSendType" SG_ 917 AFS_Verfuegbarkeit_GLW 0;
BA_ "GenSigStartValue" SG_ 917 AFS_Verfuegbarkeit_GLW 1;
BA_ "GenSigSendType" SG_ 917 GLW_Sensor_blockiert 0;
BA_ "GenSigSendType" SG_ 917 LWR_AFS_01_BZ 0;
BA_ "GenSigFuncType" SG_ 917 LWR_AFS_01_BZ 1;
BA_ "GenSigSendType" SG_ 917 LWR_AFS_Grundeinstellung 0;
BA_ "GenSigSendType" SG_ 917 LWR_AFS_Parametrisierung 0;
BA_ "GenSigSendType" SG_ 917 LWR_Hoehenwert_HL 0;
BA_ "GenSigStartValue" SG_ 917 LWR_Hoehenwert_HL 254;
BA_ "Fehlerwert" SG_ 917 LWR_Hoehenwert_HL 255;
BA_ "GenSigSendType" SG_ 917 LWR_Hoehenwert_VL 0;
BA_ "GenSigStartValue" SG_ 917 LWR_Hoehenwert_VL 254;
BA_ "Fehlerwert" SG_ 917 LWR_Hoehenwert_VL 255;
BA_ "GenSigSendType" SG_ 917 LWR_Initialisierungslauf 0;
BA_ "GenSigSendType" SG_ 917 LWR_Lampe 0;
BA_ "GenSigSendType" SG_ 917 LWR_Modus 0;
BA_ "GenSigSendType" SG_ 917 LWR_Pos_Schrittmotor 0;
BA_ "GenSigStartValue" SG_ 917 LWR_Pos_Schrittmotor 254;
BA_ "Fehlerwert" SG_ 917 LWR_Pos_Schrittmotor 255;
BA_ "GenSigSendType" SG_ 917 LWR_Reisemodus_Texte 0;
BA_ "GenSigSendType" SG_ 917 LWR_Sicherheitsposition_li 0;
BA_ "GenSigSendType" SG_ 917 LWR_Sicherheitsposition_re 0;
BA_ "GenSigSendType" SG_ 917 LWR_Touristenmodus_aktiv 0;
BA_ "GenSigSendType" SG_ 917 LWR_Touristenmodus_verbaut 0;
BA_ "GenSigSendType" SG_ 1153 DSSS_Warning 3;
BA_ "GenSigSwitchedByIgnition" SG_ 1153 DSSS_Warning 0;
BA_ "GenSigSendType" SG_ 1153 MIB_Tongenerator_PH_verfuegbar 3;
BA_ "GenSigSwitchedByIgnition" SG_ 1153 MIB_Tongenerator_PH_verfuegbar 0;
BA_ "GenSigSendType" SG_ 1153 MMI_Counter_Bedienevent 0;
BA_ "GenSigSwitchedByIgnition" SG_ 1153 MMI_Counter_Bedienevent 0;
BA_ "GenSigSendType" SG_ 1153 MMI_Gauges_active 3;
BA_ "GenSigSwitchedByIgnition" SG_ 1153 MMI_Gauges_active 0;
BA_ "GenSigSendType" SG_ 1153 MMI_SDS_aktiv 3;
BA_ "GenSigSwitchedByIgnition" SG_ 1153 MMI_SDS_aktiv 0;
BA_ "GenSigSendType" SG_ 1153 MMI_StartStopp_Info 3;
BA_ "GenSigSwitchedByIgnition" SG_ 1153 MMI_StartStopp_Info 0;
BA_ "Fehlerwert" SG_ 1153 MMI_StartStopp_Info 3;
BA_ "GenSigSendType" SG_ 1153 MMI_Telefon_aktiv 3;
BA_ "GenSigSwitchedByIgnition" SG_ 1153 MMI_Telefon_aktiv 0;
BA_ "GenSigSendType" SG_ 1153 MU_SecondDisplay 3;
BA_ "GenSigSwitchedByIgnition" SG_ 1153 MU_SecondDisplay 0;
BA_ "GenSigSendType" SG_ 1153 MU_Update_Time 0;
BA_ "GenSigSwitchedByIgnition" SG_ 1153 MU_Update_Time 0;
BA_ "GenSigSendType" SG_ 1153 Nav_FoD_Status 3;
BA_ "GenSigSwitchedByIgnition" SG_ 1153 Nav_FoD_Status 0;
BA_ "GenSigSendType" SG_ 1153 ZR_Kindersicherung_RSE 3;
BA_ "GenSigSwitchedByIgnition" SG_ 1153 ZR_Kindersicherung_RSE 0;
BA_ "GenSigSendType" SG_ 1153 ZR_LAPP_Sondermodus_Status 3;
BA_ "GenSigSendType" SG_ 1153 ZR_LoGeWa_Event_Kombiwarnung 3;
BA_ "GenSigSwitchedByIgnition" SG_ 1153 ZR_LoGeWa_Event_Kombiwarnung 0;
BA_ "GenSigSendType" SG_ 1153 ZR_MXB_Manoever_Ansage 3;
BA_ "GenSigSwitchedByIgnition" SG_ 1153 ZR_MXB_Manoever_Ansage 0;
BA_ "GenSigSendType" SG_ 1153 ZR_Parken_Sondermodus 3;
BA_ "GenSigSwitchedByIgnition" SG_ 1153 ZR_Parken_Sondermodus 0;
BA_ "GenSigSendType" SG_ 1153 ZR_RSE_aktivieren 3;
BA_ "GenSigSwitchedByIgnition" SG_ 1153 ZR_RSE_aktivieren 0;
BA_ "GenSigSendType" SG_ 1153 ZR_Rundenbewertung 3;
BA_ "GenSigStartValue" SG_ 1153 ZR_Rundenbewertung 14;
BA_ "GenSigSwitchedByIgnition" SG_ 1153 ZR_Rundenbewertung 0;
BA_ "GenSigSendType" SG_ 1153 ZR_Rundenfortschritt 3;
BA_ "GenSigStartValue" SG_ 1153 ZR_Rundenfortschritt 254;
BA_ "GenSigSwitchedByIgnition" SG_ 1153 ZR_Rundenfortschritt 0;
BA_ "GenSigActiveRepetitions" SG_ 1153 ZR_Sta_Inszenierung 5;
BA_ "GenSigSendType" SG_ 1153 ZR_Sta_Inszenierung 4;
BA_ "GenSigSwitchedByIgnition" SG_ 1153 ZR_Sta_Inszenierung 0;
BA_ "GenSigSendType" SG_ 1600 MO_Absperrventil_oeffnen 0;
BA_ "GenSigSwitchedByIgnition" SG_ 1600 MO_Absperrventil_oeffnen 0;
BA_ "GenSigSendType" SG_ 1600 MO_aktives_Getriebeheizen 0;
BA_ "GenSigSwitchedByIgnition" SG_ 1600 MO_aktives_Getriebeheizen 0;
BA_ "GenSigSendType" SG_ 1600 MO_Ansaugluft_Temp 0;
BA_ "GenSigStartValue" SG_ 1600 MO_Ansaugluft_Temp 254;
BA_ "GenSigSwitchedByIgnition" SG_ 1600 MO_Ansaugluft_Temp 0;
BA_ "Fehlerwert" SG_ 1600 MO_Ansaugluft_Temp 255;
BA_ "GenSigSendType" SG_ 1600 MO_Getriebe_kuehlen 0;
BA_ "GenSigSwitchedByIgnition" SG_ 1600 MO_Getriebe_kuehlen 0;
BA_ "GenSigSendType" SG_ 1600 MO_Heizungspumpenansteuerung 0;
BA_ "GenSigStartValue" SG_ 1600 MO_Heizungspumpenansteuerung 14;
BA_ "GenSigSwitchedByIgnition" SG_ 1600 MO_Heizungspumpenansteuerung 0;
BA_ "Fehlerwert" SG_ 1600 MO_Heizungspumpenansteuerung 13;
BA_ "GenSigSendType" SG_ 1600 MO_Hoeheninfo 0;
BA_ "GenSigSwitchedByIgnition" SG_ 1600 MO_Hoeheninfo 0;
BA_ "Fehlerwert" SG_ 1600 MO_Hoeheninfo 255;
BA_ "GenSigSendType" SG_ 1600 MO_HYB_Fehler_HV_Netz 0;
BA_ "GenSigSwitchedByIgnition" SG_ 1600 MO_HYB_Fehler_HV_Netz 0;
BA_ "GenSigSendType" SG_ 1600 MO_Kennfeldk 0;
BA_ "GenSigSwitchedByIgnition" SG_ 1600 MO_Kennfeldk 0;
BA_ "GenSigSendType" SG_ 1600 MO_KL15_Abschaltempfehlung 0;
BA_ "GenSigSwitchedByIgnition" SG_ 1600 MO_KL15_Abschaltempfehlung 0;
BA_ "GenSigSendType" SG_ 1600 MO_Kuehlmittel_Temp 0;
BA_ "GenSigStartValue" SG_ 1600 MO_Kuehlmittel_Temp 254;
BA_ "GenSigSwitchedByIgnition" SG_ 1600 MO_Kuehlmittel_Temp 0;
BA_ "Fehlerwert" SG_ 1600 MO_Kuehlmittel_Temp 255;
BA_ "GenSigSendType" SG_ 1600 MO_Mom_Traegheit_02 0;
BA_ "GenSigSwitchedByIgnition" SG_ 1600 MO_Mom_Traegheit_02 0;
BA_ "GenSigSendType" SG_ 1600 MO_Nachlaufzeit_Heizungspumpe 0;
BA_ "GenSigSwitchedByIgnition" SG_ 1600 MO_Nachlaufzeit_Heizungspumpe 0;
BA_ "GenSigSendType" SG_ 1600 MO_Oel_Temp 0;
BA_ "GenSigStartValue" SG_ 1600 MO_Oel_Temp 254;
BA_ "GenSigSwitchedByIgnition" SG_ 1600 MO_Oel_Temp 0;
BA_ "Fehlerwert" SG_ 1600 MO_Oel_Temp 255;
BA_ "GenSigSendType" SG_ 1600 MO_QBit_Ansaugluft_Temp 0;
BA_ "GenSigStartValue" SG_ 1600 MO_QBit_Ansaugluft_Temp 1;
BA_ "GenSigSwitchedByIgnition" SG_ 1600 MO_QBit_Ansaugluft_Temp 0;
BA_ "GenSigSendType" SG_ 1600 MO_QBit_Hoeheninfo 0;
BA_ "GenSigStartValue" SG_ 1600 MO_QBit_Hoeheninfo 1;
BA_ "GenSigSwitchedByIgnition" SG_ 1600 MO_QBit_Hoeheninfo 0;
BA_ "GenSigSendType" SG_ 1600 MO_QBit_Kuehlmittel_Temp 0;
BA_ "GenSigStartValue" SG_ 1600 MO_QBit_Kuehlmittel_Temp 1;
BA_ "GenSigSwitchedByIgnition" SG_ 1600 MO_QBit_Kuehlmittel_Temp 0;
BA_ "GenSigSendType" SG_ 1600 MO_QBit_Oel_Temp 0;
BA_ "GenSigStartValue" SG_ 1600 MO_QBit_Oel_Temp 1;
BA_ "GenSigSwitchedByIgnition" SG_ 1600 MO_QBit_Oel_Temp 0;
BA_ "GenSigSendType" SG_ 1600 MO_SpannungsAnf 0;
BA_ "GenSigSwitchedByIgnition" SG_ 1600 MO_SpannungsAnf 0;
BA_ "GenSigSendType" SG_ 1600 MO_Versionsinfo_02 0;
BA_ "GenSigSwitchedByIgnition" SG_ 1600 MO_Versionsinfo_02 0;
BA_ "GenSigSendType" SG_ 167 MO_erste_Ungenauschwelle 0;
BA_ "GenSigSwitchedByIgnition" SG_ 167 MO_erste_Ungenauschwelle 0;
BA_ "GenSigSendType" SG_ 167 MO_Mom_Ist_Summe 0;
BA_ "GenSigStartValue" SG_ 167 MO_Mom_Ist_Summe 1022;
BA_ "GenSigSwitchedByIgnition" SG_ 167 MO_Mom_Ist_Summe 0;
BA_ "GenSigSendType" SG_ 167 MO_Mom_Schub 0;
BA_ "GenSigStartValue" SG_ 167 MO_Mom_Schub 510;
BA_ "GenSigSwitchedByIgnition" SG_ 167 MO_Mom_Schub 0;
BA_ "GenSigSendType" SG_ 167 MO_Mom_Soll_gefiltert 0;
BA_ "GenSigStartValue" SG_ 167 MO_Mom_Soll_gefiltert 1022;
BA_ "GenSigSwitchedByIgnition" SG_ 167 MO_Mom_Soll_gefiltert 0;
BA_ "GenSigSendType" SG_ 167 MO_Mom_Soll_Roh 0;
BA_ "GenSigStartValue" SG_ 167 MO_Mom_Soll_Roh 1022;
BA_ "GenSigSwitchedByIgnition" SG_ 167 MO_Mom_Soll_Roh 0;
BA_ "GenSigSendType" SG_ 167 MO_Mom_Traegheit_Summe 0;
BA_ "GenSigStartValue" SG_ 167 MO_Mom_Traegheit_Summe 1022;
BA_ "GenSigSwitchedByIgnition" SG_ 167 MO_Mom_Traegheit_Summe 0;
BA_ "GenSigSendType" SG_ 167 MO_QBit_Motormomente 0;
BA_ "GenSigStartValue" SG_ 167 MO_QBit_Motormomente 1;
BA_ "GenSigSwitchedByIgnition" SG_ 167 MO_QBit_Motormomente 0;
BA_ "GenSigSendType" SG_ 167 MO_Status_Normalbetrieb_01 0;
BA_ "GenSigSwitchedByIgnition" SG_ 167 MO_Status_Normalbetrieb_01 0;
BA_ "GenSigSendType" SG_ 167 Motor_11_BZ 0;
BA_ "GenSigFuncType" SG_ 167 Motor_11_BZ 1;
BA_ "GenSigSwitchedByIgnition" SG_ 167 Motor_11_BZ 0;
BA_ "GenSigSendType" SG_ 167 Motor_11_CRC 0;
BA_ "GenSigFuncType" SG_ 167 Motor_11_CRC 2;
BA_ "GenSigSwitchedByIgnition" SG_ 167 Motor_11_CRC 0;
BA_ "GenSigSendType" SG_ 168 MO_Drehzahl_01 0;
BA_ "GenSigSwitchedByIgnition" SG_ 168 MO_Drehzahl_01 0;
BA_ "GenSigSendType" SG_ 168 MO_Mom_Begr_dyn 0;
BA_ "GenSigStartValue" SG_ 168 MO_Mom_Begr_dyn 1022;
BA_ "GenSigSwitchedByIgnition" SG_ 168 MO_Mom_Begr_dyn 0;
BA_ "GenSigSendType" SG_ 168 MO_Mom_Begr_stat 0;
BA_ "GenSigStartValue" SG_ 168 MO_Mom_Begr_stat 510;
BA_ "GenSigSwitchedByIgnition" SG_ 168 MO_Mom_Begr_stat 0;
BA_ "GenSigSendType" SG_ 168 MO_Mom_neg_verfuegbar 0;
BA_ "GenSigStartValue" SG_ 168 MO_Mom_neg_verfuegbar 510;
BA_ "GenSigSwitchedByIgnition" SG_ 168 MO_Mom_neg_verfuegbar 0;
BA_ "Fehlerwert" SG_ 168 MO_Mom_neg_verfuegbar 511;
BA_ "GenSigSendType" SG_ 168 MO_Momentenintegral_02 0;
BA_ "GenSigSwitchedByIgnition" SG_ 168 MO_Momentenintegral_02 0;
BA_ "GenSigSendType" SG_ 168 MO_QBit_Drehzahl_01 0;
BA_ "GenSigStartValue" SG_ 168 MO_QBit_Drehzahl_01 1;
BA_ "GenSigSwitchedByIgnition" SG_ 168 MO_QBit_Drehzahl_01 0;
BA_ "GenSigSendType" SG_ 168 Motor_12_BZ 0;
BA_ "GenSigFuncType" SG_ 168 Motor_12_BZ 1;
BA_ "GenSigSwitchedByIgnition" SG_ 168 Motor_12_BZ 0;
BA_ "GenSigSendType" SG_ 168 Motor_12_CRC 0;
BA_ "GenSigFuncType" SG_ 168 Motor_12_CRC 2;
BA_ "GenSigSwitchedByIgnition" SG_ 168 Motor_12_CRC 0;
BA_ "GenSigSendType" SG_ 958 MO_Aussp_Anlass 3;
BA_ "GenSigSwitchedByIgnition" SG_ 958 MO_Aussp_Anlass 0;
BA_ "GenSigSendType" SG_ 958 MO_BKV_Unterdruckwarnung 0;
BA_ "GenSigSwitchedByIgnition" SG_ 958 MO_BKV_Unterdruckwarnung 0;
BA_ "GenSigSendType" SG_ 958 MO_BLS 3;
BA_ "GenSigSwitchedByIgnition" SG_ 958 MO_BLS 0;
BA_ "GenSigSendType" SG_ 958 MO_BMS_NV_Anf_stuetzen 3;
BA_ "GenSigSwitchedByIgnition" SG_ 958 MO_BMS_NV_Anf_stuetzen 0;
BA_ "GenSigSendType" SG_ 958 MO_EKlKomLeiRed 0;
BA_ "GenSigSwitchedByIgnition" SG_ 958 MO_EKlKomLeiRed 0;
BA_ "GenSigSendType" SG_ 958 MO_Ext_E_Fahrt_aktiv 3;
BA_ "NWM-WakeupAllowed" SG_ 958 MO_Ext_E_Fahrt_aktiv 1;
BA_ "GenSigSwitchedByIgnition" SG_ 958 MO_Ext_E_Fahrt_aktiv 0;
BA_ "GenSigSendType" SG_ 958 MO_Fahrer_bremst 3;
BA_ "GenSigSwitchedByIgnition" SG_ 958 MO_Fahrer_bremst 0;
BA_ "GenSigSendType" SG_ 958 MO_FMAus_aktiv 3;
BA_ "GenSigSwitchedByIgnition" SG_ 958 MO_FMAus_aktiv 0;
BA_ "GenSigSendType" SG_ 958 MO_FMAus_Startvariante 3;
BA_ "GenSigSwitchedByIgnition" SG_ 958 MO_FMAus_Startvariante 0;
BA_ "GenSigSendType" SG_ 958 MO_Freig_Anlass 3;
BA_ "GenSigSwitchedByIgnition" SG_ 958 MO_Freig_Anlass 0;
BA_ "GenSigSendType" SG_ 958 MO_Freig_Reku 0;
BA_ "GenSigSwitchedByIgnition" SG_ 958 MO_Freig_Reku 0;
BA_ "GenSigSendType" SG_ 958 MO_Freigabe_Segeln 0;
BA_ "GenSigSwitchedByIgnition" SG_ 958 MO_Freigabe_Segeln 0;
BA_ "GenSigSendType" SG_ 958 MO_Gangposition 3;
BA_ "GenSigStartValue" SG_ 958 MO_Gangposition 14;
BA_ "GenSigSwitchedByIgnition" SG_ 958 MO_Gangposition 0;
BA_ "Fehlerwert" SG_ 958 MO_Gangposition 15;
BA_ "GenSigSendType" SG_ 958 MO_Handshake_STH 0;
BA_ "GenSigSwitchedByIgnition" SG_ 958 MO_Handshake_STH 0;
BA_ "GenSigSendType" SG_ 958 MO_HYB_Fahrbereitschaft 0;
BA_ "GenSigSwitchedByIgnition" SG_ 958 MO_HYB_Fahrbereitschaft 0;
BA_ "GenSigSendType" SG_ 958 MO_HYB_VM_aktiv 3;
BA_ "GenSigSwitchedByIgnition" SG_ 958 MO_HYB_VM_aktiv 0;
BA_ "GenSigSendType" SG_ 958 MO_Interlock 3;
BA_ "GenSigSwitchedByIgnition" SG_ 958 MO_Interlock 0;
BA_ "GenSigSendType" SG_ 958 MO_Kickdown 3;
BA_ "GenSigSwitchedByIgnition" SG_ 958 MO_Kickdown 0;
BA_ "GenSigSendType" SG_ 958 MO_Kl_50 3;
BA_ "GenSigSwitchedByIgnition" SG_ 958 MO_Kl_50 0;
BA_ "GenSigSendType" SG_ 958 MO_Kl_75 3;
BA_ "GenSigSwitchedByIgnition" SG_ 958 MO_Kl_75 0;
BA_ "GenSigSendType" SG_ 958 MO_Klima_Eingr 0;
BA_ "GenSigSwitchedByIgnition" SG_ 958 MO_Klima_Eingr 0;
BA_ "GenSigSendType" SG_ 958 MO_KomFehler_ESP 3;
BA_ "GenSigSwitchedByIgnition" SG_ 958 MO_KomFehler_ESP 0;
BA_ "Fehlerwert" SG_ 958 MO_KomFehler_ESP 1;
BA_ "GenSigSendType" SG_ 958 MO_Konsistenz_Bremsped 3;
BA_ "GenSigSwitchedByIgnition" SG_ 958 MO_Konsistenz_Bremsped 0;
BA_ "GenSigSendType" SG_ 958 MO_Kuppl_schalter 3;
BA_ "GenSigSwitchedByIgnition" SG_ 958 MO_Kuppl_schalter 0;
BA_ "GenSigSendType" SG_ 958 MO_Motor_laeuft 3;
BA_ "GenSigSwitchedByIgnition" SG_ 958 MO_Motor_laeuft 0;
BA_ "GenSigSendType" SG_ 958 MO_PTC_Status 0;
BA_ "GenSigSwitchedByIgnition" SG_ 958 MO_PTC_Status 0;
BA_ "GenSigSendType" SG_ 958 MO_QBit_Fahrer_bremst 3;
BA_ "GenSigStartValue" SG_ 958 MO_QBit_Fahrer_bremst 1;
BA_ "GenSigSwitchedByIgnition" SG_ 958 MO_QBit_Fahrer_bremst 0;
BA_ "GenSigSendType" SG_ 958 MO_QBit_Gangposition 3;
BA_ "GenSigStartValue" SG_ 958 MO_QBit_Gangposition 1;
BA_ "GenSigSwitchedByIgnition" SG_ 958 MO_QBit_Gangposition 0;
BA_ "GenSigSendType" SG_ 958 MO_QBit_KL_75 3;
BA_ "GenSigStartValue" SG_ 958 MO_QBit_KL_75 1;
BA_ "GenSigSwitchedByIgnition" SG_ 958 MO_QBit_KL_75 0;
BA_ "GenSigSendType" SG_ 958 MO_Remotestart_Betrieb 3;
BA_ "GenSigSwitchedByIgnition" SG_ 958 MO_Remotestart_Betrieb 0;
BA_ "GenSigSendType" SG_ 958 MO_Remotestart_moeglich 0;
BA_ "GenSigSwitchedByIgnition" SG_ 958 MO_Remotestart_moeglich 0;
BA_ "GenSigSendType" SG_ 958 MO_Signalquelle_Gangposition 0;
BA_ "GenSigSwitchedByIgnition" SG_ 958 MO_Signalquelle_Gangposition 0;
BA_ "GenSigSendType" SG_ 958 MO_StartStopp_Fahrerwunsch 0;
BA_ "GenSigSwitchedByIgnition" SG_ 958 MO_StartStopp_Fahrerwunsch 0;
BA_ "GenSigSendType" SG_ 958 MO_StartStopp_Motorstopp 3;
BA_ "GenSigSwitchedByIgnition" SG_ 958 MO_StartStopp_Motorstopp 0;
BA_ "GenSigSendType" SG_ 958 MO_StartStopp_Status 3;
BA_ "GenSigSwitchedByIgnition" SG_ 958 MO_StartStopp_Status 0;
BA_ "GenSigSendType" SG_ 958 MO_StartStopp_Wiederstart 3;
BA_ "GenSigSwitchedByIgnition" SG_ 958 MO_StartStopp_Wiederstart 0;
BA_ "GenSigSendType" SG_ 958 MO_StartVorauss_erfuellt 3;
BA_ "GenSigStartValue" SG_ 958 MO_StartVorauss_erfuellt 1;
BA_ "GenSigSwitchedByIgnition" SG_ 958 MO_StartVorauss_erfuellt 0;
BA_ "GenSigSendType" SG_ 958 MO_Zylinderabschaltung 3;
BA_ "GenSigSwitchedByIgnition" SG_ 958 MO_Zylinderabschaltung 0;
BA_ "GenSigSendType" SG_ 958 Motor_14_BZ 0;
BA_ "GenSigFuncType" SG_ 958 Motor_14_BZ 1;
BA_ "GenSigSwitchedByIgnition" SG_ 958 Motor_14_BZ 0;
BA_ "GenSigSendType" SG_ 958 Motor_14_CRC 0;
BA_ "GenSigFuncType" SG_ 958 Motor_14_CRC 2;
BA_ "GenSigSwitchedByIgnition" SG_ 958 Motor_14_CRC 0;
BA_ "GenSigSendType" SG_ 1648 MO1_Freigabe_Info_WFS 3;
BA_ "GenSigSwitchedByIgnition" SG_ 1648 MO1_Freigabe_Info_WFS 0;
BA_ "GenSigSendType" SG_ 1648 MO1_Freigabe_Verfallsinfo_WFS 3;
BA_ "GenSigSwitchedByIgnition" SG_ 1648 MO1_Freigabe_Verfallsinfo_WFS 0;
BA_ "GenSigSendType" SG_ 1648 MO1_Sperr_Info_WFS 3;
BA_ "GenSigSwitchedByIgnition" SG_ 1648 MO1_Sperr_Info_WFS 0;
BA_ "GenSigSendType" SG_ 1648 MO_Abstellzeit 0;
BA_ "GenSigStartValue" SG_ 1648 MO_Abstellzeit 254;
BA_ "GenSigSwitchedByIgnition" SG_ 1648 MO_Abstellzeit 0;
BA_ "GenSigSendType" SG_ 1648 MO_Abstellzeit_Status 0;
BA_ "GenSigSwitchedByIgnition" SG_ 1648 MO_Abstellzeit_Status 0;
BA_ "GenSigSendType" SG_ 1648 MO_ANC_Kennfeld_Anf 3;
BA_ "GenSigSwitchedByIgnition" SG_ 1648 MO_ANC_Kennfeld_Anf 0;
BA_ "GenSigSendType" SG_ 1648 MO_Anzahl_Abgesch_Zyl 3;
BA_ "GenSigSwitchedByIgnition" SG_ 1648 MO_Anzahl_Abgesch_Zyl 0;
BA_ "GenSigSendType" SG_ 1648 MO_Bremslicht_Reku 3;
BA_ "GenSigSwitchedByIgnition" SG_ 1648 MO_Bremslicht_Reku 0;
BA_ "GenSigSendType" SG_ 1648 MO_Drehzahl_Warnung 0;
BA_ "GenSigSwitchedByIgnition" SG_ 1648 MO_Drehzahl_Warnung 0;
BA_ "GenSigSendType" SG_ 1648 MO_EPCL 0;
BA_ "GenSigSwitchedByIgnition" SG_ 1648 MO_EPCL 0;
BA_ "GenSigSendType" SG_ 1648 MO_Ethanol_BS_Texte 0;
BA_ "GenSigSwitchedByIgnition" SG_ 1648 MO_Ethanol_BS_Texte 0;
BA_ "GenSigSendType" SG_ 1648 MO_Fahrzeugtyp 0;
BA_ "GenSigFuncType" SG_ 1648 MO_Fahrzeugtyp 8;
BA_ "GenSigSwitchedByIgnition" SG_ 1648 MO_Fahrzeugtyp 0;
BA_ "GenSigSendType" SG_ 1648 MO_Fehler_Zylabsch 0;
BA_ "GenSigSwitchedByIgnition" SG_ 1648 MO_Fehler_Zylabsch 0;
BA_ "GenSigSendType" SG_ 1648 MO_Hybrid_StartStopp_LED 3;
BA_ "GenSigSwitchedByIgnition" SG_ 1648 MO_Hybrid_StartStopp_LED 0;
BA_ "GenSigSendType" SG_ 1648 MO_max_Ladedruck 0;
BA_ "GenSigFuncType" SG_ 1648 MO_max_Ladedruck 8;
BA_ "GenSigSwitchedByIgnition" SG_ 1648 MO_max_Ladedruck 0;
BA_ "GenSigSendType" SG_ 1648 MO_NMAX_Schaltanzeige 3;
BA_ "GenSigSwitchedByIgnition" SG_ 1648 MO_NMAX_Schaltanzeige 0;
BA_ "GenSigSendType" SG_ 1648 MO_obere_Drehzahlgrenze 0;
BA_ "GenSigSwitchedByIgnition" SG_ 1648 MO_obere_Drehzahlgrenze 0;
BA_ "GenSigSendType" SG_ 1648 MO_StartStopp_PopUp 3;
BA_ "GenSigSwitchedByIgnition" SG_ 1648 MO_StartStopp_PopUp 0;
BA_ "GenSigSendType" SG_ 1648 MO_Zylabsch_Texte 0;
BA_ "GenSigSwitchedByIgnition" SG_ 1648 MO_Zylabsch_Texte 0;
BA_ "GenSigSendType" SG_ 1648 MO_Zylabsch_Texte_02 3;
BA_ "GenSigSwitchedByIgnition" SG_ 1648 MO_Zylabsch_Texte_02 0;
BA_ "GenSigSendType" SG_ 1010 MO_SCR_Dosierpumpe_Soll 0;
BA_ "GenSigSwitchedByIgnition" SG_ 1010 MO_SCR_Dosierpumpe_Soll 0;
BA_ "GenSigSendType" SG_ 1010 MO_SCR_Dosierpumpe_Wartezeit 0;
BA_ "GenSigStartValue" SG_ 1010 MO_SCR_Dosierpumpe_Wartezeit 126;
BA_ "GenSigSwitchedByIgnition" SG_ 1010 MO_SCR_Dosierpumpe_Wartezeit 0;
BA_ "Fehlerwert" SG_ 1010 MO_SCR_Dosierpumpe_Wartezeit 127;
BA_ "GenSigSendType" SG_ 1010 MO_SCR_Dosierpumpe_Zustand 0;
BA_ "GenSigSwitchedByIgnition" SG_ 1010 MO_SCR_Dosierpumpe_Zustand 0;
BA_ "GenSigSendType" SG_ 1010 MO_SCR_Heizkreis_3 0;
BA_ "GenSigSwitchedByIgnition" SG_ 1010 MO_SCR_Heizkreis_3 0;
BA_ "GenSigSendType" SG_ 1010 MO_SCR_Heizkreis_3_Leistung 0;
BA_ "GenSigStartValue" SG_ 1010 MO_SCR_Heizkreis_3_Leistung 254;
BA_ "GenSigSwitchedByIgnition" SG_ 1010 MO_SCR_Heizkreis_3_Leistung 0;
BA_ "GenSigSendType" SG_ 1010 MO_SCR_Leitungsheizung 0;
BA_ "GenSigSwitchedByIgnition" SG_ 1010 MO_SCR_Leitungsheizung 0;
BA_ "GenSigSendType" SG_ 1010 MO_SCR_Tankheizkreis_Leistung 0;
BA_ "GenSigStartValue" SG_ 1010 MO_SCR_Tankheizkreis_Leistung 254;
BA_ "GenSigSwitchedByIgnition" SG_ 1010 MO_SCR_Tankheizkreis_Leistung 0;
BA_ "GenSigSendType" SG_ 1010 MO_SCR_Tankheizung 0;
BA_ "GenSigSwitchedByIgnition" SG_ 1010 MO_SCR_Tankheizung 0;
BA_ "GenSigSendType" SG_ 1010 MO_SCR_Transferpumpe 0;
BA_ "GenSigSwitchedByIgnition" SG_ 1010 MO_SCR_Transferpumpe 0;
BA_ "GenSigSendType" SG_ 1010 Motor_19_BZ 0;
BA_ "GenSigFuncType" SG_ 1010 Motor_19_BZ 1;
BA_ "GenSigSwitchedByIgnition" SG_ 1010 Motor_19_BZ 0;
BA_REL_ "GenSigTimeoutTime" BU_SG_REL_ AEM SG_ 1719 KBI_Aussen_Temp_gef 5000;
BA_REL_ "GenSigTimeoutTime" BU_SG_REL_ AEM SG_ 1600 MO_Oel_Temp 3200;
BA_REL_ "GenSigTimeoutTime" BU_SG_REL_ AEM SG_ 1600 MO_Kuehlmittel_Temp 3200;
BA_REL_ "GenSigTimeoutTime" BU_SG_REL_ AEM SG_ 167 MO_Mom_Ist_Summe 500;
BA_REL_ "GenSigTimeoutTime" BU_SG_REL_ AEM SG_ 167 MO_QBit_Motormomente 500;
BA_REL_ "GenSigTimeoutTime" BU_SG_REL_ AEM SG_ 168 MO_QBit_Drehzahl_01 500;
BA_REL_ "GenSigTimeoutTime" BU_SG_REL_ AEM SG_ 168 MO_Drehzahl_01 500;
BA_REL_ "GenSigTimeoutTime" BU_SG_REL_ AEM SG_ 958 MO_StartStopp_Status 1000;
BA_REL_ "GenSigTimeoutTime" BU_SG_REL_ AEM SG_ 958 MO_StartStopp_Wiederstart 1000;
BA_REL_ "GenSigTimeoutTime" BU_SG_REL_ AEM SG_ 958 MO_StartStopp_Motorstopp 1000;
BA_REL_ "GenSigTimeoutTime" BU_SG_REL_ AEM SG_ 958 MO_Kl_75 1000;
BA_REL_ "GenSigTimeoutTime" BU_SG_REL_ AEM SG_ 958 MO_Kl_50 1000;
BA_REL_ "GenSigTimeoutTime" BU_SG_REL_ AEM SG_ 958 MO_StartStopp_Fahrerwunsch 1000;
BA_REL_ "GenSigTimeoutTime" BU_SG_REL_ AEM SG_ 958 MO_Motor_laeuft 1000;
BA_REL_ "GenSigTimeoutTime" BU_SG_REL_ AEM SG_ 958 MO_Zylinderabschaltung 1000;
BA_REL_ "GenSigTimeoutTime" BU_SG_REL_ E_Sound SG_ 167 MO_Mom_Ist_Summe 500;
BA_REL_ "GenSigTimeoutTime" BU_SG_REL_ E_Sound SG_ 168 MO_Drehzahl_01 500;
BA_REL_ "GenSigTimeoutTime" BU_SG_REL_ E_Sound SG_ 958 MO_Gangposition 1000;
BA_REL_ "GenSigTimeoutTime" BU_SG_REL_ E_Sound SG_ 958 MO_HYB_Fahrbereitschaft 1000;
BA_REL_ "GenSigTimeoutTime" BU_SG_REL_ E_Sound SG_ 958 MO_HYB_VM_aktiv 1000;
BA_REL_ "GenSigTimeoutTime" BU_SG_REL_ FLA SG_ 1624 LV_Abblendlicht_Anzeige 5000;
BA_REL_ "GenSigTimeoutTime" BU_SG_REL_ FLA SG_ 1624 LV_Fernlicht_Anzeige 5000;
BA_REL_ "GenSigTimeoutTime" BU_SG_REL_ FLA SG_ 1624 LV_Nebellicht_Anzeige 5000;
BA_REL_ "GenSigTimeoutTime" BU_SG_REL_ FLA SG_ 958 MO_StartStopp_Wiederstart 1000;
BA_REL_ "GenSigTimeoutTime" BU_SG_REL_ FLA SG_ 958 MO_Kl_75 1000;
BA_REL_ "GenSigTimeoutTime" BU_SG_REL_ FLA SG_ 958 MO_Gangposition 1000;
BA_REL_ "GenSigTimeoutTime" BU_SG_REL_ Gateway SG_ 2549088295 Nightvision_Nachlauftyp 5000;
BA_REL_ "GenSigTimeoutTime" BU_SG_REL_ Gateway SG_ 2549088295 Nightvision_SNI 5000;
BA_REL_ "GenSigTimeoutTime" BU_SG_REL_ Gateway SG_ 2549088295 Nightvision_KD_Fehler 2500;
BA_REL_ "GenSigTimeoutTime" BU_SG_REL_ Gateway SG_ 2549088267 RDK_Nachlauftyp 5000;
BA_REL_ "GenSigTimeoutTime" BU_SG_REL_ Gateway SG_ 2549088267 RDK_SNI 5000;
BA_REL_ "GenSigTimeoutTime" BU_SG_REL_ Gateway SG_ 2549088267 KN_RDK_BusKnockOutTimer 5000;
BA_REL_ "GenSigTimeoutTime" BU_SG_REL_ Gateway SG_ 2549088267 NM_RDK_Lokalaktiv 5000;
BA_REL_ "GenSigTimeoutTime" BU_SG_REL_ Gateway SG_ 2549088267 RDK_KD_Fehler 2500;
BA_REL_ "GenSigTimeoutTime" BU_SG_REL_ Gateway SG_ 2549088361 Rearview_Nachlauftyp 5000;
BA_REL_ "GenSigTimeoutTime" BU_SG_REL_ Gateway SG_ 2549088361 Rearview_SNI 5000;
BA_REL_ "GenSigTimeoutTime" BU_SG_REL_ Gateway SG_ 2549088361 KN_Rearview_BusKnockOutTimer 5000;
BA_REL_ "GenSigTimeoutTime" BU_SG_REL_ Gateway SG_ 2549088361 Rearview_Lokalaktiv 5000;
BA_REL_ "GenSigTimeoutTime" BU_SG_REL_ Gateway SG_ 2549088361 RV_KD_Fehler 2500;
BA_REL_ "GenSigTimeoutTime" BU_SG_REL_ Gateway SG_ 2549088284 SAK_Nachlauftyp 5000;
BA_REL_ "GenSigTimeoutTime" BU_SG_REL_ Gateway SG_ 2549088284 SAK_SNI 5000;
BA_REL_ "GenSigTimeoutTime" BU_SG_REL_ Gateway SG_ 2549088284 SAK_KD_Fehler 2500;
BA_REL_ "GenSigTimeoutTime" BU_SG_REL_ Gateway SG_ 2549088298 SCR_Nachlauftyp 5000;
BA_REL_ "GenSigTimeoutTime" BU_SG_REL_ Gateway SG_ 2549088298 SCR_SNI 5000;
BA_REL_ "GenSigTimeoutTime" BU_SG_REL_ Gateway SG_ 2549088298 KN_SCR_BusKnockOutTimer 5000;
BA_REL_ "GenSigTimeoutTime" BU_SG_REL_ Gateway SG_ 2549088298 NMH_SCR_Lokalaktiv 5000;
BA_REL_ "GenSigTimeoutTime" BU_SG_REL_ Gateway SG_ 2549088298 SCR_KD_Fehler 2500;
BA_REL_ "GenSigTimeoutTime" BU_SG_REL_ Gateway SG_ 2549088362 STH_Nachlauftyp 5000;
BA_REL_ "GenSigTimeoutTime" BU_SG_REL_ Gateway SG_ 2549088362 STH_SNI 5000;
BA_REL_ "GenSigTimeoutTime" BU_SG_REL_ Gateway SG_ 2549088362 KN_STH_BusKnockOutTimer 5000;
BA_REL_ "GenSigTimeoutTime" BU_SG_REL_ Gateway SG_ 2549088362 NMH_STH_Lokalaktiv 5000;
BA_REL_ "GenSigTimeoutTime" BU_SG_REL_ Gateway SG_ 2549088362 NMH_STH_Subsystemaktiv 5000;
BA_REL_ "GenSigTimeoutTime" BU_SG_REL_ Gateway SG_ 2549088362 STH_KD_Fehler 2500;
BA_REL_ "GenSigTimeoutTime" BU_SG_REL_ Gateway SG_ 2549088394 SWA_2_Nachlauftyp 5000;
BA_REL_ "GenSigTimeoutTime" BU_SG_REL_ Gateway SG_ 2549088394 SWA_2_SNI 5000;
BA_REL_ "GenSigTimeoutTime" BU_SG_REL_ Gateway SG_ 2549088394 KN_SWA_Slave_BusKnockOutTimer 5000;
BA_REL_ "GenSigTimeoutTime" BU_SG_REL_ Gateway SG_ 2549088394 SWA_2_Lokalaktiv 5000;
BA_REL_ "GenSigTimeoutTime" BU_SG_REL_ Gateway SG_ 2549088394 SWA_2_KD_Fehler 2500;
BA_REL_ "GenSigTimeoutTime" BU_SG_REL_ Gateway SG_ 2549088334 SWA_Nachlauftyp 5000;
BA_REL_ "GenSigTimeoutTime" BU_SG_REL_ Gateway SG_ 2549088334 SWA_SNI 5000;
BA_REL_ "GenSigTimeoutTime" BU_SG_REL_ Gateway SG_ 2549088334 KN_SWA_BusKnockOutTimer 5000;
BA_REL_ "GenSigTimeoutTime" BU_SG_REL_ Gateway SG_ 2549088334 SWA_Lokalaktiv 5000;
BA_REL_ "GenSigTimeoutTime" BU_SG_REL_ Gateway SG_ 2549088334 SWA_KD_Fehler 2500;
BA_REL_ "GenSigTimeoutTime" BU_SG_REL_ Gateway_PAG SG_ 2549088295 Nightvision_Nachlauftyp 5000;
BA_REL_ "GenSigTimeoutTime" BU_SG_REL_ Gateway_PAG SG_ 2549088295 Nightvision_SNI 5000;
BA_REL_ "GenSigTimeoutTime" BU_SG_REL_ Gateway_PAG SG_ 2549088295 Nightvision_KD_Fehler 2500;
BA_REL_ "GenSigTimeoutTime" BU_SG_REL_ Gateway_PAG SG_ 2549088267 RDK_Nachlauftyp 5000;
BA_REL_ "GenSigTimeoutTime" BU_SG_REL_ Gateway_PAG SG_ 2549088267 RDK_SNI 5000;
BA_REL_ "GenSigTimeoutTime" BU_SG_REL_ Gateway_PAG SG_ 2549088267 KN_RDK_BusKnockOutTimer 5000;
BA_REL_ "GenSigTimeoutTime" BU_SG_REL_ Gateway_PAG SG_ 2549088267 NM_RDK_Lokalaktiv 5000;
BA_REL_ "GenSigTimeoutTime" BU_SG_REL_ Gateway_PAG SG_ 2549088267 RDK_KD_Fehler 2500;
BA_REL_ "GenSigTimeoutTime" BU_SG_REL_ Gateway_PAG SG_ 2549088361 Rearview_Nachlauftyp 5000;
BA_REL_ "GenSigTimeoutTime" BU_SG_REL_ Gateway_PAG SG_ 2549088361 Rearview_SNI 5000;
BA_REL_ "GenSigTimeoutTime" BU_SG_REL_ Gateway_PAG SG_ 2549088361 KN_Rearview_BusKnockOutTimer 5000;
BA_REL_ "GenSigTimeoutTime" BU_SG_REL_ Gateway_PAG SG_ 2549088361 Rearview_Lokalaktiv 5000;
BA_REL_ "GenSigTimeoutTime" BU_SG_REL_ Gateway_PAG SG_ 2549088361 RV_KD_Fehler 2500;
BA_REL_ "GenSigTimeoutTime" BU_SG_REL_ Gateway_PAG SG_ 2549088284 SAK_Nachlauftyp 5000;
BA_REL_ "GenSigTimeoutTime" BU_SG_REL_ Gateway_PAG SG_ 2549088284 SAK_SNI 5000;
BA_REL_ "GenSigTimeoutTime" BU_SG_REL_ Gateway_PAG SG_ 2549088284 SAK_KD_Fehler 2500;
BA_REL_ "GenSigTimeoutTime" BU_SG_REL_ Gateway_PAG SG_ 2549088298 SCR_Nachlauftyp 5000;
BA_REL_ "GenSigTimeoutTime" BU_SG_REL_ Gateway_PAG SG_ 2549088298 SCR_SNI 5000;
BA_REL_ "GenSigTimeoutTime" BU_SG_REL_ Gateway_PAG SG_ 2549088298 KN_SCR_BusKnockOutTimer 5000;
BA_REL_ "GenSigTimeoutTime" BU_SG_REL_ Gateway_PAG SG_ 2549088298 NMH_SCR_Lokalaktiv 5000;
BA_REL_ "GenSigTimeoutTime" BU_SG_REL_ Gateway_PAG SG_ 2549088298 SCR_KD_Fehler 2500;
BA_REL_ "GenSigTimeoutTime" BU_SG_REL_ Gateway_PAG SG_ 2549088362 STH_Nachlauftyp 5000;
BA_REL_ "GenSigTimeoutTime" BU_SG_REL_ Gateway_PAG SG_ 2549088362 STH_SNI 5000;
BA_REL_ "GenSigTimeoutTime" BU_SG_REL_ Gateway_PAG SG_ 2549088362 KN_STH_BusKnockOutTimer 5000;
BA_REL_ "GenSigTimeoutTime" BU_SG_REL_ Gateway_PAG SG_ 2549088362 NMH_STH_Lokalaktiv 5000;
BA_REL_ "GenSigTimeoutTime" BU_SG_REL_ Gateway_PAG SG_ 2549088362 NMH_STH_Subsystemaktiv 5000;
BA_REL_ "GenSigTimeoutTime" BU_SG_REL_ Gateway_PAG SG_ 2549088362 STH_KD_Fehler 2500;
BA_REL_ "GenSigTimeoutTime" BU_SG_REL_ Gateway_PAG SG_ 2549088394 SWA_2_Nachlauftyp 5000;
BA_REL_ "GenSigTimeoutTime" BU_SG_REL_ Gateway_PAG SG_ 2549088394 SWA_2_SNI 5000;
BA_REL_ "GenSigTimeoutTime" BU_SG_REL_ Gateway_PAG SG_ 2549088394 KN_SWA_Slave_BusKnockOutTimer 5000;
BA_REL_ "GenSigTimeoutTime" BU_SG_REL_ Gateway_PAG SG_ 2549088394 SWA_2_Lokalaktiv 5000;
BA_REL_ "GenSigTimeoutTime" BU_SG_REL_ Gateway_PAG SG_ 2549088394 SWA_2_KD_Fehler 2500;
BA_REL_ "GenSigTimeoutTime" BU_SG_REL_ Gateway_PAG SG_ 2549088334 SWA_Nachlauftyp 5000;
BA_REL_ "GenSigTimeoutTime" BU_SG_REL_ Gateway_PAG SG_ 2549088334 SWA_SNI 5000;
BA_REL_ "GenSigTimeoutTime" BU_SG_REL_ Gateway_PAG SG_ 2549088334 KN_SWA_BusKnockOutTimer 5000;
BA_REL_ "GenSigTimeoutTime" BU_SG_REL_ Gateway_PAG SG_ 2549088334 SWA_Lokalaktiv 5000;
BA_REL_ "GenSigTimeoutTime" BU_SG_REL_ Gateway_PAG SG_ 2549088334 SWA_KD_Fehler 2500;
BA_REL_ "GenSigTimeoutTime" BU_SG_REL_ ISE SG_ 167 MO_Mom_Ist_Summe 500;
BA_REL_ "GenSigTimeoutTime" BU_SG_REL_ ISE SG_ 168 MO_Drehzahl_01 500;
BA_REL_ "GenSigTimeoutTime" BU_SG_REL_ ISE SG_ 958 MO_Gangposition 1000;
BA_REL_ "GenSigTimeoutTime" BU_SG_REL_ ISE SG_ 958 MO_HYB_Fahrbereitschaft 1000;
BA_REL_ "GenSigTimeoutTime" BU_SG_REL_ ISE SG_ 958 MO_HYB_VM_aktiv 1000;
BA_REL_ "GenSigTimeoutTime" BU_SG_REL_ NightVision SG_ 779 KBI_NV_in_Anzeige 500;
BA_REL_ "GenSigTimeoutTime" BU_SG_REL_ NightVision SG_ 779 KBI_Anzeigefehler_NV 500;
BA_REL_ "GenSigTimeoutTime" BU_SG_REL_ NightVision SG_ 1719 KBI_QBit_Aussen_Temp_gef 5000;
BA_REL_ "GenSigTimeoutTime" BU_SG_REL_ NightVision SG_ 1719 KBI_Aussen_Temp_gef 5000;
BA_REL_ "GenSigTimeoutTime" BU_SG_REL_ NightVision SG_ 1614 KBI_HUD_Data_01 5000;
BA_REL_ "GenSigTimeoutTime" BU_SG_REL_ NightVision SG_ 1614 KBI_HUD_Data_02 5000;
BA_REL_ "GenSigTimeoutTime" BU_SG_REL_ NightVision SG_ 1614 KBI_HUD_Data_03 5000;
BA_REL_ "GenSigTimeoutTime" BU_SG_REL_ NightVision SG_ 1614 KBI_HUD_Data_04 5000;
BA_REL_ "GenSigTimeoutTime" BU_SG_REL_ NightVision SG_ 1614 KBI_HUD_Data_05 5000;
BA_REL_ "GenSigTimeoutTime" BU_SG_REL_ NightVision SG_ 1614 KBI_HUD_Data_06 5000;
BA_REL_ "GenSigTimeoutTime" BU_SG_REL_ NightVision SG_ 1614 KBI_HUD_Data_07 5000;
BA_REL_ "GenSigTimeoutTime" BU_SG_REL_ NightVision SG_ 1614 KBI_HUD_Data_08 5000;
BA_REL_ "GenSigTimeoutTime" BU_SG_REL_ NightVision SG_ 1624 LV_Abblendlicht_Anzeige 5000;
BA_REL_ "GenSigTimeoutTime" BU_SG_REL_ NightVision SG_ 1624 LV_Abblendlicht_li_def 5000;
BA_REL_ "GenSigTimeoutTime" BU_SG_REL_ NightVision SG_ 1624 LV_Abblendlicht_re_def 5000;
BA_REL_ "GenSigTimeoutTime" BU_SG_REL_ NightVision SG_ 1624 BCM1_Licht_Dunkelheit_aktiv 5000;
BA_REL_ "GenSigTimeoutTime" BU_SG_REL_ NightVision SG_ 917 LWR_Hoehenwert_VL 1000;
BA_REL_ "GenSigTimeoutTime" BU_SG_REL_ NightVision SG_ 917 LWR_Hoehenwert_HL 1000;
BA_REL_ "GenSigTimeoutTime" BU_SG_REL_ NightVision SG_ 917 LWR_AFS_Grundeinstellung 1000;
BA_REL_ "GenSigTimeoutTime" BU_SG_REL_ NightVision SG_ 1153 Nav_FoD_Status 5000;
BA_REL_ "GenSigTimeoutTime" BU_SG_REL_ NightVision SG_ 958 MO_StartStopp_Motorstopp 1000;
BA_REL_ "GenSigTimeoutTime" BU_SG_REL_ NightVision SG_ 958 MO_Gangposition 1000;
BA_REL_ "GenSigTimeoutTime" BU_SG_REL_ RDK SG_ 779 KBI_MFA_v_Einheit_01 500;
BA_REL_ "GenSigTimeoutTime" BU_SG_REL_ RDK SG_ 779 KBI_V_Digital 500;
BA_REL_ "GenSigTimeoutTime" BU_SG_REL_ RDK SG_ 1719 KBI_RDK_Kalibrier_Anf 5000;
BA_REL_ "GenSigTimeoutTime" BU_SG_REL_ RDK SG_ 1719 KBI_QBit_Aussen_Temp_gef 5000;
BA_REL_ "GenSigTimeoutTime" BU_SG_REL_ RDK SG_ 1719 KBI_Aussen_Temp_gef 5000;
BA_REL_ "GenSigTimeoutTime" BU_SG_REL_ SAK SG_ 167 MO_Mom_Ist_Summe 500;
BA_REL_ "GenSigTimeoutTime" BU_SG_REL_ SAK SG_ 168 MO_Drehzahl_01 500;
BA_REL_ "GenSigTimeoutTime" BU_SG_REL_ SAK SG_ 958 MO_Gangposition 1000;
BA_REL_ "GenSigTimeoutTime" BU_SG_REL_ SAK SG_ 958 MO_Kuppl_schalter 1000;
BA_REL_ "GenSigTimeoutTime" BU_SG_REL_ SAK SG_ 958 MO_Zylinderabschaltung 1000;
BA_REL_ "GenSigTimeoutTime" BU_SG_REL_ SAK SG_ 958 MO_HYB_VM_aktiv 1000;
BA_REL_ "GenSigTimeoutTime" BU_SG_REL_ SAK2 SG_ 1719 KBI_Aussen_Temp_gef 5000;
BA_REL_ "GenSigTimeoutTime" BU_SG_REL_ SAK2 SG_ 167 MO_Mom_Ist_Summe 500;
BA_REL_ "GenSigTimeoutTime" BU_SG_REL_ SAK2 SG_ 168 MO_Drehzahl_01 500;
BA_REL_ "GenSigTimeoutTime" BU_SG_REL_ SAK2 SG_ 958 MO_Gangposition 1000;
BA_REL_ "GenSigTimeoutTime" BU_SG_REL_ SAK2 SG_ 958 MO_Kuppl_schalter 1000;
BA_REL_ "GenSigTimeoutTime" BU_SG_REL_ SAK2 SG_ 958 MO_Zylinderabschaltung 1000;
BA_REL_ "GenSigTimeoutTime" BU_SG_REL_ SAK2 SG_ 958 MO_HYB_VM_aktiv 1000;
BA_REL_ "GenSigTimeoutTime" BU_SG_REL_ SCR SG_ 1719 KBI_Aussen_Temp_gef 5000;
BA_REL_ "GenSigTimeoutTime" BU_SG_REL_ SCR SG_ 168 MO_QBit_Drehzahl_01 500;
BA_REL_ "GenSigTimeoutTime" BU_SG_REL_ SCR SG_ 168 MO_Drehzahl_01 500;
BA_REL_ "GenSigTimeoutTime" BU_SG_REL_ SCR SG_ 958 MO_StartStopp_Status 1000;
BA_REL_ "GenSigTimeoutTime" BU_SG_REL_ SCR SG_ 958 MO_StartStopp_Wiederstart 1000;
BA_REL_ "GenSigTimeoutTime" BU_SG_REL_ SCR SG_ 958 MO_StartStopp_Motorstopp 1000;
BA_REL_ "GenSigTimeoutTime" BU_SG_REL_ SCR SG_ 958 MO_Kl_75 1000;
BA_REL_ "GenSigTimeoutTime" BU_SG_REL_ SCR SG_ 958 MO_StartStopp_Fahrerwunsch 1000;
BA_REL_ "GenSigTimeoutTime" BU_SG_REL_ SCR SG_ 958 MO_QBit_KL_75 1000;
BA_REL_ "GenSigTimeoutTime" BU_SG_REL_ SCR SG_ 1648 MO_Abstellzeit 5000;
BA_REL_ "GenSigTimeoutTime" BU_SG_REL_ SCR SG_ 1648 MO_Abstellzeit_Status 5000;
BA_REL_ "GenSigTimeoutTime" BU_SG_REL_ SCR SG_ 1010 Motor_19_BZ 800;
BA_REL_ "GenSigTimeoutTime" BU_SG_REL_ SCR SG_ 1010 MO_SCR_Heizkreis_3_Leistung 800;
BA_REL_ "GenSigTimeoutTime" BU_SG_REL_ SCR SG_ 1010 MO_SCR_Tankheizkreis_Leistung 800;
BA_REL_ "GenSigTimeoutTime" BU_SG_REL_ SCR SG_ 1010 MO_SCR_Heizkreis_3 800;
BA_REL_ "GenSigTimeoutTime" BU_SG_REL_ SCR SG_ 1010 MO_SCR_Tankheizung 800;
BA_REL_ "GenSigTimeoutTime" BU_SG_REL_ SCR SG_ 1010 MO_SCR_Dosierpumpe_Zustand 800;
BA_REL_ "GenSigTimeoutTime" BU_SG_REL_ SCR SG_ 1010 MO_SCR_Leitungsheizung 800;
BA_REL_ "GenSigTimeoutTime" BU_SG_REL_ SCR SG_ 1010 MO_SCR_Dosierpumpe_Wartezeit 800;
BA_REL_ "GenSigTimeoutTime" BU_SG_REL_ SCR SG_ 1010 MO_SCR_Dosierpumpe_Soll 800;
BA_REL_ "GenSigTimeoutTime" BU_SG_REL_ STH_MLBevo SG_ 779 KBI_Tankwarnung 500;
BA_REL_ "GenSigTimeoutTime" BU_SG_REL_ STH_MLBevo SG_ 1719 KBI_Standzeit_02 5000;
BA_REL_ "GenSigTimeoutTime" BU_SG_REL_ STH_MLBevo SG_ 1719 KBI_Inhalt_Tank 5000;
BA_REL_ "GenSigTimeoutTime" BU_SG_REL_ STH_MLBevo SG_ 1719 KBI_FStatus_Tank 5000;
BA_REL_ "GenSigTimeoutTime" BU_SG_REL_ STH_MLBevo SG_ 1719 KBI_QBit_Aussen_Temp_gef 5000;
BA_REL_ "GenSigTimeoutTime" BU_SG_REL_ STH_MLBevo SG_ 1719 KBI_Aussen_Temp_gef 5000;
BA_REL_ "GenSigTimeoutTime" BU_SG_REL_ STH_MLBevo SG_ 1600 MO_QBit_Kuehlmittel_Temp 3200;
BA_REL_ "GenSigTimeoutTime" BU_SG_REL_ STH_MLBevo SG_ 1600 MO_Absperrventil_oeffnen 3200;
BA_REL_ "GenSigTimeoutTime" BU_SG_REL_ STH_MLBevo SG_ 1600 MO_Kuehlmittel_Temp 3200;
BA_REL_ "GenSigTimeoutTime" BU_SG_REL_ STH_MLBevo SG_ 1600 MO_Hoeheninfo 3200;
BA_REL_ "GenSigTimeoutTime" BU_SG_REL_ STH_MLBevo SG_ 1600 MO_Heizungspumpenansteuerung 3200;
BA_REL_ "GenSigTimeoutTime" BU_SG_REL_ STH_MLBevo SG_ 1600 MO_Nachlaufzeit_Heizungspumpe 3200;
BA_REL_ "GenSigTimeoutTime" BU_SG_REL_ STH_MLBevo SG_ 168 MO_QBit_Drehzahl_01 500;
BA_REL_ "GenSigTimeoutTime" BU_SG_REL_ STH_MLBevo SG_ 168 MO_Drehzahl_01 500;
BA_REL_ "GenSigTimeoutTime" BU_SG_REL_ STH_MLBevo SG_ 958 MO_StartStopp_Wiederstart 1000;
BA_REL_ "GenSigTimeoutTime" BU_SG_REL_ STH_MLBevo SG_ 958 MO_StartStopp_Motorstopp 1000;
BA_REL_ "GenSigTimeoutTime" BU_SG_REL_ STH_MLBevo SG_ 958 MO_Motor_laeuft 1000;
BA_REL_ "GenSigTimeoutTime" BU_SG_REL_ STH_MLBevo SG_ 958 MO_Handshake_STH 1000;
BA_REL_ "GenSigTimeoutTime" BU_SG_REL_ TopView SG_ 779 KBI_ESP_Lampe 500;
BA_REL_ "GenSigTimeoutTime" BU_SG_REL_ TopView SG_ 160 EPS_Lenkmoment_AbsReduz 500;
BA_REL_ "GenSigTimeoutTime" BU_SG_REL_ TopView SG_ 160 EPS_Zahnstangen_Pos 500;
BA_REL_ "GenSigTimeoutTime" BU_SG_REL_ TopView SG_ 160 EPS_VZ_Zahnstangenposition 500;
BA_REL_ "GenSigTimeoutTime" BU_SG_REL_ TopView SG_ 160 EPS_QBit_Zahnstangen_Pos 500;
BA_REL_ "GenSigTimeoutTime" BU_SG_REL_ TopView SG_ 981 BCM_Rueckfahrlicht_Anf 1000;
BA_REL_ "GenSigTimeoutTime" BU_SG_REL_ TopView SG_ 917 LWR_Hoehenwert_VL 1000;
BA_REL_ "GenSigTimeoutTime" BU_SG_REL_ TopView SG_ 917 LWR_Hoehenwert_HL 1000;
VAL_ 2549088295 Nightvision_KompSchutz 0 "inaktiv" 1 "aktiv" ;
VAL_ 2549088295 Nightvision_Abschaltstufe 0 "keine_Einschraenkung" 1 "Funktionseinschraenkung" ;
VAL_ 2549088295 Nightvision_Transport_Mode 0 "keine_Einschraenkung" 1 "Funktionseinschraenkung" ;
VAL_ 2549088295 Nightvision_Nachlauftyp 0 "Komm_bei_KL15_EIN" 1 "Komm_nach_KL15_AUS" 2 "Komm_bei_KL15_AUS" ;
VAL_ 2549088295 Nightvision_SNI 39 "Nightvision" ;
VAL_ 2549088295 NM_Nightvision_Wakeup 0 "Peripherie_Wakeup__Ursache_nicht_bekannt" 1 "Bus_Wakeup" 2 "KL15_HW" ;
VAL_ 2549088295 Nightvision_Lokalaktiv 0 "war_nicht_lokal_aktiv" 1 "war_lokal_aktiv" ;
VAL_ 2549088295 Nightvision_Subsystemaktiv 0 "Subsystem_war_nicht_lokalaktiv" 1 "war_lokalaktiv" ;
VAL_ 2549088295 Nightvision_KD_Fehler 0 "kein_KD_Fehler" 1 "KD_Fehler" ;
VAL_ 2549088267 RDK_KompSchutz 0 "inaktiv" 1 "aktiv" ;
VAL_ 2549088267 RDK_Abschaltstufe 0 "keine_Einschraenkung" 1 "Funktionseinschraenkung" ;
VAL_ 2549088267 RDK_Transport_Mode 0 "keine_Einschraenkung" 1 "Funktionseinschraenkung" ;
VAL_ 2549088267 RDK_Nachlauftyp 0 "Komm_bei_KL15_EIN" 1 "Komm_nach_KL15_AUS" 2 "Komm_bei_KL15_AUS" ;
VAL_ 2549088267 RDK_SNI 11 "RDK" ;
VAL_ 2549088267 KN_RDK_BusKnockOutTimer 255 "BusKnockOut_deaktiviert" ;
VAL_ 2549088267 NM_RDK_Wakeup 0 "Peripherie_Wakeup__Ursache_nicht_bekannt" 1 "Bus_Wakeup" 2 "KL15_HW" ;
VAL_ 2549088267 NM_RDK_Lokalaktiv 0 "war_nicht_lokal_aktiv" 1 "war_lokal_aktiv" ;
VAL_ 2549088267 NM_RDK_Subsystemaktiv 0 "Subsystem_war_nicht_lokalaktiv" 1 "war_lokalaktiv" ;
VAL_ 2549088267 RDK_KD_Fehler 0 "kein_KD_Fehler" 1 "KD_Fehler" ;
VAL_ 2549088361 Rearview_KompSchutz 0 "inaktiv" 1 "aktiv" ;
VAL_ 2549088361 Rearview_Abschaltstufe 0 "keine_Einschraenkung" 1 "Funktionseinschraenkung" ;
VAL_ 2549088361 Rearview_Transport_Mode 0 "keine_Einschraenkung" 1 "Funktionseinschraenkung" ;
VAL_ 2549088361 Rearview_Nachlauftyp 0 "Komm_bei_KL15_EIN" 1 "Komm_nach_KL15_AUS" 2 "Komm_bei_KL15_AUS" ;
VAL_ 2549088361 Rearview_SNI 105 "Rearview" ;
VAL_ 2549088361 KN_Rearview_BusKnockOutTimer 255 "BusKnockOut_deaktiviert" ;
VAL_ 2549088361 NM_Rearview_Wakeup 0 "Peripherie_Wakeup__Ursache_nicht_bekannt" 1 "Bus_Wakeup" 2 "KL15_HW" ;
VAL_ 2549088361 Rearview_Lokalaktiv 0 "war_nicht_lokal_aktiv" 1 "war_lokal_aktiv" ;
VAL_ 2549088361 Rearview_Subsystemaktiv 0 "Subsystem_war_nicht_lokalaktiv" 1 "war_lokalaktiv" ;
VAL_ 2549088361 RV_KD_Fehler 0 "kein_KD_Fehler" 1 "KD_Fehler" ;
VAL_ 2549088284 SAK_KompSchutz 0 "inaktiv" 1 "aktiv" ;
VAL_ 2549088284 SAK_Abschaltstufe 0 "keine_Einschraenkung" 1 "Funktionseinschraenkung" ;
VAL_ 2549088284 SAK_Transport_Mode 0 "keine_Einschraenkung" 1 "Funktionseinschraenkung" ;
VAL_ 2549088284 SAK_Nachlauftyp 0 "Komm_bei_KL15_EIN" 1 "Komm_nach_KL15_AUS" 2 "Komm_bei_KL15_AUS" ;
VAL_ 2549088284 SAK_SNI 28 "SAK" ;
VAL_ 2549088284 NM_SAK_Wakeup 0 "Peripherie_Wakeup__Ursache_nicht_bekannt" 1 "Bus_Wakeup" 2 "KL15_HW" ;
VAL_ 2549088284 SAK_Lokalaktiv 0 "war_nicht_lokal_aktiv" 1 "war_lokal_aktiv" ;
VAL_ 2549088284 SAK_Subsystemaktiv 0 "Subsystem_war_nicht_lokalaktiv" 1 "war_lokalaktiv" ;
VAL_ 2549088284 SAK_KD_Fehler 0 "kein_KD_Fehler" 1 "KD_Fehler" ;
VAL_ 2549088298 SCR_KompSchutz 0 "inaktiv" 1 "aktiv" ;
VAL_ 2549088298 SCR_Abschaltstufe 0 "keine_Einschraenkung" 1 "Funktionseinschraenkung" ;
VAL_ 2549088298 SCR_Transport_Mode 0 "keine_Einschraenkung" 1 "Funktionseinschraenkung" ;
VAL_ 2549088298 SCR_Nachlauftyp 0 "Komm_bei_KL15_EIN" 1 "Komm_nach_KL15_AUS" 2 "Komm_bei_KL15_AUS" ;
VAL_ 2549088298 SCR_SNI 42 "SCR" ;
VAL_ 2549088298 KN_SCR_BusKnockOutTimer 255 "BusKnockOut_deaktiviert" ;
VAL_ 2549088298 NM_SCR_Wakeup 0 "Peripherie_Wakeup__Ursache_nicht_bekannt" 1 "Bus_Wakeup" 2 "KL15_HW" 3 "OBD_Diagnoseinformationen" ;
VAL_ 2549088298 NMH_SCR_Lokalaktiv 0 "war_nicht_lokal_aktiv" 1 "war_lokal_aktiv" ;
VAL_ 2549088298 NMH_SCR_Subsystemaktiv 0 "Subsystem_war_nicht_lokalaktiv" 1 "war_lokalaktiv" ;
VAL_ 2549088298 SCR_KD_Fehler 0 "kein_KD_Fehler" 1 "KD_Fehler" ;
VAL_ 2549088362 STH_KompSchutz 0 "inaktiv" 1 "aktiv" ;
VAL_ 2549088362 STH_Abschaltstufe 0 "keine_Einschraenkung" 1 "Funktionseinschraenkung" ;
VAL_ 2549088362 STH_Transport_Mode 0 "keine_Einschraenkung" 1 "Funktionseinschraenkung" ;
VAL_ 2549088362 STH_Nachlauftyp 0 "Komm_bei_KL15_EIN" 1 "Komm_nach_KL15_AUS" 2 "Komm_bei_KL15_AUS" ;
VAL_ 2549088362 STH_SNI 106 "STH" ;
VAL_ 2549088362 KN_STH_BusKnockOutTimer 255 "BusKnockOut_deaktiviert" ;
VAL_ 2549088362 NM_STH_Wakeup 0 "Peripherie_Wakeup__Ursache_nicht_bekannt" 1 "Bus_Wakeup" 2 "KL15_HW" 3 "STH_EIN_AUS_Funk" 4 "Datentransfer_Funk" 128 "Anf_Schwalltopf_fuellen" 129 "Anf_Geblaese" 130 "Anf_WaPu_Starten" 131 "Abschalten_Fehlerfall" 132 "STH_STL_Einschalt_Ausschaltwunsch" ;
VAL_ 2549088362 NMH_STH_Lokalaktiv 0 "war_nicht_lokal_aktiv" 1 "war_lokal_aktiv" ;
VAL_ 2549088362 NMH_STH_Subsystemaktiv 0 "Subsystem_war_nicht_lokalaktiv" 1 "war_lokalaktiv" ;
VAL_ 2549088362 STH_KD_Fehler 0 "kein_KD_Fehler" 1 "KD_Fehler" ;
VAL_ 2549088334 SWA_KompSchutz 0 "inaktiv" 1 "aktiv" ;
VAL_ 2549088334 SWA_Abschaltstufe 0 "keine_Einschraenkung" 1 "Funktionseinschraenkung" ;
VAL_ 2549088334 SWA_Transport_Mode 0 "keine_Einschraenkung" 1 "Funktionseinschraenkung" ;
VAL_ 2549088334 SWA_Nachlauftyp 0 "Komm_bei_KL15_EIN" 1 "Komm_nach_KL15_AUS" 2 "Komm_bei_KL15_AUS" ;
VAL_ 2549088334 SWA_SNI 78 "SWA" ;
VAL_ 2549088334 KN_SWA_BusKnockOutTimer 255 "BusKnockOut_deaktiviert" ;
VAL_ 2549088334 NM_SWA_Wakeup 0 "Peripherie_Wakeup__Ursache_nicht_bekannt" 1 "Bus_Wakeup" 2 "KL15_HW" ;
VAL_ 2549088334 SWA_Lokalaktiv 0 "war_nicht_lokal_aktiv" 1 "war_lokal_aktiv" ;
VAL_ 2549088334 SWA_Subsystemaktiv 0 "Subsystem_war_nicht_lokalaktiv" 1 "war_lokalaktiv" ;
VAL_ 2549088334 SWA_KD_Fehler 0 "kein_KD_Fehler" 1 "KD_Fehler" ;
VAL_ 2549088394 SWA_2_KompSchutz 0 "inaktiv" 1 "aktiv" ;
VAL_ 2549088394 SWA_2_Abschaltstufe 0 "keine_Einschraenkung" 1 "Funktionseinschraenkung" ;
VAL_ 2549088394 SWA_2_Transport_Mode 0 "keine_Einschraenkung" 1 "Funktionseinschraenkung" ;
VAL_ 2549088394 SWA_2_Nachlauftyp 0 "Komm_bei_KL15_EIN" 1 "Komm_nach_KL15_AUS" 2 "Komm_bei_KL15_AUS" ;
VAL_ 2549088394 SWA_2_SNI 138 "SWA_2" ;
VAL_ 2549088394 KN_SWA_Slave_BusKnockOutTimer 255 "BusKnockOut_deaktiviert" ;
VAL_ 2549088394 NM_SWA_2_Wakeup 0 "Peripherie_Wakeup__Ursache_nicht_bekannt" 1 "Bus_Wakeup" 2 "KL15_HW" ;
VAL_ 2549088394 SWA_2_Lokalaktiv 0 "war_nicht_lokal_aktiv" 1 "war_lokal_aktiv" ;
VAL_ 2549088394 SWA_2_Subsystemaktiv 0 "Subsystem_war_nicht_lokalaktiv" 1 "war_lokalaktiv" ;
VAL_ 2549088394 SWA_2_KD_Fehler 0 "kein_KD_Fehler" 1 "KD_Fehler" ;
VAL_ 779 KBI_ABS_Lampe 0 "ABS Lampe aus" 1 "ABS Lampe ein" ;
VAL_ 779 KBI_ESP_Lampe 0 "ESP Lampe aus" 1 "ESP Lampe ein" ;
VAL_ 779 KBI_BKL_Lampe 0 "BKL aus" 1 "BKL ein" ;
VAL_ 779 KBI_Airbag_Lampe 0 "Airbag Lampe aus" 1 "Airbag Lampe ein" ;
VAL_ 779 KBI_SILA_gueltig 0 "ungueltig" 1 "gueltig" ;
VAL_ 779 KBI_Vorglueh_System_Lampe 0 "Lampe aus" 1 "Lampe ein" ;
VAL_ 779 KBI_NV_in_Anzeige 0 "NV_nicht_in_Anzeige" 1 "NV_in_Anzeige" ;
VAL_ 779 KBI_Anzeigestatus_ACC 0 "keine_ACC_Anzeige" 1 "ACC_Anzeige_aktiv" ;
VAL_ 779 KBI_Anzeigestatus_GRA 0 "nicht_vorhanden" 1 "Anzeigemoeglichkeit_vorhanden" 2 "reserviert" 3 "Fehler" ;
VAL_ 779 KBI_Tankwarnung 0 "Lampe aus" 1 "Lampe ein" ;
VAL_ 779 KBI_MFA_v_Einheit_01 0 "kmh" 1 "mph" ;
VAL_ 779 KBI_im_Stellgliedtest 0 "kein Stellgliedtest" 1 "Kombi im Stellgliedtest" ;
VAL_ 779 KBI_Anzeigefehler_LDW 0 "nicht vorhanden bzw. unterstützt" 1 "Anzeige iO" 2 "Anzeigefehler" 3 "nicht definiert" ;
VAL_ 779 KBI_Tankwarnung_ungueltig 0 "KBI_Tankwarnung_gueltig" 1 "KBI_Tankwarnung_ungueltig" ;
VAL_ 779 KBI_Handbremse 0 "nicht_angezogen" 1 "angezogen" ;
VAL_ 779 KBI_PLA_in_Anzeige 0 "PLA_nicht_in_Anzeige" 1 "PLA_in_Anzeige" ;
VAL_ 779 KBI_Anzeigefehler_NV 0 "kein_Anzeigefehler" 1 "Anzeigefehler" ;
VAL_ 779 KBI_Anzeigestatus_LIM 0 "nicht_vorhanden" 1 "Anzeigemoeglichkeit_vorhanden" 2 "reserviert" 3 "Fehler" ;
VAL_ 779 KBI_ARA_in_Anzeige 0 "ARA nicht in Anzeige" 1 "ARA in Anzeige" ;
VAL_ 779 KBI_Taster_Lift 0 "nicht_betaetigt" 1 "betaetigt" ;
VAL_ 779 KBI_Taster_Fahrwerk 0 "nicht_betaetigt" 1 "betaetigt" ;
VAL_ 779 KBI_Einheit_Tacho 0 "km/h" 1 "mph" ;
VAL_ 779 KBI_Konsistenz_ACC 0 "ACC Botschaft konsistent" 1 "ACC Botschaft inkonsistent" ;
VAL_ 779 KBI_Fehler_Anzeige_ACC 0 " iO" 1 "Anzeigefehler ACC" ;
VAL_ 779 KBI_Anzeigefehler_SWA 0 "nicht vorhanden bzw. unterstützt" 1 "Anzeige iO" 2 "Anzeigefehler" 3 "nicht definiert" ;
VAL_ 779 KBI_Systemstatus 0 "KBI_IO" 1 "KBI_System_Failure" ;
VAL_ 1719 KBI_Kilometerstand 1048574 "Init" 1048575 "Fehler" ;
VAL_ 1719 KBI_Standzeit_02 131069 "nicht_verfuegbar" 131070 "Init" 131071 "Fehler" ;
VAL_ 1719 KBI_LVDS_Lock 0 "Init_LVDS_nicht_gelockt" 1 "LVDS_gelockt" ;
VAL_ 1719 KBI_Reserve_Warnung_Sek 0 "Keine_Warnung" 1 "Sekundaere_Reservewarnung" ;
VAL_ 1719 KBI_RDK_Kalibrier_Anf 0 "keine_Kalibrieranforderung" 1 "Kalibrieranforderung" ;
VAL_ 1719 KBI_Inhalt_Tank 126 "Init" 127 "Fehler" ;
VAL_ 1719 KBI_FStatus_Tank 0 "Tankfüllstand i.O." 1 "Tankfüllstand n.i.O" ;
VAL_ 1719 KBI_aktive_Laengsfunktion 0 "Init" 1 "Speedlimiter" 2 "GRA_oder_ACC" 3 "PACCh" 4 "HDC" 5 "p_GRA" 6 "p_Lim" 7 "Umschaltung_GRA_Limiter" ;
VAL_ 1719 KBI_FoD_PopUP_Quittiert 0 "nicht_quittiert" 1 "Meldung_quittiert" ;
VAL_ 1719 KBI_GRA_im_ACC 0 "GRA_im_ACC_nicht_ausgewaehlt" 1 "GRA_im_ACC_ausgewaehlt" ;
VAL_ 1719 KBI_Oelwechsel_durchgefuehrt 0 "Oelwechsel_nicht_durchgefuehrt" 1 "Oelwechsel_durchgefuehrt" ;
VAL_ 1719 KBI_QBit_Aussen_Temp_gef 0 "gueltiger_Wert" 1 "Ersatz_Init_oder_Fehlerwert" ;
VAL_ 1719 KBI_Aussen_Temp_gef 253 "nicht verbaut" 254 "Init" 255 "Fehler" ;
VAL_ 1614 KBI_HUD_Data_01 0 "Init" ;
VAL_ 1614 KBI_HUD_Data_02 0 "Init" ;
VAL_ 1614 KBI_HUD_Data_03 0 "Init" ;
VAL_ 1614 KBI_HUD_Data_04 0 "Init" ;
VAL_ 1614 KBI_HUD_Data_05 0 "Init" ;
VAL_ 1614 KBI_HUD_Data_06 0 "Init" ;
VAL_ 1614 KBI_HUD_Data_07 0 "Init" ;
VAL_ 1614 KBI_HUD_Data_08 0 "Init" ;
VAL_ 160 EPS_Lenkmoment_AbsReduz 13 "MAX" 14 "Init" 15 "Fehler" ;
VAL_ 160 EPS_FAS_Regelgroesse 62 "Init" 63 "Fehler" ;
VAL_ 160 EPS_FAS_VZ_Regelgroesse 0 "positiv" 1 "negativ" ;
VAL_ 160 EPS_Motormoment 0 "Not_in_use" 254 "Init" 255 "Fehler" ;
VAL_ 160 EPS_Zahnstangen_Pos 4094 "Init" 4095 "Fehler" ;
VAL_ 160 EPS_VZ_Zahnstangenposition 0 "pos_VZ" 1 "neg_VZ" ;
VAL_ 160 EPS_QBit_Zahnstangen_Pos 0 "gueltiger_Wert" 1 "Ersatz_Init_oder_Fehlerwert" ;
VAL_ 160 EPS_Versorgungsstatus 0 "kein_Fehler" 1 "Unterspannung" 2 "Ueberspannung" 3 "Stoerung" ;
VAL_ 160 EPS_Versorgungsspannung 254 "Init" 255 "Fehler" ;
VAL_ 160 EPS_AWA_Status 0 "AWA_deaktiviert" 1 "AWA_Anf_nicht_ausfuehrbar" 2 "Kom_AWA_gestoert" 3 "EPS_bzgl_AWA_funktionsbereit" 4 "AWA_Anf_abgew" 5 "AWA_Momeingriff_1_aktiv" 6 "reserviert" 7 "AWA_Momeingriff_2_aktiv" 8 "AWA_abgewiesen_aufgrund_Momentenpriorisierung" 9 "Anf_abgewiesen_Bedienueblich" 14 "Init" ;
VAL_ 160 EPS_STA_Status 0 "STA_bzw_STP_deaktiviert" 1 "Anf_nicht_ausfuehrbar" 2 "Kommunikationsfehler" 3 "EPS_bzgl_STA_bzw_STP_funktionsbereit" 4 "Anf_abgewiesen_Fehler" 5 "gesperrt" 6 "STA_bzw_STP_Winkeleingriff_aktiv" 7 "gesperrt" 8 "Anf_abgewiesen_Prio" 9 "Anf_abgewiesen_Bedienueblich" 10 "Winkeleingriff_abgebrochen" 11 "Rueckfallmodus_Winkeleingriff" 12 "Notlauf_Winkelregelung_aktiv" 14 "Init" 15 "Schnittstellendeaktiverung_UEF" ;
VAL_ 981 BCM1_Kurvenlicht_links_Anf 0 "linkes_Kurvenlicht/Abbiegelicht_durch_BCM1_nicht_angesteuert" 1 "linkes_Kurven/Abbiegelicht_durch_BCM1_angesteuert" ;
VAL_ 981 BCM1_Kurvenlicht_rechts_Anf 0 "rechtes_Kurvenlicht/Abbiegelicht_durch_BCM1_nicht_angesteuert" 1 "rechtes_Kurvenlicht/Abbiegelicht_durch_BCM1_angesteuert" ;
VAL_ 981 BCM1_Standlicht_Anf 0 "Licht_nicht_angefordert" 1 "Licht ist einzuschalten" ;
VAL_ 981 BCM1_Abblendlicht_Anf 0 "Licht_nicht_angefordert" 1 "Licht ist einzuschalten" ;
VAL_ 981 BCM1_Fernlicht_Anf 0 "Licht_nicht_angefordert" 1 "Licht ist einzuschalten" ;
VAL_ 981 BCM1_Nebellicht_Anf 0 "Licht_nicht_angefordert" 1 "Licht ist einzuschalten" ;
VAL_ 981 BCM1_Parklicht_li_Anf 0 "Licht_nicht_angefordert" 1 "Licht ist einzuschalten" ;
VAL_ 981 BCM1_Parklicht_re_Anf 0 "Licht_nicht_angefordert" 1 "Licht ist einzuschalten" ;
VAL_ 981 BCM1_Nebelschluss_Ahg_Anf 0 "Licht_nicht_angefordert" 1 "Licht ist einzuschalten" ;
VAL_ 981 BCM1_Nebelschluss_Fzg_Anf 0 "Licht_nicht_angefordert" 1 "Licht ist einzuschalten" ;
VAL_ 981 BCM1_Schlusslicht_Anf 0 "Licht_nicht_angefordert" 1 "Licht ist einzuschalten" ;
VAL_ 981 BCM_Rueckfahrlicht_Anf 0 "Licht_nicht_angefordert" 1 "Licht_angefordert" ;
VAL_ 981 BCM1_Signaturlicht_Anf 0 "Licht_nicht_angefordert" 1 "Licht_ist_einzuschalten" ;
VAL_ 981 BCM1_Umfeldleuchten_Anf 0 "Licht_nicht_angefordert" 1 "Licht ist einzuschalten" ;
VAL_ 981 BCM1_Tagfahrlicht_Anf 0 "Licht_nicht_angefordert" 1 "Licht ist einzuschalten" ;
VAL_ 981 BCM1_Regenlicht_Anf 0 "Licht_nicht_angefordert" 1 "Licht ist einzuschalten" ;
VAL_ 981 BCM1_Autobahnlicht_Anf 0 "Licht_nicht_angefordert" 1 "Licht ist einzuschalten" ;
VAL_ 981 BCM1_Touristen_Licht_Anf 0 "Licht_nicht_angefordert" 1 "Anforderung von Touristenlicht" ;
VAL_ 981 BCM1_CH_aktiv 0 "Inaktiv" 1 "Aktiv" ;
VAL_ 981 BCM1_LH_aktiv 0 "Inaktiv" 1 "Aktiv" ;
VAL_ 981 BCM1_Gleitende_Leuchtw_Anf 0 "Aus" 1 "Ein" ;
VAL_ 981 BCM1_GLW_Fernlicht_Anf 0 "Aus" 1 "Ein" ;
VAL_ 981 BCM1_Adaptive_Lichtvert_Anf 0 "Aus" 1 "Ein" ;
VAL_ 981 BCM1_FoD_Sperrung_WiBli 0 "Freigabe_WiBli" 1 "Sperrung_WiBli" 2 "Init" ;
VAL_ 981 BCM1_FOD_Sperrung_Animationen_HL 0 "Freigabe_Animationen" 1 "Sperrung_Animationen" 2 "Init" ;
VAL_ 981 BCM1_Animationssperrung 0 "keine_Sperrung" 1 "Sperrung" ;
VAL_ 981 BCM1_CH_LH_aktiv 0 "Comming_Home_Bzw._Leaving_Home_nicht_aktiv" 1 "Comming Home bzw. Leaving Home aktiv" ;
VAL_ 981 BCM1_Allwetterlicht_Anf 0 "Licht_nicht_angefordert" 1 "Licht_ist_einzuschalten" ;
VAL_ 1624 LV_Standlicht_Anzeige 0 "nicht aktiv" 1 "aktiv" ;
VAL_ 1624 LV_Abblendlicht_Anzeige 0 "inaktiv" 1 "aktiv" ;
VAL_ 1624 LV_Fernlicht_Anzeige 0 "nicht aktiv" 1 "aktiv" ;
VAL_ 1624 LV_Nebellicht_Anzeige 0 "nicht aktiv" 1 "aktiv" ;
VAL_ 1624 LV_Nebelschlusslicht_Anzeige 0 "nicht aktiv" 1 "aktiv" ;
VAL_ 1624 LV_Tagfahrlicht_Anzeige 0 "nicht aktiv" 1 "aktiv" ;
VAL_ 1624 LV_AFL_aktiv_Anzeige 0 "nicht aktiv" 1 "aktiv" ;
VAL_ 1624 LV_AFL_defekt 0 "OK" 1 "defekt" ;
VAL_ 1624 LV_Blinker_li_def 0 "OK" 1 "defekt" ;
VAL_ 1624 LV_Standlicht_li_def 0 "OK" 1 "defekt" ;
VAL_ 1624 LV_Abblendlicht_li_def 0 "OK" 1 "defekt" ;
VAL_ 1624 LV_Fernlicht_li_def 0 "OK" 1 "defekt" ;
VAL_ 1624 LV_Nebellicht_li_def 0 "OK" 1 "defekt" ;
VAL_ 1624 LV_Blk_li_Seite_def 0 "OK" 1 "defekt" ;
VAL_ 1624 LV_Tagfahrlicht_li_def 0 "OK" 1 "defekt" ;
VAL_ 1624 LV_FLA_aktiv_Anzeige 0 "aus" 1 "ein" ;
VAL_ 1624 LV_FLA_defekt 0 "i.O." 1 "FLA defekt" ;
VAL_ 1624 LV_FLA_Sensor_blockiert 0 "i.O." 1 "FLA-Sensor blockiert" ;
VAL_ 1624 LV_Blinker_re_def 0 "OK" 1 "defekt" ;
VAL_ 1624 LV_Standlicht_re_def 0 "OK" 1 "defekt" ;
VAL_ 1624 LV_Abblendlicht_re_def 0 "OK" 1 "defekt" ;
VAL_ 1624 LV_Fernlicht_re_def 0 "OK" 1 "defekt" ;
VAL_ 1624 LV_Nebellicht_re_def 0 "OK" 1 "defekt" ;
VAL_ 1624 LV_Blk_re_Seite_def 0 "OK" 1 "defekt" ;
VAL_ 1624 LV_Tagfahrlicht_re_def 0 "OK" 1 "defekt" ;
VAL_ 1624 LV_Aussenlicht_def 0 "OK" 1 "defekt" ;
VAL_ 1624 LV_Abblendlicht_TFL_li_def 0 "OK" 1 "defekt" ;
VAL_ 1624 LV_Nebellicht_TFL_li_def 0 "OK" 1 "defekt" ;
VAL_ 1624 LV_Standlicht_TFL_li_def 0 "OK" 1 "defekt" ;
VAL_ 1624 LV_Abblend_Fernlicht_li_def 0 "OK" 1 "defekt" ;
VAL_ 1624 LV_Abblendlicht_TFL_re_def 0 "OK" 1 "defekt" ;
VAL_ 1624 LV_Nebellicht_TFL_re_def 0 "OK" 1 "defekt" ;
VAL_ 1624 LV_Standlicht_TFL_re_def 0 "OK" 1 "defekt" ;
VAL_ 1624 LV_Abblend_Fernlicht_re_def 0 "OK" 1 "defekt" ;
VAL_ 1624 LV_Abbiegelicht_li_def 0 "OK" 1 "defekt" ;
VAL_ 1624 LV_Abbiegelicht_re_def 0 "OK" 1 "defekt" ;
VAL_ 1624 BCM1_Linksverkehr 0 "Rechtsverkehr" 1 "Linksverkehr" ;
VAL_ 1624 BCM1_Licht_Dunkelheit_aktiv 0 "inaktiv" 1 "aktiv" ;
VAL_ 1624 LV_LED_Scheinwerfer_li_def 0 "OK" 1 "defekt" ;
VAL_ 1624 LV_LED_Scheinwerfer_re_def 0 "OK" 1 "defekt" ;
VAL_ 1624 LV_Blinker_VL_aktiv 0 "inaktiv" 1 "aktiv" ;
VAL_ 1624 LV_Blinker_VR_aktiv 0 "inaktiv" 1 "aktiv" ;
VAL_ 1624 LV_MXB_Status_Anzeige 0 "MXB_aus" 1 "MXB_regelt" 2 "MXB_volles_Fernlicht" 3 "MXB_und_Laser_aktiv" ;
VAL_ 917 AFS_Abbiegelicht_li_Anf 0 "Abbiegelicht_aus" 1 "Abbiegelicht_ein" ;
VAL_ 917 AFS_Abbiegelicht_re_Anf 0 "Abbiegelicht_aus" 1 "Abbiegelicht_ein" ;
VAL_ 917 AFS_Abbiegelicht_Dimm_Anf 0 "Dimmung_angefordert" 1 "keine_Dimmung" ;
VAL_ 917 AFS_Verfuegbarkeit_GLW 0 "GLW_nicht_verfuegbar" 1 "GLW_verfuegbar" ;
VAL_ 917 AFS_Status_adaptive_LV 0 "adaptive_Lichtverteilung_aus" 1 "adaptive_Lichtverteilung_an" ;
VAL_ 917 AFS_Fernlicht_li_defekt 0 "Fernlicht_in_Ordnung" 1 "Fernlicht_defekt" ;
VAL_ 917 AFS_Fernlicht_re_defekt 0 "Fernlicht_in_Ordnung" 1 "Fernlicht_defekt" ;
VAL_ 917 AFS_Fernlicht_Status 0 "Fernlicht_aus" 1 "Fernlicht_ein" ;
VAL_ 917 AFS_Lampe 0 "Aus" 1 "Ein" ;
VAL_ 917 LWR_Lampe 0 "LWR Fehlerlampe aus" 1 "LWR Fehlerlampe ein" ;
VAL_ 917 AFS_Fehlertext 0 "kein Text" 1 "AFS ohne Funktion" ;
VAL_ 917 AFS_LED_Blinkmode 0 "kein Blinkmode angefordert" 1 "Blinkmode angefordert" ;
VAL_ 917 LWR_Touristenmodus_aktiv 0 "Touristenmodus inaktiv" 1 "Touristenmodus aktiv" ;
VAL_ 917 AFS_Charisma_FahrPr 0 "keine_Funktion" 1 "Programm_1" 2 "Programm_2" 3 "Programm_3" 4 "Programm_4" 5 "Programm_5" 6 "Programm_6" 7 "Programm_7" 8 "Programm_8" 9 "Programm_9" 10 "Programm_10" 11 "Programm_11" 12 "Programm_12" 13 "Programm_13" 14 "Programm_14" 15 "Programm_15" ;
VAL_ 917 AFS_Charisma_Status 0 "Init" 1 "verfuegbar" 2 "nicht_verfuegbar" 3 "asynchron_durch_Fahrerwunsch" ;
VAL_ 917 LWR_Sicherheitsposition_re 0 "inaktiv" 1 "aktiv" ;
VAL_ 917 AFS_Allwetterlicht 0 "Allwetterlicht_nicht_aktiv" 1 "Allwetterlicht_aktiv" ;
VAL_ 917 LWR_Touristenmodus_verbaut 0 "Touristenmodus_nicht_verbaut" 1 "Touristenmodus_verbaut" ;
VAL_ 917 AFS_adaptive_LV_verbaut 0 "adaptive_Lichtverteilung_nicht_verbaut" 1 "adaptive_Lichtverteilung_verbaut" ;
VAL_ 917 LWR_Reisemodus_Texte 0 "keine_Anzeige" 1 "Umschaltung_auf_Linksverkehr_aktiv" 2 "Umschaltung_auf_Rechtsverkehr_aktiv" ;
VAL_ 917 GLW_Sensor_blockiert 0 "Kamera_Sensor_nicht_blockiert" 1 "Kamera_Sensor_blockiert" ;
VAL_ 917 AFS_Charisma_Umschaltung 0 "Idle" 1 "Erkennung_Umschaltaufforderung" 2 "Steuerbotschaft_nicht_definiert" 3 "Umschaltung_verzoegert" ;
VAL_ 917 LWR_Pos_Schrittmotor 254 "Init" 255 "Fehler" ;
VAL_ 917 LWR_Hoehenwert_VL 254 "nicht_initialisiert" 255 "Fehler" ;
VAL_ 917 LWR_Hoehenwert_HL 254 "nicht_initialisiert" 255 "Fehler" ;
VAL_ 917 AFS_Ersatzlicht_Links 0 "keine Ersatzlichtfunktion links" 1 "Ersatzlichtfunktion links" ;
VAL_ 917 AFS_Ersatzlicht_Rechts 0 "keine Ersatzlichtfunktion rechts" 1 "Ersatzlichtfunktion rechts" ;
VAL_ 917 LWR_AFS_Grundeinstellung 0 "Grundeinstellung nicht erfolgt" 1 "Grundeinstellung erfolgt" ;
VAL_ 917 LWR_AFS_Parametrisierung 0 "Parametrisierung nicht erfolgt" 1 "Parametrisierung erfolgt" ;
VAL_ 917 LWR_Initialisierungslauf 0 "Initialisierungslauf nicht erfolgt" 1 "Initialisierungslauf erfolgt" ;
VAL_ 917 LWR_Sicherheitsposition_li 0 "inaktiv" 1 "aktiv" ;
VAL_ 917 LWR_Modus 0 "LWR statisch" 1 "LWR dynamisch" ;
VAL_ 1153 ZR_LoGeWa_Event_Kombiwarnung 0 "Init" 1 "Unfall" 2 "Traktionsverlust" 3 "Panne" 4 "Sichtbehinderung" 5 "Aquaplaning" ;
VAL_ 1153 Nav_FoD_Status 0 "Init" 1 "Nav_permanently_available" 2 "FoD_Nav_not_activated" 3 "FoD_Nav_activated" 4 "R4N_Nav_not_activated" ;
VAL_ 1153 MIB_Tongenerator_PH_verfuegbar 0 "Tongenerator_nicht_verfuegbar" 1 "Tongenerator_vorne_verfuegbar" 2 "Tongenerator_hinten_verfuegbar" 3 "Tongenerator_gesamt_verfuegbar" 4 "Tongenerator_im_AMP" ;
VAL_ 1153 DSSS_Warning 0 "No_Warning" 1 "Red_traffic_light_guidance" 2 "Stop_sign_warning" 3 "Rear_end_collision_avoidance_warning" 4 "Intersection_collision_avoidance_warning_right" 5 "Intersection_collision_avoidance_warning_left" 6 "turn_right_collision_avoidance" 7 "turn_left_collision_avoidance" 8 "pedestrian_crossing_right" 9 "pedestrian_crossing_left" 10 "bicycle_collision_right" 11 "bicycle_collision_left" ;
VAL_ 1153 ZR_Kindersicherung_RSE 0 "inaktiv" 1 "aktiv" ;
VAL_ 1153 ZR_RSE_aktivieren 0 "inaktiv" 1 "aktiv" ;
VAL_ 1153 MMI_SDS_aktiv 0 "inaktiv" 1 "aktiv" ;
VAL_ 1153 MU_SecondDisplay 0 "Init" 1 "gueltige_Karte" 2 "ungueltiges_Signal" 3 "Nicht_Verbaut" ;
VAL_ 1153 MMI_Telefon_aktiv 0 "Telefongespraech_nicht_aktiv" 1 "Telefongespraech_aktiv" ;
VAL_ 1153 ZR_Sta_Inszenierung 0 "Init" 1 "Inszenierung_deaktiviert" 2 "Inszenierung_Start" 3 "Inszenierung_Stop" ;
VAL_ 1153 MMI_Gauges_active 0 "gauges_inactive" 1 "gauges_active" ;
VAL_ 1153 ZR_MXB_Manoever_Ansage 0 "keine_Ansage" 1 "Ansage_ohne_Richtung" 2 "Ansage_rechte_Richtung" 3 "Ansage_linke_Richtung" ;
VAL_ 1153 ZR_LAPP_Sondermodus_Status 0 "keine_Anforderung" 1 "Sondermodus_aktiv" 2 "Aktivierung_nicht_moeglich" ;
VAL_ 1153 MMI_StartStopp_Info 0 "Stoppfreigabe" 1 "Stoppverbot" 2 "Startanforderung" 3 "Fehler" ;
VAL_ 1153 ZR_Parken_Sondermodus 0 "Init" 1 "Sondermodus_aktiv" 2 "Sondermodus_nicht_verfuegbar" 3 "WLAN_aus" 4 "WLAN_auscodiert" 15 "keine_WLAN_HW" ;
VAL_ 1153 ZR_Rundenbewertung 0 "Bewertung_nicht_aktiv" 1 "langsamer" 2 "gleich_schnell" 3 "schneller" 4 "reserviert" 5 "reserviert" 6 "reserviert" 7 "reserviert" 8 "reserviert" 9 "reserviert" 10 "reserviert" 11 "reserviert" 12 "reserviert" 13 "reserviert" 14 "Init" 15 "Funktion_nicht_verbaut" ;
VAL_ 1153 ZR_Rundenfortschritt 254 "Init" 255 "Funktion_nicht_verbaut" ;
VAL_ 1600 MO_QBit_Ansaugluft_Temp 0 "gueltiger_Wert" 1 "Ersatz_Init_oder_Fehlerwert" ;
VAL_ 1600 MO_QBit_Oel_Temp 0 "gueltiger_Wert" 1 "Ersatz_Init_oder_Fehlerwert" ;
VAL_ 1600 MO_QBit_Kuehlmittel_Temp 0 "gueltiger_Wert" 1 "Ersatz_Init_oder_Fehlerwert" ;
VAL_ 1600 MO_KL15_Abschaltempfehlung 0 "Keine Empfehlung" 1 "Abschaltempfehlung" ;
VAL_ 1600 MO_HYB_Fehler_HV_Netz 0 "i_O" 1 "kein_generatorischer_Betrieb_moeglich" ;
VAL_ 1600 MO_aktives_Getriebeheizen 0 "kein_Ventil_ansteuern" 1 "Ventil_muss_angesteuert_werden" ;
VAL_ 1600 MO_Absperrventil_oeffnen 0 "nicht_verfuegbar" 1 "Ansteuerung_Ventil_zulaessig" 2 "Ventil_oeffnen_oder_geoeffnet" 3 "Ventil_schliessen_oder_geschlossen" ;
VAL_ 1600 MO_Ansaugluft_Temp 254 "Init" 255 "Fehler" ;
VAL_ 1600 MO_Oel_Temp 253 "nicht_verbaut" 254 "Init" 255 "Fehler" ;
VAL_ 1600 MO_Kuehlmittel_Temp 254 "Init" 255 "Fehler" ;
VAL_ 1600 MO_Hoeheninfo 255 "Fehler" ;
VAL_ 1600 MO_Kennfeldk 0 "keine Kennfeldkühlung vorhanden" 1 "Kennfeldkühlung vorhanden" ;
VAL_ 1600 MO_Versionsinfo_02 0 "zum_Projektbeginn_aufgeraeumter_CAN" 1 "Motor_03_mit_10ms" 16 "MQB_mit_neuer_Momentenschnittstelle" ;
VAL_ 1600 MO_QBit_Hoeheninfo 0 "gueltiger_Wert" 1 "Ersatz_Init_oder_Fehlerwert" ;
VAL_ 1600 MO_Getriebe_kuehlen 0 "nicht_kuehlen" 1 "kuehlen" ;
VAL_ 1600 MO_Heizungspumpenansteuerung 13 "Fehler" 14 "Init" 15 "nicht_verbaut" ;
VAL_ 1600 MO_SpannungsAnf 0 "keine_Anforderung" 1 "Anforderung" ;
VAL_ 167 MO_Mom_Soll_Roh 1022 "Init" ;
VAL_ 167 MO_Mom_Ist_Summe 1022 "Init" ;
VAL_ 167 MO_Mom_Traegheit_Summe 1022 "Init" ;
VAL_ 167 MO_Mom_Soll_gefiltert 1022 "Init" ;
VAL_ 167 MO_Mom_Schub 510 "Init" ;
VAL_ 167 MO_Status_Normalbetrieb_01 0 "kein_Normalbetrieb" 1 "Normalbetrieb_erreicht" ;
VAL_ 167 MO_erste_Ungenauschwelle 0 "genau" 1 "Momente ungenauer >8%" ;
VAL_ 167 MO_QBit_Motormomente 0 "gueltiger_Wert" 1 "Ersatz_Init_oder_Fehlerwert" ;
VAL_ 168 MO_Mom_neg_verfuegbar 510 "Init" 511 "Fehler" ;
VAL_ 168 MO_Mom_Begr_stat 510 "Init" ;
VAL_ 168 MO_Mom_Begr_dyn 1022 "Init" ;
VAL_ 168 MO_QBit_Drehzahl_01 0 "gueltiger_Wert" 1 "Ersatz_Init_oder_Fehlerwert" ;
VAL_ 958 MO_StartStopp_Status 0 "System_in_diesem_KL15_Zyklus_nicht_verfuegbar" 1 "System_aktiv_keine_Freigabe_durch_StartStop_Koordinator" 2 "System_aktiv_alle_Freigaben_liegen_vor" 3 "System_aktiv_mindestens_eine_Freigabe_fehlt" ;
VAL_ 958 MO_StartStopp_Wiederstart 0 "Wiederstart_inaktiv" 1 "Wiederstart_aktiv" ;
VAL_ 958 MO_StartStopp_Motorstopp 0 "Motor_Stop_inaktiv" 1 "Motor_Stop_aktiv" ;
VAL_ 958 MO_Freig_Reku 0 "Rekuperations-Modus aus" 1 "Empfehlung Spannungsanhebung" 2 "Empfehlung Spannungsabsenkung" 3 "Rekuperationsmodus aktiv, Spannungsvariation nicht notwendig" ;
VAL_ 958 MO_Kl_75 0 "Aus" 1 "Ein" ;
VAL_ 958 MO_Kl_50 0 "aus" 1 "KL50_ein_Startausfuehrung_Fahrer" ;
VAL_ 958 MO_Gangposition 0 "Gang_N" 1 "Gang_1" 2 "Gang_2" 3 "Gang_3" 4 "Gang_4" 5 "Gang_5" 6 "Gang_6" 7 "Gang_7" 8 "Gang_8" 9 "Automat_P" 10 "Automat_Vorwaerts_S" 11 "Automat_Vorwaerts_D/E" 12 "Zwischenstellung" 13 "Gang_R" 14 "Istgang_nicht_definiert" 15 "Fehler" ;
VAL_ 958 MO_StartStopp_Fahrerwunsch 0 "Init" 1 "Stoppverbot_durch_Fahrer" 2 "Stoppfreigabe_durch_Fahrer" 3 "Stoppanforderung_durch_Fahrer" ;
VAL_ 958 MO_HYB_Fahrbereitschaft 0 "keine_Fahrbereitschaft" 1 "Fahrbereitschaft" ;
VAL_ 958 MO_Ext_E_Fahrt_aktiv 0 "Rueckmeldung_E_Taster_aus" 1 "Rueckmeldung_E_Taster_ein" ;
VAL_ 958 MO_Fahrer_bremst 0 "kein_Bremsen" 1 "Bremse_betaetigt" ;
VAL_ 958 MO_QBit_Fahrer_bremst 0 "gueltiger_Wert" 1 "Ersatz_Init_oder_Fehlerwert" ;
VAL_ 958 MO_BLS 0 "kein_Bremsen" 1 "Bremse_betaetigt" ;
VAL_ 958 MO_Konsistenz_Bremsped 0 "Bremspedalinformation_plausibel" 1 "Bremspedalinformation_unplausibel" ;
VAL_ 958 MO_KomFehler_ESP 0 "kein_Fehler" 1 "Fehler" ;
VAL_ 958 MO_Klima_Eingr 0 "kein Eingriff" 1 "Klimakompressor ausschalten" 2 "Klimakompressor Leistungsreduzierung" 3 "Klimakompressor aufgrund der Heissleuchtenvorwarnung ausschalten" ;
VAL_ 958 MO_Aussp_Anlass 0 "Anlasser_darf_angesteuert_werden" 1 "Anlasser_ausspuren__Ansteuerung_nicht_moeglich" ;
VAL_ 958 MO_Freig_Anlass 0 "Start_nicht_zulaessig" 1 "Startfreigabe" ;
VAL_ 958 MO_Kuppl_schalter 0 "Schalter_sagt_ausgekuppelt" 1 "Schalter_sagt_eingekuppelt" ;
VAL_ 958 MO_Interlock 0 "Interlockschalter_nicht_betaetigt" 1 "Interlockschalter_betaetigt" ;
VAL_ 958 MO_Motor_laeuft 0 "Motor_laeuft_nicht" 1 "Motor_laeuft_autark_und_stabil_und_darf_mechanisch_belastet_werden" ;
VAL_ 958 MO_Kickdown 0 "kein_Kickdown" 1 "Kickdown" ;
VAL_ 958 MO_QBit_KL_75 0 "gueltiger_Wert" 1 "Ersatz_Init_oder_Fehlerwert" ;
VAL_ 958 MO_EKlKomLeiRed 0 "keine_Leistungsbegr" 1 "Leistungsbegr_75" 2 "Leistungsbegr_50" 3 "Leistungsbegr_25" ;
VAL_ 958 MO_Handshake_STH 0 "keine EKP-Ansteuerung durch STH-Anforderung" 1 "EKP-Ansteuerung durch STH-Anforderung" ;
VAL_ 958 MO_BKV_Unterdruckwarnung 0 "Unterdruckhaushalt_iO" 1 "Unterdruckhaushalt_niO" ;
VAL_ 958 MO_Freigabe_Segeln 0 "Segelbetrieb_nicht_freigegeben" 1 "Segelbetrieb_freigegeben" ;
VAL_ 958 MO_PTC_Status 0 "nicht_unterstuetzt" 1 "Stufe_0" 2 "Stufe_1" 3 "Stufe_2" 4 "Stufe_3" 7 "PTC_am_BCM" ;
VAL_ 958 MO_QBit_Gangposition 0 "gueltiger_Wert" 1 "Ersatz_Init_oder_Fehlerwert" ;
VAL_ 958 MO_Signalquelle_Gangposition 0 "Sensorsignal" 1 "Modellsignal" ;
VAL_ 958 MO_Remotestart_Betrieb 0 "MSG_nicht_bereit_fuer_RS_Betrieb" 1 "MSG_bereit_fuer_oder_im_RS_Betrieb" ;
VAL_ 958 MO_Remotestart_moeglich 0 "Remotestart_nicht_moeglich" 1 "Remotestart_moeglich" ;
VAL_ 958 MO_FMAus_aktiv 0 "inaktiv" 1 "Segeln_mit_Motor_aus_aktiv" ;
VAL_ 958 MO_FMAus_Startvariante 0 "kein_Motorstart" 1 "Motorstart_elektrischer_Starter" 2 "GetriebeAnschleppstart" 3 "GetriebeNotAnschleppstart" ;
VAL_ 958 MO_BMS_NV_Anf_stuetzen 0 "nicht_notwendig" 1 "notwendig" ;
VAL_ 958 MO_Zylinderabschaltung 0 "Vollmotorbetrieb_VMB" 1 "Uebergang_HMB_in_VMB" 2 "Uebergang_VMB_in_HMB" 3 "Halbmotorbetrieb_HMB" ;
VAL_ 958 MO_HYB_VM_aktiv 0 "VM_nicht_aktiv" 1 "VM_aktiv" ;
VAL_ 958 MO_StartVorauss_erfuellt 0 "Signal_nicht_bedient" 1 "StartVorauss_nicht_ueberpruefbar" 2 "StartVorauss_nicht_erfuellt" 3 "StartVorauss_erfuellt" ;
VAL_ 1648 MO_ANC_Kennfeld_Anf 0 "Kennfeld_1" 1 "Uebergang_Kennfeld_2_nach_1" 2 "Uebergang_Kennfeld_1_nach_2" 3 "Kennfeld_2" ;
VAL_ 1648 MO_Bremslicht_Reku 0 "Aus" 1 "Ein" ;
VAL_ 1648 MO_StartStopp_PopUp 0 "Statuswechsel_ohne_Taster (Init)" 1 "StSt_per_Taster_deaktiviert" 2 "StSt_per_Taster_aktiviert" 3 "nicht verwendet" ;
VAL_ 1648 MO1_Sperr_Info_WFS 0 "nicht_gesperrt" 1 "gesperrt" ;
VAL_ 1648 MO1_Freigabe_Info_WFS 0 "ungueltig" 1 "gueltig" ;
VAL_ 1648 MO_EPCL 0 "EPCL_aus_kein_Text" 1 "EPCL_gelb_Stoerung" 2 "EPCL_gelb_Leistungsbeschraenkung" 3 "EPCL_rot_Fzg_sicher_abstellen" ;
VAL_ 1648 MO_Zylabsch_Texte_02 0 "ein_ZAS_generell_keine_ZAS_Anzeigen" 1 "ZAS_im_VMB" 2 "ZAS_im_ASB_1_Zyl_aktiv" 3 "ZAS_im_ASB_2_Zyl_aktiv" 4 "ZAS_im_ASB_3_Zyl_aktiv" 5 "ZAS_im_ASB_4_Zyl_aktiv" 6 "ZAS_im_ASB_5_Zyl_aktiv" 7 "ZAS_im_ASB_6_Zyl_aktiv" 8 "ZAS_im_ASB_8_Zyl_aktiv" 9 "ZAS_im_ASB_12_Zyl_aktiv" 13 "Uebergangsbetrieb" 14 "keine_ZAS_Anzeige_ggf_Stopp_Schub_Betrieb" 15 "ZAS_Stoerungs_Anzeige" ;
VAL_ 1648 MO_Fahrzeugtyp 0 "Verbrenner_Fahrzeug" 1 "Hybrid" 2 "E_Fahrzeug" 3 "E_Fahrzeug_mit_Range_Extender" 4 "Brennstoffzellenfahrzeug" 5 "tbd" 6 "tbd" 7 "tbd" ;
VAL_ 1648 MO_Abstellzeit 254 "Init" 255 "reserviert" ;
VAL_ 1648 MO_Abstellzeit_Status 0 "Abstellzeit_nicht_berechnet" 1 "Abstellzeit_berechnet" 2 "Abstellzeit_Minimalwert" 3 "Abstellzeit_ungueltig" ;
VAL_ 1648 MO1_Freigabe_Verfallsinfo_WFS 0 "verfaellt_nicht" 1 "verfaellt" ;
VAL_ 1648 MO_Hybrid_StartStopp_LED 0 "LED_aus_und_Blinken_aus" 1 "LED_ein_und_Blinken_aus" 2 "LED_ein_und_Blinken_ein_50_percent" 3 "reserviert" ;
VAL_ 1648 MO_Fehler_Zylabsch 0 "kein_Fehler" 1 "Notlauf_Vollmotorbetrieb" 2 "Notlauf_mindestens_einem_abgesch_Zylinder" ;
VAL_ 1648 MO_Anzahl_Abgesch_Zyl 0 "Vollmotorbetrieb" 1 "1_Zylinder_abgeschaltet" 2 "2_Zylinder_abgeschaltet" 3 "3_Zylinder_abgeschaltet" 4 "4_Zylinder_abgeschaltet" 5 "5_Zylinder_abgeschaltet" 6 "6_Zylinder_abgeschaltet" 7 "8_Zylinder_abgeschaltet" ;
VAL_ 1648 MO_Zylabsch_Texte 0 "keine_Texte" 1 "Zylinderabschaltung_deaktivieren" 2 "Zylinderabschaltung_aktivieren" 3 "Zylinderabschaltung_unruhig" ;
VAL_ 1648 MO_Ethanol_BS_Texte 0 "kein_Text" 1 "E85_Warm_Up" 2 "FlexFuel_Warnung_Stufe_3" 3 "Warmfahrempfehlung_MQB__FlexFuel_Warnung_Stufe_1" 4 "FlexFuel_Warnung_Stufe_2" 5 "FlexFuel_Warnung_Stufe_4" 6 "E25_Warm_Up" ;
VAL_ 1648 MO_Drehzahl_Warnung 0 "keinen_Warnhinweis_anzeigen" 1 "Warnhinweis_anzeigen" ;
VAL_ 1648 MO_obere_Drehzahlgrenze 0 "Init" ;
VAL_ 1010 MO_SCR_Heizkreis_3_Leistung 254 "Init" ;
VAL_ 1010 MO_SCR_Tankheizkreis_Leistung 254 "Init" ;
VAL_ 1010 MO_SCR_Heizkreis_3 0 "Heizung_aus" 1 "Heizung_ein" ;
VAL_ 1010 MO_SCR_Tankheizung 0 "Heizung_aus" 1 "Heizung_ein" ;
VAL_ 1010 MO_SCR_Dosierpumpe_Zustand 0 "Pumpe_Stop" 1 "Drehzahlregelung" 2 "Druckregelung_langsam" 3 "Druckregelung_schnell" 4 "frei" 5 "Rueckwaertsbetrieb" 6 "verzoegerter_Rueckwaertsbetrieb" 7 "Pumpe_heizen" ;
VAL_ 1010 MO_SCR_Leitungsheizung 0 "Heizung_aus" 1 "Heizung_ein" ;
VAL_ 1010 MO_SCR_Dosierpumpe_Wartezeit 125 "nicht_verbaut" 126 "Init" 127 "Fehler" ;
VAL_ 1010 MO_SCR_Transferpumpe 0 "Pumpe_aus" 1 "Pumpe_ein" ;
